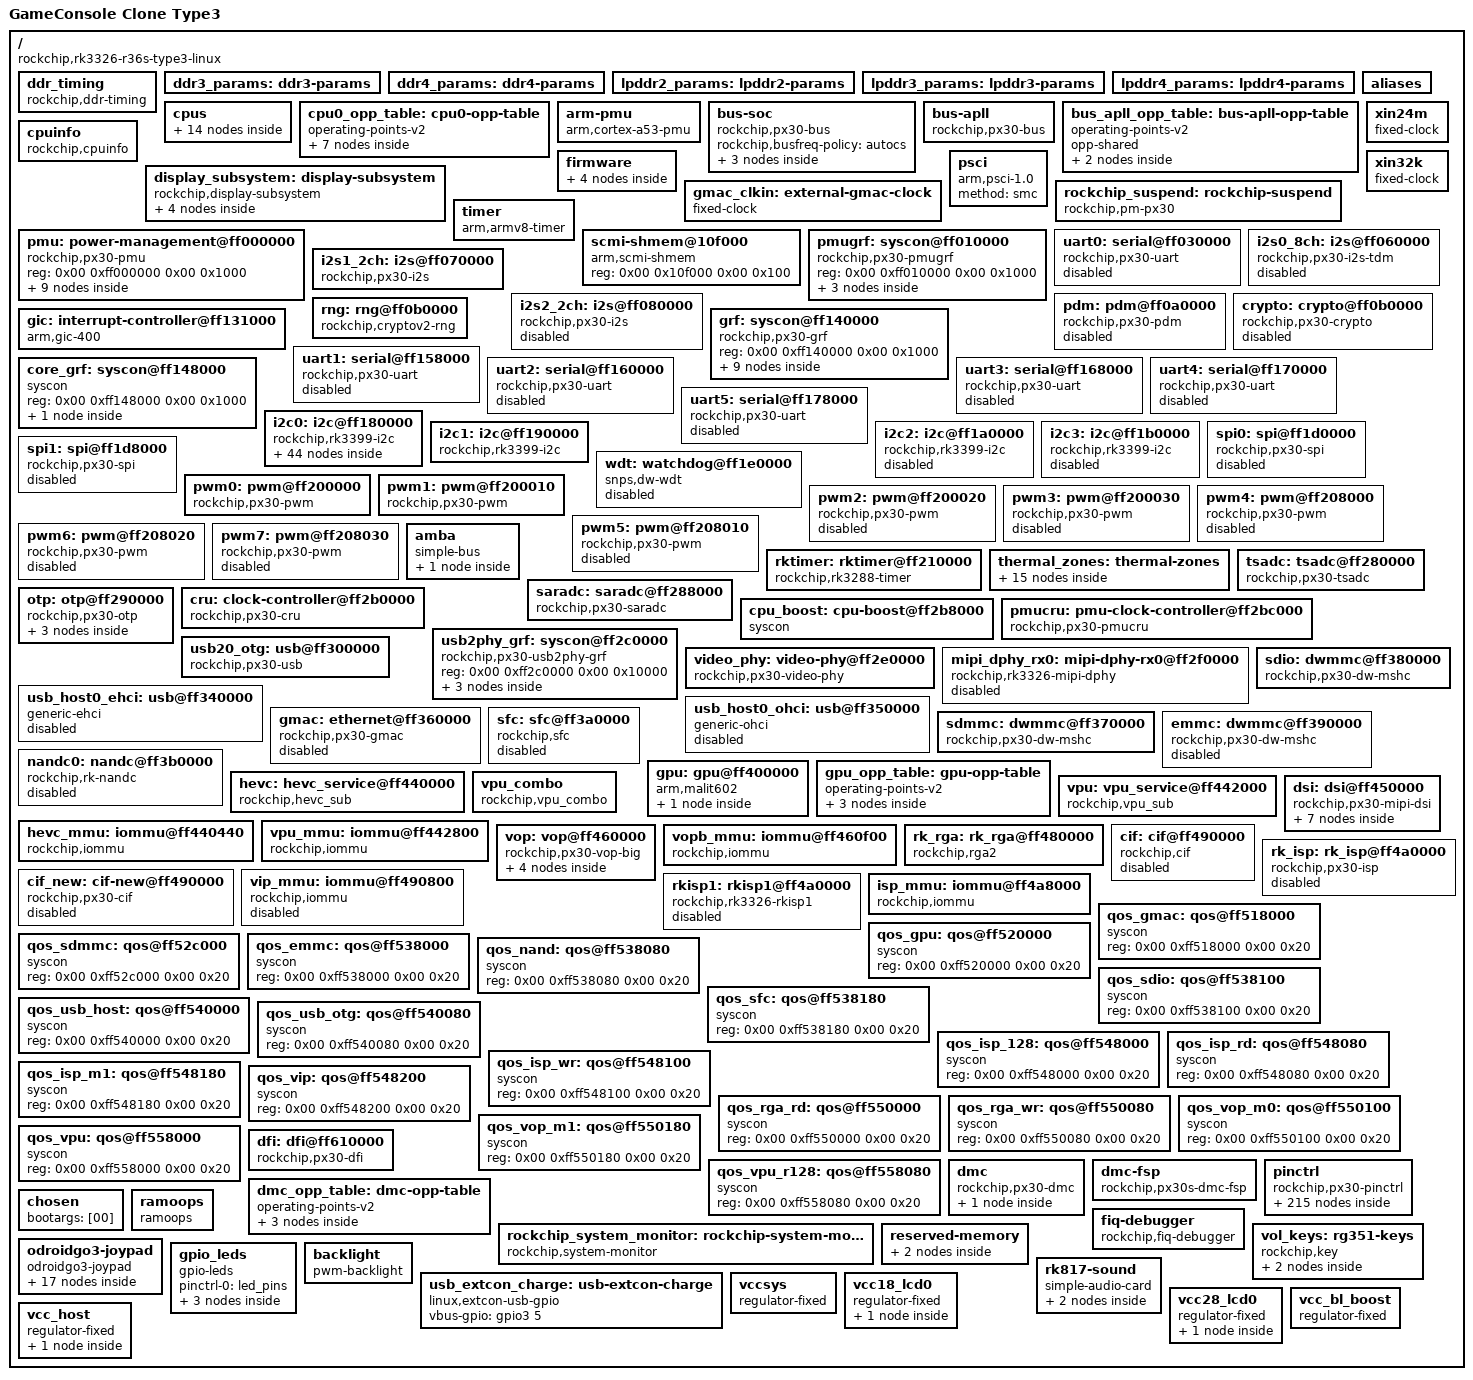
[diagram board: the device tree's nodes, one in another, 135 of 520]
/dts-v1/;

/ {
	compatible = "rockchip,rk3326-r36s-type3-linux", "rockchip,rk3326";
	interrupt-parent = <&gic>;
	#address-cells = <2>;
	#size-cells = <2>;
	model = "GameConsole Clone Type3";
	
	/*chosen {
		stdout-path = "serial5:115200n8";
	};*/

	ddr_timing: ddr_timing {
	compatible = "rockchip,ddr-timing";
		ddr2_speed_bin = <0x00>;
		ddr3_speed_bin = <0x15>;
		ddr4_speed_bin = <0x0c>;
		pd_idle = <0x0d>;
		sr_idle = <0x5d>;
		sr_mc_gate_idle = <0x00>;
		srpd_lite_idle = <0x00>;
		standby_idle = <0x00>;
		auto_pd_dis_freq = <0x42a>;
		auto_sr_dis_freq = <0x320>;
		ddr2_dll_dis_freq = <0x12c>;
		ddr3_dll_dis_freq = <0x12c>;
		ddr4_dll_dis_freq = <0x271>;
		phy_dll_dis_freq = <0x190>;
		ddr2_odt_dis_freq = <0x64>;
		phy_ddr2_odt_dis_freq = <0x64>;
		ddr2_drv = <0x01>;
		ddr2_odt = <0x96>;
		phy_ddr2_ca_drv = <0x15>;
		phy_ddr2_ck_drv = <0x12>;
		phy_ddr2_dq_drv = <0x15>;
		phy_ddr2_odt = <0x02>;
		ddr3_odt_dis_freq = <0x190>;
		phy_ddr3_odt_dis_freq = <0x190>;
		ddr3_drv = <0x28>;
		ddr3_odt = <0x78>;
		phy_ddr3_ca_drv = <0x15>;
		phy_ddr3_ck_drv = <0x12>;
		phy_ddr3_dq_drv = <0x15>;
		phy_ddr3_odt = <0x02>;
		phy_lpddr2_odt_dis_freq = <0x29a>;
		lpddr2_drv = <0x28>;
		phy_lpddr2_ca_drv = <0x16>;
		phy_lpddr2_ck_drv = <0x13>;
		phy_lpddr2_dq_drv = <0x16>;
		phy_lpddr2_odt = <0x00>;
		lpddr3_odt_dis_freq = <0x190>;
		phy_lpddr3_odt_dis_freq = <0x190>;
		lpddr3_drv = <0x28>;
		lpddr3_odt = <0xf0>;
		phy_lpddr3_ca_drv = <0x16>;
		phy_lpddr3_ck_drv = <0x13>;
		phy_lpddr3_dq_drv = <0x16>;
		phy_lpddr3_odt = <0x02>;
		lpddr4_odt_dis_freq = <0x320>;
		phy_lpddr4_odt_dis_freq = <0x320>;
		lpddr4_drv = <0x3c>;
		lpddr4_dq_odt = <0x28>;
		lpddr4_ca_odt = <0x28>;
		phy_lpddr4_ca_drv = <0x14>;
		phy_lpddr4_ck_cs_drv = <0x06>;
		phy_lpddr4_dq_drv = <0x06>;
		phy_lpddr4_odt = <0x10>;
		ddr4_odt_dis_freq = <0x29a>;
		phy_ddr4_odt_dis_freq = <0x29a>;
		ddr4_drv = <0x22>;
		ddr4_odt = <0xf0>;
		phy_ddr4_ca_drv = <0x16>;
		phy_ddr4_ck_drv = <0x13>;
		phy_ddr4_dq_drv = <0x16>;
		phy_ddr4_odt = <0x02>;
		ddr3a1_ddr4a9_de-skew = <0x06>;
		ddr3a0_ddr4a10_de-skew = <0x07>;
		ddr3a3_ddr4a6_de-skew = <0x07>;
		ddr3a2_ddr4a4_de-skew = <0x07>;
		ddr3a5_ddr4a8_de-skew = <0x07>;
		ddr3a4_ddr4a5_de-skew = <0x07>;
		ddr3a7_ddr4a11_de-skew = <0x07>;
		ddr3a6_ddr4a7_de-skew = <0x06>;
		ddr3a9_ddr4a0_de-skew = <0x07>;
		ddr3a8_ddr4a13_de-skew = <0x07>;
		ddr3a11_ddr4a3_de-skew = <0x07>;
		ddr3a10_ddr4cs0_de-skew = <0x07>;
		ddr3a13_ddr4a2_de-skew = <0x07>;
		ddr3a12_ddr4ba1_de-skew = <0x07>;
		ddr3a15_ddr4odt0_de-skew = <0x07>;
		ddr3a14_ddr4a1_de-skew = <0x07>;
		ddr3ba1_ddr4a15_de-skew = <0x07>;
		ddr3ba0_ddr4bg0_de-skew = <0x07>;
		ddr3ras_ddr4cke_de-skew = <0x07>;
		ddr3ba2_ddr4ba0_de-skew = <0x07>;
		ddr3we_ddr4bg1_de-skew = <0x07>;
		ddr3cas_ddr4a12_de-skew = <0x07>;
		ddr3ckn_ddr4ckn_de-skew = <0x07>;
		ddr3ckp_ddr4ckp_de-skew = <0x07>;
		ddr3cke_ddr4a16_de-skew = <0x07>;
		ddr3odt0_ddr4a14_de-skew = <0x07>;
		ddr3cs0_ddr4act_de-skew = <0x06>;
		ddr3reset_ddr4reset_de-skew = <0x07>;
		ddr3cs1_ddr4cs1_de-skew = <0x06>;
		ddr3odt1_ddr4odt1_de-skew = <0x07>;
		cs0_dm0_rx_de-skew = <0x07>;
		cs0_dm0_tx_de-skew = <0x07>;
		cs0_dq0_rx_de-skew = <0x08>;
		cs0_dq0_tx_de-skew = <0x08>;
		cs0_dq1_rx_de-skew = <0x09>;
		cs0_dq1_tx_de-skew = <0x08>;
		cs0_dq2_rx_de-skew = <0x08>;
		cs0_dq2_tx_de-skew = <0x08>;
		cs0_dq3_rx_de-skew = <0x08>;
		cs0_dq3_tx_de-skew = <0x08>;
		cs0_dq4_rx_de-skew = <0x09>;
		cs0_dq4_tx_de-skew = <0x08>;
		cs0_dq5_rx_de-skew = <0x09>;
		cs0_dq5_tx_de-skew = <0x08>;
		cs0_dq6_rx_de-skew = <0x09>;
		cs0_dq6_tx_de-skew = <0x08>;
		cs0_dq7_rx_de-skew = <0x08>;
		cs0_dq7_tx_de-skew = <0x08>;
		cs0_dqs0_rx_de-skew = <0x06>;
		cs0_dqs0p_tx_de-skew = <0x09>;
		cs0_dqs0n_tx_de-skew = <0x09>;
		cs0_dm1_rx_de-skew = <0x07>;
		cs0_dm1_tx_de-skew = <0x06>;
		cs0_dq8_rx_de-skew = <0x08>;
		cs0_dq8_tx_de-skew = <0x07>;
		cs0_dq9_rx_de-skew = <0x09>;
		cs0_dq9_tx_de-skew = <0x07>;
		cs0_dq10_rx_de-skew = <0x08>;
		cs0_dq10_tx_de-skew = <0x08>;
		cs0_dq11_rx_de-skew = <0x08>;
		cs0_dq11_tx_de-skew = <0x07>;
		cs0_dq12_rx_de-skew = <0x08>;
		cs0_dq12_tx_de-skew = <0x08>;
		cs0_dq13_rx_de-skew = <0x09>;
		cs0_dq13_tx_de-skew = <0x07>;
		cs0_dq14_rx_de-skew = <0x09>;
		cs0_dq14_tx_de-skew = <0x08>;
		cs0_dq15_rx_de-skew = <0x09>;
		cs0_dq15_tx_de-skew = <0x07>;
		cs0_dqs1_rx_de-skew = <0x07>;
		cs0_dqs1p_tx_de-skew = <0x09>;
		cs0_dqs1n_tx_de-skew = <0x09>;
		cs0_dm2_rx_de-skew = <0x07>;
		cs0_dm2_tx_de-skew = <0x07>;
		cs0_dq16_rx_de-skew = <0x09>;
		cs0_dq16_tx_de-skew = <0x09>;
		cs0_dq17_rx_de-skew = <0x07>;
		cs0_dq17_tx_de-skew = <0x09>;
		cs0_dq18_rx_de-skew = <0x07>;
		cs0_dq18_tx_de-skew = <0x08>;
		cs0_dq19_rx_de-skew = <0x07>;
		cs0_dq19_tx_de-skew = <0x09>;
		cs0_dq20_rx_de-skew = <0x09>;
		cs0_dq20_tx_de-skew = <0x09>;
		cs0_dq21_rx_de-skew = <0x09>;
		cs0_dq21_tx_de-skew = <0x09>;
		cs0_dq22_rx_de-skew = <0x08>;
		cs0_dq22_tx_de-skew = <0x09>;
		cs0_dq23_rx_de-skew = <0x08>;
		cs0_dq23_tx_de-skew = <0x09>;
		cs0_dqs2_rx_de-skew = <0x06>;
		cs0_dqs2p_tx_de-skew = <0x09>;
		cs0_dqs2n_tx_de-skew = <0x09>;
		cs0_dm3_rx_de-skew = <0x07>;
		cs0_dm3_tx_de-skew = <0x07>;
		cs0_dq24_rx_de-skew = <0x08>;
		cs0_dq24_tx_de-skew = <0x08>;
		cs0_dq25_rx_de-skew = <0x09>;
		cs0_dq25_tx_de-skew = <0x09>;
		cs0_dq26_rx_de-skew = <0x09>;
		cs0_dq26_tx_de-skew = <0x08>;
		cs0_dq27_rx_de-skew = <0x09>;
		cs0_dq27_tx_de-skew = <0x08>;
		cs0_dq28_rx_de-skew = <0x09>;
		cs0_dq28_tx_de-skew = <0x09>;
		cs0_dq29_rx_de-skew = <0x09>;
		cs0_dq29_tx_de-skew = <0x09>;
		cs0_dq30_rx_de-skew = <0x08>;
		cs0_dq30_tx_de-skew = <0x08>;
		cs0_dq31_rx_de-skew = <0x08>;
		cs0_dq31_tx_de-skew = <0x08>;
		cs0_dqs3_rx_de-skew = <0x07>;
		cs0_dqs3p_tx_de-skew = <0x09>;
		cs0_dqs3n_tx_de-skew = <0x09>;
		cs1_dm0_rx_de-skew = <0x07>;
		cs1_dm0_tx_de-skew = <0x07>;
		cs1_dq0_rx_de-skew = <0x08>;
		cs1_dq0_tx_de-skew = <0x08>;
		cs1_dq1_rx_de-skew = <0x09>;
		cs1_dq1_tx_de-skew = <0x08>;
		cs1_dq2_rx_de-skew = <0x08>;
		cs1_dq2_tx_de-skew = <0x08>;
		cs1_dq3_rx_de-skew = <0x08>;
		cs1_dq3_tx_de-skew = <0x08>;
		cs1_dq4_rx_de-skew = <0x08>;
		cs1_dq4_tx_de-skew = <0x08>;
		cs1_dq5_rx_de-skew = <0x09>;
		cs1_dq5_tx_de-skew = <0x08>;
		cs1_dq6_rx_de-skew = <0x09>;
		cs1_dq6_tx_de-skew = <0x08>;
		cs1_dq7_rx_de-skew = <0x08>;
		cs1_dq7_tx_de-skew = <0x08>;
		cs1_dqs0_rx_de-skew = <0x06>;
		cs1_dqs0p_tx_de-skew = <0x09>;
		cs1_dqs0n_tx_de-skew = <0x09>;
		cs1_dm1_rx_de-skew = <0x07>;
		cs1_dm1_tx_de-skew = <0x07>;
		cs1_dq8_rx_de-skew = <0x08>;
		cs1_dq8_tx_de-skew = <0x08>;
		cs1_dq9_rx_de-skew = <0x08>;
		cs1_dq9_tx_de-skew = <0x07>;
		cs1_dq10_rx_de-skew = <0x07>;
		cs1_dq10_tx_de-skew = <0x08>;
		cs1_dq11_rx_de-skew = <0x08>;
		cs1_dq11_tx_de-skew = <0x08>;
		cs1_dq12_rx_de-skew = <0x08>;
		cs1_dq12_tx_de-skew = <0x07>;
		cs1_dq13_rx_de-skew = <0x08>;
		cs1_dq13_tx_de-skew = <0x08>;
		cs1_dq14_rx_de-skew = <0x08>;
		cs1_dq14_tx_de-skew = <0x08>;
		cs1_dq15_rx_de-skew = <0x08>;
		cs1_dq15_tx_de-skew = <0x07>;
		cs1_dqs1_rx_de-skew = <0x07>;
		cs1_dqs1p_tx_de-skew = <0x09>;
		cs1_dqs1n_tx_de-skew = <0x09>;
		cs1_dm2_rx_de-skew = <0x07>;
		cs1_dm2_tx_de-skew = <0x08>;
		cs1_dq16_rx_de-skew = <0x08>;
		cs1_dq16_tx_de-skew = <0x09>;
		cs1_dq17_rx_de-skew = <0x08>;
		cs1_dq17_tx_de-skew = <0x09>;
		cs1_dq18_rx_de-skew = <0x07>;
		cs1_dq18_tx_de-skew = <0x08>;
		cs1_dq19_rx_de-skew = <0x08>;
		cs1_dq19_tx_de-skew = <0x09>;
		cs1_dq20_rx_de-skew = <0x09>;
		cs1_dq20_tx_de-skew = <0x09>;
		cs1_dq21_rx_de-skew = <0x09>;
		cs1_dq21_tx_de-skew = <0x09>;
		cs1_dq22_rx_de-skew = <0x08>;
		cs1_dq22_tx_de-skew = <0x09>;
		cs1_dq23_rx_de-skew = <0x08>;
		cs1_dq23_tx_de-skew = <0x09>;
		cs1_dqs2_rx_de-skew = <0x06>;
		cs1_dqs2p_tx_de-skew = <0x09>;
		cs1_dqs2n_tx_de-skew = <0x09>;
		cs1_dm3_rx_de-skew = <0x07>;
		cs1_dm3_tx_de-skew = <0x07>;
		cs1_dq24_rx_de-skew = <0x08>;
		cs1_dq24_tx_de-skew = <0x09>;
		cs1_dq25_rx_de-skew = <0x09>;
		cs1_dq25_tx_de-skew = <0x09>;
		cs1_dq26_rx_de-skew = <0x09>;
		cs1_dq26_tx_de-skew = <0x08>;
		cs1_dq27_rx_de-skew = <0x08>;
		cs1_dq27_tx_de-skew = <0x08>;
		cs1_dq28_rx_de-skew = <0x09>;
		cs1_dq28_tx_de-skew = <0x09>;
		cs1_dq29_rx_de-skew = <0x09>;
		cs1_dq29_tx_de-skew = <0x09>;
		cs1_dq30_rx_de-skew = <0x09>;
		cs1_dq30_tx_de-skew = <0x08>;
		cs1_dq31_rx_de-skew = <0x08>;
		cs1_dq31_tx_de-skew = <0x08>;
		cs1_dqs3_rx_de-skew = <0x07>;
		cs1_dqs3p_tx_de-skew = <0x09>;
		cs1_dqs3n_tx_de-skew = <0x09>;
		//phandle = <0xb4>;
	};

	ddr3_params: ddr3-params {
		version = <0x101>;
		expanded_version = <0x00>;
		reserved = <0x00>;
		freq_0 = <0x210>;
		freq_1 = <0x148>;
		freq_2 = <0x210>;
		freq_3 = <0x210>;
		freq_4 = <0x00>;
		freq_5 = <0x00>;
		pd_idle = <0x0d>;
		sr_idle = <0x5d>;
		sr_mc_gate_idle = <0x00>;
		srpd_lite_idle = <0x00>;
		standby_idle = <0x00>;
		pd_dis_freq = <0x42a>;
		sr_dis_freq = <0x320>;
		dram_dll_dis_freq = <0x12c>;
		phy_dll_dis_freq = <0x00>;
		phy_dq_drv_odten = <0x21>;
		phy_ca_drv_odten = <0x21>;
		phy_clk_drv_odten = <0x21>;
		dram_dq_drv_odten = <0x22>;
		phy_dq_drv_odtoff = <0x21>;
		phy_ca_drv_odtoff = <0x21>;
		phy_clk_drv_odtoff = <0x21>;
		dram_dq_drv_odtoff = <0x22>;
		dram_odt = <0x78>;
		phy_odt = <0x85>;
		phy_odt_puup_en = <0x01>;
		phy_odt_pudn_en = <0x01>;
		dram_dq_odt_en_freq = <0x14d>;
		phy_odt_en_freq = <0x14d>;
		phy_dq_sr_odten = <0x0f>;
		phy_ca_sr_odten = <0x03>;
		phy_clk_sr_odten = <0x03>;
		phy_dq_sr_odtoff = <0x0f>;
		phy_ca_sr_odtoff = <0x03>;
		phy_clk_sr_odtoff = <0x03>;
		ssmod_downspread = <0x00>;
		ssmod_div = <0x00>;
		ssmod_spread = <0x00>;
		mode_2t = <0x00>;
		speed_bin = <0x15>;
		dram_ext_temp = <0x00>;
		byte_map = <0xb1>;
		dq_map_cs0_dq_l = <0x00>;
		dq_map_cs0_dq_h = <0x00>;
		dq_map_cs1_dq_l = <0x00>;
		dq_map_cs1_dq_h = <0x00>;
		//phandle = <0xb2>;
	};

	ddr4_params: ddr4-params {
		version = <0x101>;
		expanded_version = <0x00>;
		reserved = <0x00>;
		freq_0 = <0x312>;
		freq_1 = <0x148>;
		freq_2 = <0x29a>;
		freq_3 = <0x312>;
		freq_4 = <0x00>;
		freq_5 = <0x00>;
		pd_idle = <0x0d>;
		sr_idle = <0x5d>;
		sr_mc_gate_idle = <0x00>;
		srpd_lite_idle = <0x00>;
		standby_idle = <0x00>;
		pd_dis_freq = <0x42a>;
		sr_dis_freq = <0x320>;
		dram_dll_dis_freq = <0x1f4>;
		phy_dll_dis_freq = <0x00>;
		phy_dq_drv_odten = <0x21>;
		phy_ca_drv_odten = <0x21>;
		phy_clk_drv_odten = <0x21>;
		dram_dq_drv_odten = <0x22>;
		phy_dq_drv_odtoff = <0x21>;
		phy_ca_drv_odtoff = <0x21>;
		phy_clk_drv_odtoff = <0x21>;
		dram_dq_drv_odtoff = <0x22>;
		dram_odt = <0x78>;
		phy_odt = <0x79>;
		phy_odt_puup_en = <0x01>;
		phy_odt_pudn_en = <0x01>;
		dram_dq_odt_en_freq = <0x1f4>;
		phy_odt_en_freq = <0x1f4>;
		phy_dq_sr_odten = <0x0e>;
		phy_ca_sr_odten = <0x01>;
		phy_clk_sr_odten = <0x01>;
		phy_dq_sr_odtoff = <0x0e>;
		phy_ca_sr_odtoff = <0x01>;
		phy_clk_sr_odtoff = <0x01>;
		ssmod_downspread = <0x00>;
		ssmod_div = <0x00>;
		ssmod_spread = <0x00>;
		mode_2t = <0x00>;
		speed_bin = <0x0c>;
		dram_ext_temp = <0x00>;
		byte_map = <0xb1>;
		dq_map_cs0_dq_l = <0x139b6273>;
		dq_map_cs0_dq_h = <0x272d6f42>;
		dq_map_cs1_dq_l = <0x46ce3726>;
		dq_map_cs1_dq_h = <0x72783a17>;
		//phandle = <0xb3>;
	};

	lpddr2_params: lpddr2-params {
		version = <0x101>;
		expanded_version = <0x00>;
		reserved = <0x00>;
		freq_0 = <0x210>;
		freq_1 = <0x148>;
		freq_2 = <0x1c2>;
		freq_3 = <0x210>;
		freq_4 = <0x00>;
		freq_5 = <0x00>;
		pd_idle = <0x0d>;
		sr_idle = <0x5d>;
		sr_mc_gate_idle = <0x00>;
		srpd_lite_idle = <0x00>;
		standby_idle = <0x00>;
		pd_dis_freq = <0x42a>;
		sr_dis_freq = <0x320>;
		dram_dll_dis_freq = <0x00>;
		phy_dll_dis_freq = <0x00>;
		phy_dq_drv_odten = <0x21>;
		phy_ca_drv_odten = <0x21>;
		phy_clk_drv_odten = <0x21>;
		dram_dq_drv_odten = <0x22>;
		phy_dq_drv_odtoff = <0x21>;
		phy_ca_drv_odtoff = <0x21>;
		phy_clk_drv_odtoff = <0x21>;
		dram_dq_drv_odtoff = <0x22>;
		dram_odt = <0x00>;
		phy_odt = <0x00>;
		phy_odt_puup_en = <0x00>;
		phy_odt_pudn_en = <0x00>;
		dram_dq_odt_en_freq = <0x271>;
		phy_odt_en_freq = <0x271>;
		phy_dq_sr_odten = <0x0e>;
		phy_ca_sr_odten = <0x01>;
		phy_clk_sr_odten = <0x01>;
		phy_dq_sr_odtoff = <0x0e>;
		phy_ca_sr_odtoff = <0x01>;
		phy_clk_sr_odtoff = <0x01>;
		ssmod_downspread = <0x00>;
		ssmod_div = <0x00>;
		ssmod_spread = <0x00>;
		mode_2t = <0x00>;
		speed_bin = <0x00>;
		dram_ext_temp = <0x00>;
		byte_map = <0xe4>;
		dq_map_cs0_dq_l = <0x00>;
		dq_map_cs0_dq_h = <0x00>;
		dq_map_cs1_dq_l = <0x00>;
		dq_map_cs1_dq_h = <0x00>;
		//phandle = <0xb4>;
	};

	lpddr3_params: lpddr3-params {
		version = <0x101>;
		expanded_version = <0x00>;
		reserved = <0x00>;
		freq_0 = <0x210>;
		freq_1 = <0x148>;
		freq_2 = <0x210>;
		freq_3 = <0x210>;
		freq_4 = <0x00>;
		freq_5 = <0x00>;
		pd_idle = <0x0d>;
		sr_idle = <0x5d>;
		sr_mc_gate_idle = <0x00>;
		srpd_lite_idle = <0x00>;
		standby_idle = <0x00>;
		pd_dis_freq = <0x42a>;
		sr_dis_freq = <0x320>;
		dram_dll_dis_freq = <0x00>;
		phy_dll_dis_freq = <0x00>;
		phy_dq_drv_odten = <0x21>;
		phy_ca_drv_odten = <0x21>;
		phy_clk_drv_odten = <0x21>;
		dram_dq_drv_odten = <0x22>;
		phy_dq_drv_odtoff = <0x21>;
		phy_ca_drv_odtoff = <0x21>;
		phy_clk_drv_odtoff = <0x21>;
		dram_dq_drv_odtoff = <0x22>;
		dram_odt = <0xf0>;
		phy_odt = <0x79>;
		phy_odt_puup_en = <0x01>;
		phy_odt_pudn_en = <0x01>;
		dram_dq_odt_en_freq = <0x14d>;
		phy_odt_en_freq = <0x14d>;
		phy_dq_sr_odten = <0x00>;
		phy_ca_sr_odten = <0x00>;
		phy_clk_sr_odten = <0x00>;
		phy_dq_sr_odtoff = <0x00>;
		phy_ca_sr_odtoff = <0x00>;
		phy_clk_sr_odtoff = <0x00>;
		ssmod_downspread = <0x00>;
		ssmod_div = <0x00>;
		ssmod_spread = <0x00>;
		mode_2t = <0x00>;
		speed_bin = <0x00>;
		dram_ext_temp = <0x00>;
		byte_map = <0xe4>;
		dq_map_cs0_dq_l = <0x00>;
		dq_map_cs0_dq_h = <0x00>;
		dq_map_cs1_dq_l = <0x00>;
		dq_map_cs1_dq_h = <0x00>;
		//phandle = <0xb5>;
	};

	lpddr4_params: lpddr4-params {
		version = <0x101>;
		expanded_version = <0x00>;
		reserved = <0x00>;
		freq_0 = <0x312>;
		freq_1 = <0x148>;
		freq_2 = <0x29a>;
		freq_3 = <0x312>;
		freq_4 = <0x00>;
		freq_5 = <0x00>;
		pd_idle = <0x0d>;
		sr_idle = <0x5d>;
		sr_mc_gate_idle = <0x00>;
		srpd_lite_idle = <0x00>;
		standby_idle = <0x00>;
		pd_dis_freq = <0x42a>;
		sr_dis_freq = <0x320>;
		dram_dll_dis_freq = <0x00>;
		phy_dll_dis_freq = <0x00>;
		phy_dq_drv_odten = <0x23>;
		phy_ca_drv_odten = <0x26>;
		phy_clk_drv_odten = <0x2f>;
		dram_dq_drv_odten = <0x28>;
		phy_dq_drv_odtoff = <0x23>;
		phy_ca_drv_odtoff = <0x26>;
		phy_clk_drv_odtoff = <0x2f>;
		dram_dq_drv_odtoff = <0x28>;
		dram_odt = <0x3c>;
		phy_odt = <0x50>;
		phy_odt_puup_en = <0x00>;
		phy_odt_pudn_en = <0x00>;
		dram_dq_odt_en_freq = <0x320>;
		phy_odt_en_freq = <0x320>;
		phy_dq_sr_odten = <0x0f>;
		phy_ca_sr_odten = <0x01>;
		phy_clk_sr_odten = <0x01>;
		phy_dq_sr_odtoff = <0x0f>;
		phy_ca_sr_odtoff = <0x01>;
		phy_clk_sr_odtoff = <0x01>;
		ssmod_downspread = <0x00>;
		ssmod_div = <0x00>;
		ssmod_spread = <0x00>;
		mode_2t = <0x00>;
		speed_bin = <0x00>;
		dram_ext_temp = <0x00>;
		byte_map = <0xe4>;
		dq_map_cs0_dq_l = <0x00>;
		dq_map_cs0_dq_h = <0x00>;
		dq_map_cs1_dq_l = <0x00>;
		dq_map_cs1_dq_h = <0x00>;
		lp4_ca_odt = <0x78>;
		lp4_drv_pu_cal_odten = <0x00>;
		lp4_drv_pu_cal_odtoff = <0x00>;
		phy_lp4_drv_pulldown_en_odten = <0x00>;
		phy_lp4_drv_pulldown_en_odtoff = <0x00>;
		lp4_ca_odt_en_freq = <0x320>;
		phy_lp4_cs_drv_odten = <0x00>;
		phy_lp4_cs_drv_odtoff = <0x00>;
		lp4_odte_ck_en = <0x01>;
		lp4_odte_cs_en = <0x01>;
		lp4_odtd_ca_en = <0x00>;
		phy_lp4_dq_vref_odten = <0xc8>;
		lp4_dq_vref_odten = <0x13c>;
		lp4_ca_vref_odten = <0x17c>;
		phy_lp4_dq_vref_odtoff = <0x12c>;
		lp4_dq_vref_odtoff = <0x1a4>;
		lp4_ca_vref_odtoff = <0x1a4>;
		//phandle = <0xb6>;
	};

	aliases {
		ethernet0 = "/ethernet@ff360000";
		i2c0 = "/i2c@ff180000";
		i2c1 = "/i2c@ff190000";
		i2c2 = "/i2c@ff1a0000";
		i2c3 = "/i2c@ff1b0000";
		serial0 = "/serial@ff030000";
		serial1 = "/serial@ff158000";
		serial2 = "/serial@ff160000";
		//serial3 = "/serial@ff168000";
		//serial4 = "/serial@ff170000";
		serial5 = "/serial@ff178000";
		spi0 = "/spi@ff1d0000";
		spi1 = "/spi@ff1d8000";
		mmc0 = "/dwmmc@ff370000";
		mmc1 = "/dwmmc@ff380000";
	};

	cpus {
		#address-cells = <2>;
		#size-cells = <0>;
		cpu-map {
			cluster0 {	/* Cortex-A35 */
					core0 {
						cpu = <&cpu0>;
					};
					core1 {
						cpu = <&cpu1>;
					};
					core2 {
						cpu = <&cpu2>;
					};
					core3 {
						cpu = <&cpu3>;
					};
			};
		};
		
		cpu0: cpu@0 {//256KB unified system L2 cache, Integrated 32KB L1 instruction cache, 32KB L1 data cache with 4-way set associative
			device_type = "cpu";
			compatible = "arm,cortex-a35", "arm,armv8";
			reg = <0x00 0x00>;
			enable-method = "psci";
			i-cache-size = <0x8000>;
			i-cache-line-size = <64>;
			i-cache-sets = <256>;
			d-cache-size = <0x8000>;
			d-cache-line-size = <64>;
			d-cache-sets = <128>;
			next-level-cache = <&l2_0>;
			clocks = <&cru 0x07>;
			#cooling-cells = <2>;
			dynamic-power-coefficient = <90>;
			operating-points-v2 = <&cpu0_opp_table>;
			cpu-idle-states = <&CPU_SLEEP &CLUSTER_SLEEP>;
			cpu-supply = <&vdd_arm>;
			//phandle = <0x09>;
		};

		cpu1: cpu@1 {
			device_type = "cpu";
			compatible = "arm,cortex-a35", "arm,armv8";
			reg = <0x00 0x01>;
			enable-method = "psci";
			i-cache-size = <0x8000>;
			i-cache-line-size = <64>;
			i-cache-sets = <256>;
			d-cache-size = <0x8000>;
			d-cache-line-size = <64>;
			d-cache-sets = <128>;
			next-level-cache = <&l2_0>;
			//clocks = <&cru 0x07>;
			//#cooling-cells = <2>;
			//dynamic-power-coefficient = <90>;
			operating-points-v2 = <&cpu0_opp_table>;
			cpu-idle-states = <&CPU_SLEEP &CLUSTER_SLEEP>;
			cpu-supply = <&vdd_arm>;
			//phandle = <0x0a>;
		};

		cpu2: cpu@2 {
			device_type = "cpu";
			compatible = "arm,cortex-a35", "arm,armv8";
			reg = <0x00 0x02>;
			enable-method = "psci";
			i-cache-size = <0x8000>;
			i-cache-line-size = <64>;
			i-cache-sets = <256>;
			d-cache-size = <0x8000>;
			d-cache-line-size = <64>;
			d-cache-sets = <128>;
			next-level-cache = <&l2_0>;
			//clocks = <&cru 0x07>;
			//#cooling-cells = <2>;
			//dynamic-power-coefficient = <90>;
			operating-points-v2 = <&cpu0_opp_table>;
			cpu-idle-states = <&CPU_SLEEP &CLUSTER_SLEEP>;
			cpu-supply = <&vdd_arm>;
			//phandle = <0x0b>;
		};

		cpu3: cpu@3 {
			device_type = "cpu";
			compatible = "arm,cortex-a35", "arm,armv8";
			reg = <0x00 0x03>;
			enable-method = "psci";
			i-cache-size = <0x8000>;
			i-cache-line-size = <64>;
			i-cache-sets = <256>;
			d-cache-size = <0x8000>;
			d-cache-line-size = <64>;
			d-cache-sets = <128>;
			next-level-cache = <&l2_0>;
			//clocks = <&cru 0x07>;
			//#cooling-cells = <2>;
			//dynamic-power-coefficient = <90>;
			operating-points-v2 = <&cpu0_opp_table>;
			cpu-idle-states = <&CPU_SLEEP &CLUSTER_SLEEP>;
			cpu-supply = <&vdd_arm>;
			//phandle = <0x0c>;
		};

		l2_0: l2-cache {
			compatible = "cache,arm,arch-cache";
			cache-level = <2>;
			cache-unified;
			cache-size = <0x40000>;
			cache-line-size = <64>;
			cache-sets = <256>;
		};

		idle-states {
			entry-method = "psci";

			CPU_SLEEP: cpu-sleep {
				compatible = "arm,idle-state";
				local-timer-stop;
				arm,psci-suspend-param = <0x10000>;
				entry-latency-us = <0x78>;
				exit-latency-us = <0xfa>;
				min-residency-us = <0x384>;
				//phandle = <0x04>;
			};

			CLUSTER_SLEEP: cluster-sleep {
				compatible = "arm,idle-state";
				local-timer-stop;
				arm,psci-suspend-param = <0x1010000>;
				entry-latency-us = <0x190>;
				exit-latency-us = <0x1f4>;
				min-residency-us = <0x7d0>;
				//phandle = <0x05>;
			};
		};
	};

	cpu0_opp_table: cpu0-opp-table {
		compatible = "operating-points-v2";
		opp-shared;
		rockchip,temp-hysteresis = <0x1388>;
		rockchip,low-temp = <0x00>;
		rockchip,low-temp-min-volt = <1000000>;
		rockchip,low-temp-adjust-volt = <0x00 0x5e8 0xc350>;
		clocks = <&cru 0x01>;
		rockchip,avs-scale = <0x04>;
		rockchip,max-volt = <1350000>;
		rockchip,evb-irdrop = <25000>;
		nvmem-cells = <&cpu_leakage &performance>;
		nvmem-cell-names = "cpu_leakage", "performance";
		/* bin scaling clock 1.296MHz */
		rockchip,bin-scaling-sel = <0 13 1 13>;// 0x02 0x12>;
		rockchip,pvtm-voltage-sel = <0x00 0xc350 0x00 0xc351 0xd2f0 0x01 0xd2f1 0xea60 0x02 0xea61 0x1869f 0x03>;
		rockchip,pvtm-freq = <0x639c0>;
		rockchip,pvtm-volt = <1000000>;
		rockchip,pvtm-ch = <0x00 0x00>;
		rockchip,pvtm-sample-time = <0x3e8>;
		rockchip,pvtm-number = <0x0a>;
		rockchip,pvtm-error = <0x3e8>;
		rockchip,pvtm-ref-temp = <0x28>;
		rockchip,pvtm-temp-prop = <0xffffffc8 0xffffffc8>;
		rockchip,thermal-zone = "soc-thermal";
		rockchip,avs = <1>;
		//phandle = <0x03>;

		opp-408000000 {
			opp-hz = <0x00 0x18519600>;
			opp-microvolt = <950000 950000 1350000>;
			opp-microvolt-L0 = <950000 950000 1350000>;
			opp-microvolt-L1 = <950000 950000 1350000>;
			opp-microvolt-L2 = <950000 950000 1350000>;
			opp-microvolt-L3 = <950000 950000 1350000>;
			clock-latency-ns = <40000>;
			//opp-suspend;
		};

		opp-600000000 {
			opp-hz = <0x00 0x23c34600>;
			opp-microvolt = <950000 950000 1350000>;
			opp-microvolt-L0 = <950000 950000 1350000>;
			opp-microvolt-L1 = <950000 950000 1350000>;
			opp-microvolt-L2 = <950000 950000 1350000>;
			opp-microvolt-L3 = <950000 950000 1350000>;
			clock-latency-ns = <40000>;
		};

		/*opp-816000000 { //disabled for many boards
			opp-hz = <0x00 0x30a32c00>;
			opp-microvolt = <1050000 1050000 1350000>;
			opp-microvolt-L0 = <1050000 1050000 1350000>;
			opp-microvolt-L1 = <1000000 1000000 1350000>;
			opp-microvolt-L2 = <1000000 1000000 1350000>;
			opp-microvolt-L3 = <950000 950000 1350000>;
			clock-latency-ns = <40000>;
		};*/

		opp-1008000000 {
			opp-hz = <0x00 0x3c14dc00>;
			opp-microvolt = <0x11edd8 0x11edd8 1350000>;
			opp-microvolt-L0 = <0x11edd8 0x11edd8 1350000>;
			opp-microvolt-L1 = <1125000 1125000 1350000>;
			opp-microvolt-L2 = <1125000 1125000 1350000>;
			opp-microvolt-L3 = <1050000 1050000 1350000>;
			clock-latency-ns = <40000>;
		};

		opp-1200000000 {
			opp-hz = <0x00 0x47868c00>;
			opp-microvolt = <1300000 1300000 1350000>;
			opp-microvolt-L0 = <1300000 1300000 1350000>;
			opp-microvolt-L1 = <1275000 1275000 1350000>;
			opp-microvolt-L2 = <1250000 1250000 1350000>;
			opp-microvolt-L3 = <1200000 1200000 1350000>;
			clock-latency-ns = <40000>;
		};

		/*opp-1248000000 { //disabled? unstable?
			opp-hz = <0x00 0x4a62f800>;
			opp-microvolt = <1350000 1350000 1350000>;
			opp-microvolt-L0 = <1350000 1350000 1350000>;
			opp-microvolt-L1 = <1300000 1300000 1350000>;
			opp-microvolt-L2 = <1275000 1275000 1350000>;
			opp-microvolt-L3 = <1225000 1225000 1350000>;
			clock-latency-ns = <40000>;
		};*/

		opp-1296000000 {
			opp-hz = <0x00 0x4d3f6400>;
			opp-microvolt = <1350000 1350000 1350000>;
			opp-microvolt-L0 = <1350000 1350000 1350000>;
			opp-microvolt-L1 = <1350000 1350000 1350000>;
			opp-microvolt-L2 = <1300000 1300000 1350000>;
			opp-microvolt-L3 = <1250000 1250000 1350000>;
			clock-latency-ns = <40000>;
		};

		opp-1416000000 {
			opp-hz = <0x00 0x54667200>;
			opp-microvolt = <1350000 1350000 1350000>;
			opp-microvolt-L0 = <1350000 1350000 1350000>;
			opp-microvolt-L1 = <1350000 1350000 1350000>;
			opp-microvolt-L2 = <1300000 1300000 1350000>;
			opp-microvolt-L3 = <1250000 1250000 1350000>;
			clock-latency-ns = <40000>;
		};

		opp-1512000000 {
			opp-hz = <0x00 0x5a1f4a00>;
			opp-microvolt = <1350000 1350000 1350000>;
			opp-microvolt-L0 = <1350000 1350000 1350000>;
			opp-microvolt-L1 = <1350000 1350000 1350000>;
			opp-microvolt-L2 = <1300000 1300000 1350000>;
			opp-microvolt-L3 = <1250000 1250000 1350000>;
			clock-latency-ns = <40000>;
		};
	};

	arm-pmu {
		compatible = "arm,cortex-a53-pmu";
		interrupts = <0x00 0x64 0x04 0x00 0x65 0x04 0x00 0x66 0x04 0x00 0x67 0x04>;
		interrupt-affinity = <&cpu0 &cpu1 &cpu2 &cpu3>;
	};

	bus-soc {
		compatible = "rockchip,px30-bus";
		rockchip,busfreq-policy = "autocs";
		//phandle = <0xca>;

		soc-bus0 {
			bus-id = <0x00>;
			timer-us = <0x14>;
			enable-msk = <0x40f7>;
			status = "disabled";
		};

		soc-bus1 {
			bus-id = <0x01>;
			timer-us = <0xc8>;
			enable-msk = <0x40bf>;
			status = "disabled";
		};

		soc-bus2 {
			bus-id = <0x02>;
			timer-us = <0xc8>;
			enable-msk = <0x4007>;
			status = "disabled";
		};
	};

	bus-apll {
		compatible = "rockchip,px30-bus";
		rockchip,busfreq-policy = "clkfreq";
		clocks = <&cru 0x01>;
		clock-names = "bus";
		operating-points-v2 = <&bus_apll_opp_table>;
		status = "okay";
		bus-supply = <&vdd_logic>;
		//phandle = <0xcb>;
	};

	bus_apll_opp_table: bus-apll-opp-table {
		compatible = "operating-points-v2";
		opp-shared;
		//phandle = <0x0d>;

		opp-1512000000 {
			opp-hz = <0x00 0x5a1f4a00>;
			opp-microvolt = <1000000>;
		};

		opp-1008000000 {
			opp-hz = <0x00 0x3c14dc00>;
			opp-microvolt = <950000>;
		};
	};

	cpuinfo {
		compatible = "rockchip,cpuinfo";
		nvmem-cells = <&otp_id>;
		nvmem-cell-names = "id";
	};

	display_subsystem: display-subsystem {
		compatible = "rockchip,display-subsystem";
		ports = <&vopb_out>;
		status = "okay";
		logo-memory-region = <&drm_logo>;
		//phandle = <0xcc>;

		route {

			route_lvds: route-lvds {
				status = "disabled";
				logo,uboot = "logo.bmp";
				logo,kernel = "logo_kernel.bmp";
				logo,mode = "center";
				charge_logo,mode = "center";
				connect = <&vopb_out_lvds>;
				//phandle = <0xcd>;
			};

			route_dsi: route-dsi {
				status = "okay";
				logo,uboot = "logo.bmp";
				logo,kernel = "logo_kernel.bmp";
				logo,mode = "center";
				charge_logo,mode = "center";
				connect = <&vopb_out_dsi>;
				//phandle = <0xce>;
			};

			route_rgb: route-rgb {
				status = "disabled";
				logo,uboot = "logo.bmp";
				logo,kernel = "logo_kernel.bmp";
				logo,mode = "center";
				charge_logo,mode = "center";
				connect = <&vopb_out_rgb>;
				//phandle = <0xcf>;
			};
		};
	};

	firmware {

		optee {
			compatible = "linaro,optee-tz";
			method = "smc";
		};
		scmi {
			compatible = "arm,scmi-smc";
			shmem = <0x15>;
			arm,smc-id = <0x82000010>;
			#address-cells = <1>;
			#size-cells = <0>;

			protocol@14 {
				reg = <0x14>;
				#clock-cells = <1>;
			};
		};

		sdei {
			compatible = "arm,sdei-1.0";
			method = "smc";
		};
	};

	gmac_clkin: external-gmac-clock {
		compatible = "fixed-clock";
		clock-frequency = <0x2faf080>;
		clock-output-names = "gmac_clkin";
		#clock-cells = <0>;
	//	phandle = <0xd0>;
	};

	psci {
		compatible = "arm,psci-1.0";
		method = "smc";
	};

	rockchip_suspend: rockchip-suspend {
		compatible = "rockchip,pm-px30";
		status = "okay";
		rockchip,sleep-debug-en = <1>;
		rockchip,sleep-mode-config = <0x20702>;
		rockchip,wakeup-config = <0x85>;
		//phandle = <0xd1>;
	};

	timer {
		compatible = "arm,armv8-timer";
		interrupts = <0x01 0x0d 0xf04 0x01 0x0e 0xf04 0x01 0x0b 0xf04 0x01 0x0a 0xf04>;
	};

	xin24m: xin24m {
		compatible = "fixed-clock";
		#clock-cells = <0>;
		clock-frequency = <24000000>;
		clock-output-names = "xin24m";
		//phandle = <0xd2>;
	};

	xin32k: xin32k {
		compatible = "fixed-clock";
		#clock-cells = <0>;
		clock-frequency = <32768>;
		clock-output-names = "xin32k";
		//phandle = <0xd3>;
	};

	pmu: power-management@ff000000 {
		compatible = "rockchip,px30-pmu", "syscon", "simple-mfd";
		reg = <0x00 0xff000000 0x00 0x1000>;
		//phandle = <0xd4>;

		power: power-controller {
			compatible = "rockchip,px30-power-controller";
			#power-domain-cells = <1>;
			#address-cells = <1>;
			#size-cells = <0>;
			//phandle = <0x8b>;
			pd_vi-supply = <&vdd_logic>;
			pd_vpu-supply = <&vdd_logic>;
			pd_gpu-supply = <&vdd_logic>;
			pd_usb-supply = <&vdd_logic>;
			pd_mmc_nand-supply = <&vdd_logic>;
			pd_sdcard-supply = <&vdd_logic>;
			pd_vo-supply = <&vdd_logic>;
			pd_gmac-supply = <&vdd_logic>;

			pd_usb@5 {
				reg = <0x05>;
				clocks = <&cru 0x103>, <&cru 0x102>, <&cru 0x3c>;
				pm_qos = <&qos_usb_host &qos_usb_otg>;
			};

			pd_sdcard@7 {
				reg = <0x07>;
				clocks = <&cru 0xf7>, <&cru 0x3b>;
				pm_qos = <&qos_sdmmc>;
			};

			pd_gmac@9 {
				reg = <0x09>;
				clocks = <&cru 0xb2>, <&cru 0x143>, <&cru 0x40>, <&cru 0x3f>;
				pm_qos = <&qos_gmac>;
			};

			pd_mmc_nand@10 {
				reg = <0x0a>;
				clocks = <&cru 0xfe>, <&cru 0x100>, <&cru 0xff>, <&cru 0x101>, <&cru 0x39>, <&cru 0x37>, <&cru 0x38>, <&cru 0x3a>;
				pm_qos = <&qos_emmc &qos_nand &qos_sdio &qos_sfc>;
			};

			pd_vpu@11 {
				reg = <0x0b>;
				clocks = <&cru 0xaf>, <&cru 0xf4>, <&cru 0x4b>;
				pm_qos = <&qos_vpu &qos_vpu_r128>;
			};

			pd_vo@12 {
				reg = <0x0c>;
				clocks = <&cru 0xb7>, <&cru 0xb5>, <&cru 0xb6>, <&cru 0x96>, <&cru 0x97>, <&cru 0xfd>, <&cru 0xfb>, <&cru 0xfc>, <&cru 0x144>, <&cru 0x35>, <&cru 0x36>;
				pm_qos = <&qos_rga_rd &qos_rga_wr &qos_vop_m0 &qos_vop_m1>;
			};

			pd_vi@13 {
				reg = <0x0d>;
				clocks = <&cru 0xb3>, <&cru 0xb4>, <&cru 0xf9>, <&cru 0xfa>, <&cru 0x33>;
				pm_qos = <&qos_isp_128 &qos_isp_rd &qos_isp_wr &qos_isp_m1 &qos_vip>;
			};

			pd_gpu@14 {
				reg = <0x0e>;
				clocks = <&cru 0x49>;
				pm_qos = <&qos_gpu>;
			};
		};
	};

	scmi-shmem@10f000 {
		compatible = "arm,scmi-shmem";
		reg = <0x00 0x10f000 0x00 0x100>;
		//phandle = <0x15>;
	};

	pmugrf: syscon@ff010000 {
		compatible = "rockchip,px30-pmugrf", "syscon", "simple-mfd";
		reg = <0x00 0xff010000 0x00 0x1000>;
		#address-cells = <1>;
		#size-cells = <1>;
		//phandle = <0xb1>;

		pmu_io_domains: io-domains {
			compatible = "rockchip,px30-pmu-io-voltage-domain";
			status = "okay";
			pmuio1-supply = <&vcc3v0_pmu>; //
			pmuio2-supply = <&vcc3v0_pmu>; //i2c0 i2c1 pwm uart0
			//phandle = <0xd5>;
		};

		reboot-mode {
			compatible = "syscon-reboot-mode";
			offset = <0x200>;
			mode-bootloader = <0x5242c301>;
			mode-charge = <0x5242c30b>;
			mode-fastboot = <0x5242c309>;
			mode-loader = <0x5242c301>;
			mode-normal = <0x5242c300>;
			mode-recovery = <0x5242c303>;
			mode-ums = <0x5242c30c>;
		};

		pmu_pvtm: pmu-pvtm {
			compatible = "rockchip,px30-pmu-pvtm";
			clocks = <&pmucru 0x07>;
			clock-names = "pmu";
			status = "okay";
			//phandle = <0xd6>;
		};
	};

	uart0: serial@ff030000 {
		compatible = "rockchip,px30-uart", "snps,dw-apb-uart";
		reg = <0x00 0xff030000 0x00 0x100>;
		interrupts = <0x00 0x0f 0x04>;
		clocks = <&pmucru 0x06>, <&pmucru 0x15>;
		clock-names = "baudclk", "apb_pclk";
		reg-shift = <0x02>;
		reg-io-width = <0x04>;
		dmas = <&dmac 0x00>, <&dmac 0x01>;
		pinctrl-names = "default";
		pinctrl-0 = <&uart0_xfer>; //&uart0_cts &uart0_rts
		status = "disabled";
		phandle = <0xd7>;
	};

	i2s0_8ch: i2s@ff060000 {
		compatible = "rockchip,px30-i2s-tdm";
		reg = <0x00 0xff060000 0x00 0x1000>;
		interrupts = <0x00 0x0c 0x04>;
		clocks = <&cru 0x10>, <&cru 0x12>, <&cru 0x106>;
		clock-names = "mclk_tx", "mclk_rx", "hclk";
		dmas = <&dmac 0x10>, <&dmac 0x11>;
		dma-names = "tx", "rx";
		resets = <&cru 0x84>, <&cru 0xbf>;
		reset-names = "tx-m", "rx-m";
		rockchip,cru = <&cru>;
		rockchip,grf = <&grf>;
		pinctrl-names = "default";
		pinctrl-0 = <0x30 0x31 0x32 0x33 0x34 0x35 0x36 0x37 0x38 0x39 0x3a 0x3b>;
		status = "disabled";
		phandle = <0xd8>;
	};

	i2s1_2ch: i2s@ff070000 {
		compatible = "rockchip,px30-i2s", "rockchip,rk3066-i2s";
		reg = <0x00 0xff070000 0x00 0x1000>;
		interrupts = <0x00 0x0d 0x04>;
		clocks = <&cru 0x14>, <&cru 0x107>;
		clock-names = "i2s_clk", "i2s_hclk";
		dmas = <&dmac 0x12>, <&dmac 0x13>;
		dma-names = "tx", "rx";
		resets = <&cru 0x86>, <&cru 0x85>;
		reset-names = "reset-m", "reset-h";
		pinctrl-names = "default";
		pinctrl-0 = <&i2s1_2ch_sclk &i2s1_2ch_lrck &i2s1_2ch_sdi &i2s1_2ch_sdo>;
		status = "okay";
		#sound-dai-cells = <0>;
		phandle = <0xc6>;
	};

	i2s2_2ch: i2s@ff080000 {
		compatible = "rockchip,px30-i2s", "rockchip,rk3066-i2s";
		reg = <0x00 0xff080000 0x00 0x1000>;
		interrupts = <0x00 0x0e 0x04>;
		clocks = <&cru 0x16>, <&cru 0x108>;
		clock-names = "i2s_clk", "i2s_hclk";
		dmas = <&dmac 0x14>, <&dmac 0x15>;
		dma-names = "tx", "rx";
		resets = <&cru 0x88>, <&cru 0x87>;
		reset-names = "reset-m", "reset-h";
		pinctrl-names = "default";
		pinctrl-0 = <&i2s2_2ch_sclk &i2s2_2ch_sclk &i2s2_2ch_sdi &i2s2_2ch_sdo>;
		status = "disabled";
		phandle = <0xd9>;
	};	

	pdm: pdm@ff0a0000 {
		compatible = "rockchip,px30-pdm", "rockchip,pdm";
		reg = <0x00 0xff0a0000 0x00 0x1000>;
		clocks = <&cru 0x0f>, <&cru 0x105>;
		clock-names = "pdm_clk", "pdm_hclk";
		dmas = <&dmac 0x18>;
		dma-names = "rx";
		resets = <&cru 0x82>;
		reset-names = "pdm-m";
		pinctrl-names = "default";
		pinctrl-0 = <&pdm_clk0m0 &pdm_clk1 &pdm_sdi0m0 &pdm_sdi1 &pdm_sdi2 &pdm_sdi3>;
		status = "disabled";
		phandle = <0xda>;
	};

	crypto: crypto@ff0b0000 {
		compatible = "rockchip,px30-crypto";
		reg = <0x00 0xff0b0000 0x00 0x4000>;
		interrupts = <0x00 0x52 0x04>;
		clocks = <&cru 0xac>, <&cru 0xf1>, <&cru 0x30>, <&cru 0x31>;
		clock-names = "aclk", "hclk", "sclk", "apb_pclk";
		resets = <&cru 0x74>;
		reset-names = "crypto-rst";
		status = "disabled";
		phandle = <0xdb>;
	};

	rng: rng@ff0b0000 {
		compatible = "rockchip,cryptov2-rng";
		reg = <0x00 0xff0b0000 0x00 0x4000>;
		clocks = <&cru 0x30>, <&cru 0x31>, <&cru 0xac>, <&cru 0xf1>;
		clock-names = "clk_crypto", "clk_crypto_apk", "aclk_crypto", "hclk_crypto";
		assigned-clocks = <&cru 0x30>, <&cru 0x31>, <&cru 0xac>, <&cru 0xf1>;
		assigned-clock-rates = <0x8f0d180 0x8f0d180 0xbebc200 0x5f5e100>;
		resets = <&cru 0x74>;
		reset-names = "reset";
		status = "okay";
		phandle = <0xdc>;
	};

	gic: interrupt-controller@ff131000 {
		compatible = "arm,gic-400";
		#interrupt-cells = <3>;
		#address-cells = <0>;
		interrupt-controller;
		reg = <0x00 0xff131000 0x00 0x1000 0x00 0xff132000 0x00 0x2000 0x00 0xff134000 0x00 0x2000 0x00 0xff136000 0x00 0x2000>;
		interrupts = <0x01 0x09 0xf04>;
		phandle = <0x01>;
	};

	grf: syscon@ff140000 {
		compatible = "rockchip,px30-grf", "syscon", "simple-mfd";
		reg = <0x00 0xff140000 0x00 0x1000>;
		#address-cells = <1>;
		#size-cells = <1>;
		phandle = <0x2f>;

		io_domains: io-domains {
			compatible = "rockchip,px30-io-voltage-domain";
			status = "okay";
			vccio1-supply = <&vccio_mmc>; //SDIO, uart1 I/O
			vccio2-supply = <&vccio_sd>;	  //SDMMC I/O
			vccio3-supply = <&vcc1v8_soc>;	  //CAM uart2m1 i2c2 I/O
			vccio4-supply = <&vcc_3v0>;       //LVCS/LCDC uart5 I/O
			vccio5-supply = <&vcc_3v0>;		  //I2S1 I/O
			vccio6-supply = <&vcc1v8_soc>;	  //eMMC I/O
			vccio-oscgpi-supply = <&vcc1v8_soc>; //Clock generator
			phandle = <0xdd>;
		};

		lvds: lvds {
			compatible = "rockchip,px30-lvds";
			phys = <&video_phy>;
			phy-names = "phy";
			status = "disabled";
			phandle = <0xde>;

			ports {
				#address-cells = <1>;
				#size-cells = <0>;

				port@0 {
					reg = <0x00>;
					#address-cells = <1>;
					#size-cells = <0>;

					lvds_in_vopb: endpoint@0 {
						reg = <0x00>;
						remote-endpoint = <&vopb_out_lvds>;
						phandle = <0xa7>;
					};
				};
			};
		};

		rgb: rgb {
			compatible = "rockchip,px30-rgb";
			pinctrl-names = "default", "sleep";
			pinctrl-0 = <&lcdc_m1_rgb_pins>;
			pinctrl-1 = <&lcdc_m1_sleep_pins>;
			status = "disabled";
			phys = <&video_phy>;
			phy-names = "phy";
			phandle = <0xdf>;

			ports {
				#address-cells = <1>;
				#size-cells = <0>;

				port@0 {
					reg = <0x00>;
					#address-cells = <1>;
					#size-cells = <0>;

					rgb_in_vopb: endpoint@0 {
						reg = <0x00>;
						remote-endpoint = <&vopb_out_rgb>;
					    phandle = <0xa9>;
					};
				};
			};
		};
	};

	core_grf: syscon@ff148000 {
		compatible = "syscon", "simple-mfd";
		reg = <0x00 0xff148000 0x00 0x1000>;
		#address-cells = <1>;
		#size-cells = <1>;
		phandle = <0xe0>;

		pvtm: pvtm {
			compatible = "rockchip,px30-pvtm";
			clocks = <&cru 0x4a>;
			clock-names = "core";
			status = "okay";
			phandle = <0xe1>;
		};
	};

	uart1: serial@ff158000 { //okay to enable, but not wired to any pads
		compatible = "rockchip,px30-uart", "snps,dw-apb-uart";
		reg = <0x00 0xff158000 0x00 0x100>;
		interrupts = <0x00 0x10 0x04>;
		clocks = <&cru 0x18>, <&cru 0x149>;
		clock-names = "baudclk", "apb_pclk";
		reg-shift = <0x02>;
		reg-io-width = <0x04>;
		dmas = <&dmac 0x02>, <&dmac 0x03>;
		pinctrl-names = "default";
		pinctrl-0 = <&uart1_xfer>;
		status = "disabled";
		phandle = <0xe2>;
	};

	uart2: serial@ff160000 {
		compatible = "rockchip,px30-uart", "snps,dw-apb-uart";
		reg = <0x00 0xff160000 0x00 0x100>;
		interrupts = <0x00 0x11 0x04>;
		clocks = <&cru 0x19>, <&cru 0x14a>;
		clock-names = "baudclk", "apb_pclk";
		reg-shift = <0x02>;
		reg-io-width = <0x04>;
		dmas = <&dmac 0x04>, <&dmac 0x05>;
		pinctrl-names = "default";
		pinctrl-0 = <&uart2m0_xfer>; //uart2m0_xfer clashesh with SDMMC0_D0 and SDMMC0_D1
		status = "disabled"; //keep disabled!
		phandle = <0xe3>;
	};

	//UART3 and UART4 not used in RK3326
	uart3: serial@ff168000 {
		compatible = "rockchip,px30-uart", "snps,dw-apb-uart";
		reg = <0x00 0xff168000 0x00 0x100>;
		interrupts = <0x00 0x12 0x04>;
		clocks = <&cru 0x1a>, <&cru 0x14b>;
		clock-names = "baudclk", "apb_pclk";
		reg-shift = <0x02>;
		reg-io-width = <0x04>;
		dmas = <&dmac 0x06>, <&dmac 0x07>;
		pinctrl-names = "default";
		pinctrl-0 = <0x54 0x55 0x56>;
		status = "disabled";
		phandle = <0xe4>;
	};

	uart4: serial@ff170000 {
		compatible = "rockchip,px30-uart", "snps,dw-apb-uart";
		reg = <0x00 0xff170000 0x00 0x100>;
		interrupts = <0x00 0x13 0x04>;
		clocks = <&cru 0x1b>, <&cru 0x14c>;
		clock-names = "baudclk", "apb_pclk";
		reg-shift = <0x02>;
		reg-io-width = <0x04>;
		dmas = <&dmac 0x08>, <&dmac 0x09>;
		pinctrl-names = "default";
		pinctrl-0 = <&uart4_xfer>;
		status = "disabled";
		phandle = <0xe5>;
	};

	uart5: serial@ff178000 { //Through hole pads. Do not enable if FIQ debugger not disabled/irq mode
		compatible = "rockchip,px30-uart", "snps,dw-apb-uart";
		reg = <0x00 0xff178000 0x00 0x100>;
		interrupts = <0x00 20 0x04>;
		clock-frequency = <24000000>;
		clocks = <&cru 28>, <&cru 333>; //<&cru SCLK_UART5>, <&cru PCLK_UART5>;
		clock-names = "baudclk", "apb_pclk";
		assigned-clocks = <&cru 28>;//SCLK_UART5
		assigned-clock-parents = <&cru 1>;//PLL_GPLL,XIN24M
		assigned-clock-rates = <24000000>;
		reg-shift = <2>;
		reg-io-width = <4>;
		dmas = <&dmac 10>, <&dmac 11>;
		dma-names = "tx", "rx";
		pinctrl-names = "default";
		pinctrl-0 = <&uart5_xfer>;//<0x5a 0x5b 0x5c>;
		status = "disabled"; //clashes with fiq debugger!
		//clock-frequency = <115200>;
	};

	i2c0: i2c@ff180000 {
		compatible = "rockchip,rk3399-i2c";
		reg = <0x00 0xff180000 0x00 0x1000>;
		clocks = <&cru 0x1d>, <&cru 0x14e>;
		clock-names = "i2c", "pclk";
		interrupts = <0x00 0x07 0x04>;
		pinctrl-names = "default";
		pinctrl-0 = <&i2c0_xfer>;
		#address-cells = <1>;
		#size-cells = <0>;
		status = "okay";
		clock-frequency = <400000>;
		i2c-scl-rising-time-ns = <0x118>;
		i2c-scl-falling-time-ns = <0x10>;

		rk817: pmic@20 {
			compatible = "rockchip,rk817";
			reg = <0x20>;
			interrupt-parent = <&gpio0>;
			interrupts = <0x0a 0x08>;
			pinctrl-names = "default", "pmic-sleep", "pmic-power-off", "pmic-reset";
			pinctrl-0 = <&pmic_int>;
			pinctrl-1 = <&soc_slppin_slp>, <&rk817_slppin_slp>;
			pinctrl-2 = <&soc_slppin_gpio>, <&rk817_slppin_pwrdn>;
			pinctrl-3 = <&soc_slppin_rst>, <&rk817_slppin_rst>;
			rockchip,system-power-controller;
			wakeup-source;
			#clock-cells = <1>;
			clock-output-names = "rk808-clkout1", "rk808-clkout2";
			pmic-reset-func = <1>;
			vcc1-supply = <&vccsys>;  //DCDC_REG1
			vcc2-supply = <&vccsys>;  //DCDC_REG2
			vcc3-supply = <&vccsys>;  //DCDC_REG3
			vcc4-supply = <&vccsys>;  //DCDC_REG4
			vcc5-supply = <&vccsys>;  //LDO_REG1, LDO_REG2, LDO_REG3
			vcc6-supply = <&vccsys>;  //LDO_REG4, LDO_REG5, LDO_REG6
			vcc7-supply = <&vccsys>; //LDO_REG7, LDO_REG8, LDO_REG9
			vcc8-supply = <&vccsys>; //input supply for BOOST
			vcc9-supply = <&dcdc_boost>; //input supply for OTG_SWITCH
	
			pwrkey {
				status = "okay";
			};

			pinctrl_rk8xx: pinctrl_rk8xx {
				gpio-controller;
				#gpio-cells = <2>;

				rk817_ts_gpio1: rk817_ts_gpio1 {
					pins = "gpio_ts";
					function = "pin_fun1";
				};

				rk817_gt_gpio2: rk817_gt_gpio2 {
					pins = "gpio_gt";
					function = "pin_fun1";
				};

				rk817_pin_ts: rk817_pin_ts {
					pins = "gpio_ts";
					function = "pin_fun0";
				};

				rk817_pin_gt: rk817_pin_gt {
					pins = "gpio_gt";
					function = "pin_fun0";
				};

				rk817_slppin_null: rk817_slppin_null {
					pins = "gpio_slp";
					function = "pin_fun0";
				};

				rk817_slppin_slp: rk817_slppin_slp {
					pins = "gpio_slp";
					function = "pin_fun1";
				};

				rk817_slppin_pwrdn: rk817_slppin_pwrdn {
					pins = "gpio_slp";
					function = "pin_fun2";

				};

				rk817_slppin_rst: rk817_slppin_rst {
					pins = "gpio_slp";
					function = "pin_fun3";
				};
			};

			regulators {

				vdd_logic: DCDC_REG1 {
					regulator-always-on;
					regulator-boot-on;
					system-critical-regulator;
					regulator-min-microvolt = <950000>; 
					regulator-max-microvolt = <1150000>; //1.15V Abs max
					regulator-ramp-delay = <0x1771>;
					regulator-initial-mode = <0x02>;
					regulator-name = "vdd_logic";//GPU and core logic 0.9-1.10

					regulator-state-mem {
						regulator-on-in-suspend;//on-in-suspend
						regulator-suspend-microvolt = <950000>;
					};
				};

				vdd_arm: DCDC_REG2 {
					regulator-always-on;
					regulator-boot-on;
					system-critical-regulator;
					regulator-min-microvolt = <950000>;
					regulator-max-microvolt = <1350000>; //1.40V Abs max
					regulator-ramp-delay = <0x1771>;
					regulator-initial-mode = <0x02>;
					regulator-name = "vdd_arm";//CPU 0.95-1.35

					regulator-state-mem {
						regulator-off-in-suspend;//off-in-suspend
						regulator-suspend-microvolt = <950000>;
					};
				};

				vcc_ddr: DCDC_REG3 {
					regulator-always-on;
					regulator-boot-on;
					system-critical-regulator;
					regulator-initial-mode = <0x02>;
					regulator-name = "vcc_ddr"; //1.65V Abs max

					regulator-state-mem {
						regulator-on-in-suspend;//on-in-suspend
					};
				};

				vcc_3v0: DCDC_REG4 {//IO4, IO5, LDO7-9, LCD1.8v, LCD2.8v, Rumble motor
					regulator-always-on;
					regulator-boot-on;
					regulator-min-microvolt = <3000000>;
					regulator-max-microvolt = <3000000>;
					regulator-initial-mode = <0x02>;
					regulator-name = "vcc_3v0";

					regulator-state-mem {
						regulator-off-in-suspend;//off-in-suspend
						regulator-suspend-microvolt = <3000000>;
					};
				};

				vcc_1v0: LDO_REG1 {
					regulator-always-on;
					regulator-boot-on;
					regulator-min-microvolt = <1000000>;
					regulator-max-microvolt = <1000000>;
					regulator-name = "vcc_1v0";

					regulator-state-mem {
						regulator-on-in-suspend;//on-in-suspend
						regulator-suspend-microvolt = <1000000>;
					};
				};

				vcc1v8_soc: LDO_REG2 {//IO3, IO6
					regulator-always-on;
					regulator-boot-on;
					system-critical-regulator;
					regulator-min-microvolt = <1800000>;
					regulator-max-microvolt = <1800000>;
					regulator-name = "vcc1v8_soc";

					regulator-state-mem {
						regulator-on-in-suspend;//on-in-suspend
						regulator-suspend-microvolt = <1800000>;
					};
				};

				vcc1v0_soc: LDO_REG3 {
					regulator-always-on;
					regulator-boot-on;
					system-critical-regulator;
					regulator-min-microvolt = <1000000>;
					regulator-max-microvolt = <1000000>;
					regulator-name = "vcc1v0_soc";

					regulator-state-mem {
						regulator-on-in-suspend;//on-in-suspend
						regulator-suspend-microvolt = <1000000>;
					};
				};

				vcc3v0_pmu: LDO_REG4 {//PMUIO1,PMUIO2
					regulator-always-on;
					regulator-boot-on;
					regulator-min-microvolt = <3000000>;
					regulator-max-microvolt = <3000000>;
					regulator-name = "vcc3v0_pmu";

					regulator-state-mem {
						regulator-on-in-suspend;//on-in-suspend
						regulator-suspend-microvolt = <3000000>;
					};
				};

				vccio_sd: LDO_REG5 {//IO for TF1, 1.8/3.3V. Important for uhs operation!
					regulator-always-on;
					regulator-boot-on;
					regulator-min-microvolt = <1800000>;
					regulator-max-microvolt = <3300000>;//3300000
					regulator-ramp-delay = <0x1771>;
					regulator-name = "vccio_sd";

					regulator-state-mem {
						regulator-on-in-suspend;//on-in-suspend
						regulator-suspend-microvolt = <3300000>;//3300000
					};
				};

				vcc_sd: LDO_REG6 { //Power for TF1, 3.3V
					regulator-min-microvolt = <3300000>;//3300000
					regulator-max-microvolt = <3300000>;//3300000
					regulator-ramp-delay = <0x1771>;
					regulator-always-on;
					regulator-boot-on;
					regulator-name = "vcc_sd";

					regulator-state-mem {
						regulator-on-in-suspend;//on-in-suspend
						regulator-suspend-microvolt = <3300000>;//3300000
					};
				};

				vccio_mmc: LDO_REG7 {//IO for TF2, 1.8/3.3V. Important for uhs operation!
					regulator-always-on;
					regulator-boot-on;
					regulator-min-microvolt = <1800000>;
					regulator-max-microvolt = <3300000>;
					regulator-ramp-delay = <0x1771>;
					//regulator-init-microvolt = <3000000>;
					regulator-name = "vccio_mmc";

					regulator-state-mem {
						regulator-off-in-suspend;//on-in-suspend
						regulator-suspend-microvolt = <3300000>;
					};
				};

				vcc_mmc: LDO_REG8 { //Power for TF2, 3.3V
					regulator-always-on;
					regulator-boot-on;
					regulator-min-microvolt = <3300000>;
					regulator-max-microvolt = <3300000>;
					regulator-name = "vcc_mmc"; 

					regulator-state-mem {
						regulator-off-in-suspend;//on-in-suspend
						regulator-suspend-microvolt = <3300000>;
					};
				};

				vdd1v5_dvp: LDO_REG9 {
					regulator-always-on;
					regulator-boot-on;
					regulator-min-microvolt = <1500000>;
					regulator-max-microvolt = <1500000>;
					regulator-name = "vdd1v5_dvp";

					regulator-state-mem {
						regulator-off-in-suspend;
						regulator-suspend-microvolt = <1500000>;
					};
				};

				dcdc_boost: BOOST {
					regulator-always-on;
					regulator-boot-on;
					regulator-min-microvolt = <5000000>;
					regulator-max-microvolt = <5400000>;
					regulator-ramp-delay = <0x1771>;
					regulator-name = "boost";

					regulator-state-mem {
						regulator-off-in-suspend;
					};
				};

				otg_switch: OTG_SWITCH { /*NEVER EVER ENABLE, is connected to charger and charge port*/
					regulator-name = "otg_switch";
					//status = "disabled";
					
					/*regulator-state-mem {
						regulator-off-in-suspend;
					};*/
				};
			};

			battery {
				compatible = "rk817,battery";
				//ocv_table = <3300 3340 3380 3420 3460 3500 3540 3570 3610 3650 3690 3720 3750 3790 3830 3870 3910 3940 3967 4001 4046>;
				ocv_table = <3300 3342 3384 3426 3468 3511 3554
							3597 3640 3683 3726 3769 3812 3855
							3898 3941 3984 4027 4070 4113 4158>;
				design_capacity = <1800>;//3500 //Clones have very crapy batteries!
				design_qmax = <2000>;//3700 
				bat_res = <150>; //Measured with B6neo, 148-152mOhm
				sleep_enter_current = <300>;
				sleep_exit_current = <300>;
				sleep_filter_current = <100>;
				power_off_thresd = <3000>;//3500, try to run battery little bit longer
				zero_algorithm_vol = <3850>;
				max_soc_offset = <60>;
				monitor_sec = <5>;
				sample_res = <10>;
				virtual_power = <0x00>;
				bat-low-threshold = <30>;
				bat-low-gpio = <&gpio0 17 0x00>;
				//chg-ok-gpio = <&gpio0 0 0x00>;
				//led-gpio = <&gpio0 0 0x00>;

				//fb_temperature = <TEMP_115C>;
				//energy_mode = <0>;
				//zero_reserve_dsoc = <10>; 
			};

			charger {/*Charging is also handled by 4056 dedicated charger connected parallel to RK817*/
				compatible = "rk817,charger";
				min_input_voltage = <4500>;
				max_input_current = <1500>;//800 for usb3, 1500 for charge only port
				max_chrg_current = <800>;//800 should take 4056 into account
				max_chrg_voltage = <4200>;
				chrg_term_mode = <0>; //0 Analog 1 Digital
				chrg_finish_cur = <300>;
				virtual_power = <0>;
				sample_res = <10>;
				dc_det_gpio = <&gpio3 5 0x00>;
				//chg_led_gpio = <&gpio0 1 0x00>; //Board has missing resistor that connects to the charge led of the 4056
				
				//extcon = <&usb_extcon_charge>; 
				extcon = <&u2phy>; //usb2 phy is not a charging port, otg only. Disable the extcon!
				//extcon = <>;     //rk817_charge_dc_det_worker likes to switch boost off and glitch usb
				power_dc2otg = <1>; //DC is connected to OTG/USBIN of RK817, so keep the OTG_SWITCH OFF!
				otg5v_suspend_enable = <0>;
			};

			rk817_codec: codec {
				#sound-dai-cells = <0>;
				compatible = "rockchip,rk817-codec";
				clocks = <&cru 0x15>;
				clock-names = "mclk";
				pinctrl-names = "default";
				pinctrl-0 = <&i2s1_2ch_mclk>;
				spk-ctl-gpios = <&gpio3 7 0x00>;
				spk-mute-delay-ms = <0x32>;
				hp-volume = <0x14>;
				spk-volume = <0x03>;
				status = "okay";
			};
		};
	};

	i2c1: i2c@ff190000 {
		compatible = "rockchip,rk3399-i2c";
		reg = <0x00 0xff190000 0x00 0x1000>;
		clocks = <&cru 0x1e>, <&cru 0x14f>;
		clock-names = "i2c", "pclk";
		interrupts = <0x00 0x08 0x04>;
		pinctrl-names = "default";
		pinctrl-0 = <&i2c1_xfer>;
		#address-cells = <1>;
		#size-cells = <0>;
		status = "okay";
		clock-frequency = <400000>;
		phandle = <0xf4>;
	};

	i2c2: i2c@ff1a0000 {
		compatible = "rockchip,rk3399-i2c";
		reg = <0x00 0xff1a0000 0x00 0x1000>;
		clocks = <&cru 0x1f>, <&cru 0x150>;
		clock-names = "i2c", "pclk";
		interrupts = <0x00 0x09 0x04>;
		pinctrl-names = "default";
		pinctrl-0 = <&i2c2_xfer>;
		#address-cells = <1>;
		#size-cells = <0>;
		status = "disabled";
		phandle = <0xf5>;
	};

	i2c3: i2c@ff1b0000 {
		compatible = "rockchip,rk3399-i2c";
		reg = <0x00 0xff1b0000 0x00 0x1000>;
		clocks = <&cru 0x20>, <&cru 0x151>;
		clock-names = "i2c", "pclk";
		interrupts = <0x00 0x0a 0x04>;
		pinctrl-names = "default";
		pinctrl-0 = <&i2c3_xfer>;
		#address-cells = <1>;
		#size-cells = <0>;
		status = "disabled";
		phandle = <0xf6>;
	};

	spi0: spi@ff1d0000 {
		compatible = "rockchip,px30-spi", "rockchip,rk3066-spi";
		reg = <0x00 0xff1d0000 0x00 0x1000>;
		interrupts = <0x00 0x1a 0x04>;
		#address-cells = <1>;
		#size-cells = <0>;
		clocks = <&cru 0x24>, <&cru 0x155>;
		clock-names = "spiclk", "apb_pclk";
		dmas = <&dmac 0x0c>, <&dmac 0x0d>;
		dma-names = "tx", "rx";
		pinctrl-names = "default", "high_speed";
		pinctrl-0 = <0x6e 0x6f 0x70 0x71>;
		pinctrl-1 = <0x72 0x6f 0x73 0x74>;
		status = "disabled";
		phandle = <0xf7>;
	};

	spi1: spi@ff1d8000 {
		compatible = "rockchip,px30-spi", "rockchip,rk3066-spi";
		reg = <0x00 0xff1d8000 0x00 0x1000>;
		interrupts = <0x00 0x1b 0x04>;
		#address-cells = <1>;
		#size-cells = <0>;
		clocks = <&cru 0x25>, <&cru 0x156>;
		clock-names = "spiclk", "apb_pclk";
		dmas = <&dmac 0x0e>, <&dmac 0x0f>;
		dma-names = "tx", "rx";
		pinctrl-names = "default", "high_speed";
		pinctrl-0 = <0x75 0x76 0x77 0x78 0x79>;
		pinctrl-1 = <0x7a 0x76 0x77 0x7b 0x7c>;
		status = "disabled";
		phandle = <0xf8>;
	};

	wdt: watchdog@ff1e0000 {
		compatible = "snps,dw-wdt";
		reg = <0x00 0xff1e0000 0x00 0x100>;
		clocks = <&cru 0x15b>;
		interrupts = <0x00 0x25 0x04>;
		resets = <&cru 0xb5>;
		reset-names = "reset";
		status = "disabled";
		phandle = <0xf9>;
	};

	pwm0: pwm@ff200000 { //pwm0
		compatible = "rockchip,px30-pwm", "rockchip,rk3328-pwm";
		reg = <0x00 0xff200000 0x00 0x10>;
		#pwm-cells = <3>;
		pinctrl-names = "active";
		pinctrl-0 = <&pwm0_pin>;
		clocks = <&cru 0x22>, <&cru 0x153>;
		clock-names = "pwm", "pclk";
		status = "okay";
		phandle = <0xc1>;
	};

	pwm1: pwm@ff200010 { //pwm1
		compatible = "rockchip,px30-pwm", "rockchip,rk3328-pwm";
		reg = <0x00 0xff200010 0x00 0x10>;
		#pwm-cells = <3>;
		pinctrl-names = "active";
		pinctrl-0 = <&pwm1_pin>;
		clocks = <&cru 0x22>, <&cru 0x153>;
		clock-names = "pwm", "pclk";
		status = "okay";
		phandle = <0xc4>;
	};

	//Only 2 PWM in RK3326
	pwm2: pwm@ff200020 { //pwm2
		compatible = "rockchip,px30-pwm", "rockchip,rk3328-pwm";
		reg = <0x00 0xff200020 0x00 0x10>;
		#pwm-cells = <3>;
		pinctrl-names = "active";
		pinctrl-0 = <0x7f>;
		clocks = <&cru 0x22>, <&cru 0x153>;
		clock-names = "pwm", "pclk";
		status = "disabled";
		phandle = <0xfa>;
	};

	pwm3: pwm@ff200030 { //pwm3
		compatible = "rockchip,px30-pwm", "rockchip,rk3328-pwm";
		reg = <0x00 0xff200030 0x00 0x10>;
		#pwm-cells = <3>;
		pinctrl-names = "active";
		pinctrl-0 = <0x80>;
		clocks = <&cru 0x22>, <&cru 0x153>;
		clock-names = "pwm", "pclk";
		status = "disabled";
		phandle = <0xfb>;
	};

	pwm4: pwm@ff208000 { //pwm4
		compatible = "rockchip,px30-pwm", "rockchip,rk3328-pwm";
		reg = <0x00 0xff208000 0x00 0x10>;
		#pwm-cells = <3>;
		pinctrl-names = "active";
		pinctrl-0 = <0x81>;
		clocks = <&cru 0x23>, <&cru 0x154>;
		clock-names = "pwm", "pclk";
		status = "disabled";
		phandle = <0xfc>;
	};

	pwm5: pwm@ff208010 { //pwm5
		compatible = "rockchip,px30-pwm", "rockchip,rk3328-pwm";
		reg = <0x00 0xff208010 0x00 0x10>;
		#pwm-cells = <3>;
		pinctrl-names = "active";
		pinctrl-0 = <0x82>;
		clocks = <&cru 0x23>, <&cru 0x154>;
		clock-names = "pwm", "pclk";
		status = "disabled";
		phandle = <0xfd>;
	};

	pwm6: pwm@ff208020 { //pwm6
		compatible = "rockchip,px30-pwm", "rockchip,rk3328-pwm";
		reg = <0x00 0xff208020 0x00 0x10>;
		#pwm-cells = <3>;
		pinctrl-names = "active";
		pinctrl-0 = <0x83>;
		clocks = <&cru 0x23>, <&cru 0x154>;
		clock-names = "pwm", "pclk";
		status = "disabled";
		phandle = <0xfe>;
	};

	pwm7: pwm@ff208030 { //pwm7
		compatible = "rockchip,px30-pwm", "rockchip,rk3328-pwm";
		reg = <0x00 0xff208030 0x00 0x10>;
		#pwm-cells = <3>;
		pinctrl-names = "active";
		pinctrl-0 = <0x84>;
		clocks = <&cru 0x23>, <&cru 0x154>;
		clock-names = "pwm", "pclk";
		status = "disabled";
		phandle = <0xff>;
	};

	rktimer: rktimer@ff210000 {
		compatible = "rockchip,rk3288-timer";
		reg = <0x00 0xff210000 0x00 0x1000>;
		interrupts = <0x00 0x1e 0x04>;
		clocks = <&cru 0x159>, <&cru 0x26>;
		clock-names = "pclk", "timer";
		//phandle = <0x100>;
	};

	amba {
		compatible = "simple-bus";
		#address-cells = <2>;
		#size-cells = <2>;
		ranges;

		dmac: dmac@ff240000 {
			compatible = "arm,pl330", "arm,primecell";
			reg = <0x00 0xff240000 0x00 0x4000>;
			interrupts = <0x00 0x01 0x04 0x00 0x02 0x04>;
			clocks = <&cru 0xbb>;
			clock-names = "apb_pclk";
			#dma-cells = <1>;
			peripherals-req-type-burst;
		};
	};

	thermal_zones: thermal-zones {
		phandle = <0x101>;

		soc_thermal: soc-thermal {
			polling-delay-passive = <20>;
			polling-delay = <1000>;
			sustainable-power = <750>;
			thermal-sensors = <&tsadc 0>;
			//phandle = <0x102>;

			trips {

				threshold: trip-point-0 {
					temperature = <70000>;
					hysteresis = <2000>;
					type = "passive";
					//phandle = <0x103>;
				};

				target: trip-point-1 {
					temperature = <85000>;
					hysteresis = <2000>;
					type = "passive";
					//phandle = <0x86>;
				};

				soc_crit: soc-crit {
					temperature = <115000>;
					hysteresis = <2000>;
					type = "critical";
					//phandle = <0x104>;
				};
			};

			cooling-maps {

				map0 {
					trip = <&target>;
					cooling-device = <&cpu0 0xffffffff 0xffffffff>;
					contribution = <0x1000>;
				};

				map1 {
					trip = <&target>;
					cooling-device = <&gpu 0xffffffff 0xffffffff>;
					contribution = <0x1000>;
				};
			};
		};

		gpu_thermal: gpu-thermal {
			polling-delay-passive = <100>;
			polling-delay = <1000>;
			thermal-sensors = <&tsadc 1>;
			
			
			trips {
				gpu_threshold: gpu-threshold {
					temperature = <70000>;
					hysteresis = <2000>;
					type = "passive";
				};

				gpu_target: gpu-target {
					temperature = <85000>;
					hysteresis = <2000>;
					type = "passive";
				};

				gpu_crit: gpu-crit {
					temperature = <115000>;
					hysteresis = <2000>;
					type = "critical";
				};
			};

			cooling-maps {
				map0 {
					trip = <&gpu_target>;
					cooling-device = <&gpu 0xffffffff 0xffffffff>;
				};
			};
		};
	};

	tsadc: tsadc@ff280000 {
		compatible = "rockchip,px30-tsadc";
		reg = <0x00 0xff280000 0x00 0x100>;
		interrupts = <0x00 0x24 0x04>;
		rockchip,grf = <&grf>;
		clocks = <&cru 0x2c>, <&cru 0x158>;
		clock-names = "tsadc", "apb_pclk";
		assigned-clocks = <&cru 0x2c>;
		assigned-clock-rates = <50000>;
		resets = <&cru 0xa8>;
		reset-names = "tsadc-apb";
		#thermal-sensor-cells = <1>;
		rockchip,hw-tshut-temp = <120000>;
		rockchip,hw-tshut-mode = <1>;
		rockchip,hw-tshut-polarity = <0>;
		status = "okay";
		pinctrl-names = "gpio", "otpout";//init, default, sleep
		pinctrl-0 = <&tsadc_otp_gpio>;
		pinctrl-1 = <&tsadc_otp_out>;
		pinctrl-2 = <&tsadc_otp_gpio>;
	};

	saradc: saradc@ff288000 {
		compatible = "rockchip,px30-saradc", "rockchip,rk3399-saradc";
		reg = <0x00 0xff288000 0x00 0x100>;
		interrupts = <0x00 0x54 0x04>;
		#io-channel-cells = <1>;
		clocks = <&cru 0x2d>, <&cru 0x157>;
		clock-names = "saradc", "apb_pclk";
		resets = <&cru 0xa5>;
		reset-names = "saradc-apb";
		status = "okay";
		vref-supply = <&vcc1v8_soc>;
	};

	otp: otp@ff290000 {
		compatible = "rockchip,px30-otp";
		reg = <0x00 0xff290000 0x00 0x4000>;
		#address-cells = <1>;
		#size-cells = <1>;
		clocks = <&cru 0x2f>, <&cru 0x15a>, <&cru 0x161>;
		clock-names = "clk_otp", "pclk_otp", "pclk_otp_phy";
		resets = <&cru 0xb4>;
		reset-names = "otp_phy";

		otp_id: id@7 {
			reg = <0x07 0x10>;
			//phandle = <0x0f>;
		};

		cpu_leakage: cpu-leakage@17 {
			reg = <0x17 0x01>;
			//phandle = <0x07>;
		};

		performance: performance@1e {
			reg = <0x1e 0x01>;
			bits = <0x04 0x03>;
			//phandle = <0x08>;
		};
	};

	cru: clock-controller@ff2b0000 {
		compatible = "rockchip,px30-cru";
		reg = <0x00 0xff2b0000 0x00 0x1000>;
		rockchip,grf = <&grf>;
		rockchip,boost = <&cpu_boost>;
		#clock-cells = <1>;
		#reset-cells = <1>;
		//assigned-clocks = <&cru 0x04>; //PLL_NPLL
		//assigned-clock-rates = <1040000000>;
		//assigned-clocks = <&cru 4>;

		//assigned-clock-rates = <1188000000>; //also patched off in aosp kernel? Uboot sets this?
		//phandle = <0x02>;
	};

	cpu_boost: cpu-boost@ff2b8000 {
		compatible = "syscon";
		reg = <0x00 0xff2b8000 0x00 0x1000>;
		rockchip,boost-low-con0 = <4146>;
		rockchip,boost-low-con1 = <5185>;
		rockchip,boost-high-con0 = <4150>;
		rockchip,boost-high-con1 = <5185>;
		rockchip,boost-backup-pll = <0x01>;
		rockchip,boost-backup-pll-usage = <0x00>;
		rockchip,boost-switch-threshold = <2400000>;
		rockchip,boost-statis-threshold = <0x100>;
		rockchip,boost-statis-enable = <0x00>;
		rockchip,boost-enable = <0x00>;
	};

	pmucru: pmu-clock-controller@ff2bc000 {
		compatible = "rockchip,px30-pmucru";
		reg = <0x00 0xff2bc000 0x00 0x1000>;
		clocks = <&xin24m>;
		clock-names = "xin24m";
		rockchip,grf = <&grf>;
		#clock-cells = <1>;
		#reset-cells = <1>;
		//assigned-clocks = <&pmucru PLL_GPLL>, <&pmucru PCLK_PMU_PRE>, <&pmucru SCLK_WIFI_PMU>, <&cru ARMCLK>, <&cru ACLK_BUS_PRE>, <&cru ACLK_PERI_PRE>, <&cru HCLK_BUS_PRE>, <&cru HCLK_PERI_PRE>, <&cru PCLK_BUS_PRE>, <&cru SCLK_GPU>;
		
		assigned-clocks = <&pmucru 0x01>, <&pmucru 0x08>, <&pmucru 0x05>, <&cru 0x07>, <&cru 0xab>, <&cru 0xb0>, <&cru 0xf0>, <&cru 0xf5>, <&cru 0x140>, <&cru 0x49>, <&cru 28>;
		assigned-clock-rates = <1200000000>, <100000000>, 
							   <26000000>, <600000000>,
							   <200000000>, <200000000>,
							   <150000000>, <150000000>, 
							   <100000000>, <200000000>,
							   <24000000>;
	};

	usb2phy_grf: syscon@ff2c0000 {
		compatible = "rockchip,px30-usb2phy-grf", "syscon", "simple-mfd";
		reg = <0x00 0xff2c0000 0x00 0x10000>;
		#address-cells = <1>;
		#size-cells = <1>;

		u2phy: usb2-phy@100 {
			compatible = "rockchip,px30-usb2phy", "rockchip,rk3328-usb2phy";
			reg = <0x100 0x10>;
			clocks = <&pmucru 0x0a>;
			clock-names = "phyclk";
			#clock-cells = <0>;
			assigned-clocks = <&cru 0x0e>, <&cru 0x55>;
			assigned-clock-parents = <&u2phy>, <&cru 0x0e>;
			clock-output-names = "usb480m_phy";
			status = "okay";
			rockchip,disable-charger-detect; //not working, phy driver does not have way off disabling detection?

			u2phy_host: host-port {
				#phy-cells = <0>;
				interrupts = <0x00 0x44 0x04>;
				interrupt-names = "linestate";
				status = "okay";
				phy-supply = <&vcc_host>;
	            vbus-supply = <&vcc_host>;
				pinctrl-0 = <&u2phy_host_pin>;
			};

			u2phy_otg: otg-port {
				#phy-cells = <0>;
				interrupts = <0x00 0x42 0x04 0x00 0x41 0x04 0x00 0x40 0x04>;
				interrupt-names = "otg-bvalid", "otg-id", "linestate";
				status = "disabled";
				vbus-supply = <&vcc_host>;
				//rockchip,typec-vbus-det;
				phy-supply = <&vcc_host>;
				pinctrl-0 = <&u2phy_otg_pin>;
			};
		};
	};

	video_phy: video-phy@ff2e0000 {
		compatible = "rockchip,px30-video-phy";
		reg = <0x00 0xff2e0000 0x00 0x10000 0x00 0xff450000 0x00 0x10000>;
		clocks = <&pmucru 0x0b>, <&cru 0x145>, <&cru 0x144>;
		clock-names = "ref", "pclk_phy", "pclk_host";
		#clock-cells = <0>;
		resets = <&cru 0x3e>;
		reset-names = "rst";
		power-domains = <&power 0x0c>;
		//phy-supply = <&vcc_lcd>;
		#phy-cells = <0>;
		status = "okay";
	};

	mipi_dphy_rx0: mipi-dphy-rx0@ff2f0000 {
		compatible = "rockchip,rk3326-mipi-dphy";
		reg = <0x00 0xff2f0000 0x00 0x4000>;
		clocks = <&cru 0x146>;
		clock-names = "dphy-ref";
		power-domains = <&power 0x0d>;
		rockchip,grf = <&grf>;
		status = "disabled";
	};

	usb20_otg: usb@ff300000 {
		compatible = "rockchip,px30-usb", "rockchip,rk3066-usb", "snps,dwc2";
		reg = <0x00 0xff300000 0x00 0x40000>;
		interrupts = <0x00 0x3e 0x04>;
		clocks = <&cru 0x102>;
		clock-names = "otg";
		power-domains = <&power 0x05>;
		dr_mode = "otg";
		//usb-role-switch;
		//role-switch-default-mode = "host";
		g-np-tx-fifo-size = <0x10>;
		g-rx-fifo-size = <0x118>;
		g-tx-fifo-size = <0x100 0x80 0x80 0x40 0x20 0x10>;
		g-use-dma;
		phys = <&u2phy_otg>;
		phy-names = "usb2-phy";
		vusb_d-supply = <&vcc1v0_soc>;
		vusb_a-supply = <&vcc1v8_soc>;
		status = "okay";
	};

	usb_host0_ehci: usb@ff340000 {
		compatible = "generic-ehci";
		reg = <0x00 0xff340000 0x00 0x10000>;
		interrupts = <0x00 0x3c 0x04>;
		clocks = <&cru 0x103>, <&u2phy>;
		clock-names = "usbhost", "utmi";
		power-domains = <&power 0x05>;
		phys = <&u2phy_host>;
		phy-names = "usb";
		status = "disabled";
	};

	usb_host0_ohci: usb@ff350000 {
		compatible = "generic-ohci";
		reg = <0x00 0xff350000 0x00 0x10000>;
		interrupts = <0x00 0x3d 0x04>;
		clocks = <&cru 0x103>, <&u2phy>;
		clock-names = "usbhost", "utmi";
		power-domains = <&power 0x05>;
		phys = <&u2phy_host>;
		phy-names = "usb";
		status = "disabled";
	};

	gmac: ethernet@ff360000 {
		compatible = "rockchip,px30-gmac";
		reg = <0x00 0xff360000 0x00 0x10000>;
		rockchip,grf = <&grf>;
		interrupts = <0x00 0x2b 0x04>;
		interrupt-names = "macirq";
		clocks = <&cru 0x3e &cru 0x3f &cru 0x3f &cru 0x40 &cru 0x41 &cru 0xb2 &cru 0x143 &cru 0x4c>;
		clock-names = "stmmaceth", "mac_clk_rx", "mac_clk_tx", "clk_mac_ref", "clk_mac_refout", "aclk_mac", "pclk_mac", "clk_mac_speed";
		phy-mode = "rmii";
		pinctrl-names = "default";
		pinctrl-0 = <0x8e 0x8f>;
		resets = <&cru 0x5e>;
		reset-names = "stmmaceth";
		power-domains = <&power 0x09>;
		status = "disabled";
	};

	sdmmc: dwmmc@ff370000 { /*TF1 - OS*/
		compatible = "rockchip,px30-dw-mshc", "rockchip,rk3288-dw-mshc";
		reg = <0x00 0xff370000 0x00 0x4000>;
		max-frequency = <150000000>;//100000000
		clocks = <&cru 0xf7>, <&cru 0x3b>, <&cru 0x43>, <&cru 0x44>;
		clock-names = "biu", "ciu", "ciu-drv", "ciu-sample";
		assigned-clocks = <&cru 0x3b>;
		assigned-clock-parents = <&cru 0x57>;
		rockchip,default-sample-phase = <203>;
		power-domains = <&power 0x07>;
		fifo-depth = <0x100>;
		interrupts = <0x00 0x36 0x04>;
		pinctrl-names = "default";
		pinctrl-0 = <&sdmmc_clk &sdmmc_cmd &sdmmc_det &sdmmc_bus4>;
		status = "okay";
		bus-width = <0x04>;
		cap-mmc-highspeed;
		cap-sd-highspeed;
		supports-sd;
		card-detect-delay = <0x320>;
		//ignore-pm-notify;
		cd-gpios = <&gpio0 3 0x01>;
		disable-wp;
		sd-uhs-sdr12;
		sd-uhs-sdr25;
		sd-uhs-sdr50;
		sd-uhs-sdr104;
		vqmmc-supply = <&vccio_sd>;//LDO_REG5 1.8-3.3V
		vmmc-supply = <&vcc_sd>;//LDO_REG6 3.3V
	};

	sdio: dwmmc@ff380000 {/*TF2 - GAMES*/
		compatible = "rockchip,px30-dw-mshc", "rockchip,rk3288-dw-mshc";
		reg = <0x00 0xff380000 0x00 0x4000>;
		max-frequency = <150000000>;//100000000
		clocks = <&cru 0xff>, <&cru 0x38>, <&cru 0x45>, <&cru 0x46>;
		clock-names = "biu", "ciu", "ciu-drv", "ciu-sample";
		assigned-clocks = <&cru 0x38>;
		assigned-clock-parents = <&cru 0x51>;
		rockchip,default-sample-phase = <190>;
		power-domains = <&power 0x0a>;
		fifo-depth = <0x100>;
		interrupts = <0x00 0x37 0x04>;
		pinctrl-names = "default";
		pinctrl-0 = <&sdio_bus4 &sdio_cmd &sdio_clk &sdio_det>;
		status = "okay";
		bus-width = <0x04>;
		cap-mmc-highspeed;
		cap-sd-highspeed;
		supports-sd;
		card-detect-delay = <0x320>;
		//ignore-pm-notify;
		cd-gpios = <&gpio0 2 0x01>;
		disable-wp;
		sd-uhs-sdr12;
		sd-uhs-sdr25;
		sd-uhs-sdr50;
		sd-uhs-sdr104;
		vqmmc-supply = <&vccio_mmc>;//LDO_REG7 1.8-3.3V
		vmmc-supply = <&vcc_mmc>;//LDO_REG8 3.3V
	};

	emmc: dwmmc@ff390000 {/*emmc not populated*/
		compatible = "rockchip,px30-dw-mshc", "rockchip,rk3288-dw-mshc";
		reg = <0x00 0xff390000 0x00 0x4000>;
		max-frequency = <150000000>;
		clocks = <&cru 0x100>, <&cru 0x39>;
		clock-names = "biu", "ciu";
		assigned-clocks = <&cru 0x39>;
		assigned-clock-parents = <&cru 0x53>;
		power-domains = <&power 0x0a>;
		fifo-depth = <0x100>;
		interrupts = <0x00 0x35 0x04>;
		status = "disabled";
		bus-width = <0x08>;
		non-removable;
		disable-wp;
		no-sd;
		no-sdio;
		supports-emmc;
		cap-mmc-highspeed;
		vmmc-supply = <&vcc_3v0>;
		vqmmc-supply = <&vcc1v8_soc>;
		pinctrl-names = "default";
		pinctrl-0 = <&emmc_clk &emmc_cmd &emmc_bus8 &emmc_pwren &emmc_rstnout>;
		num-slots = <0x01>;
	};

	nandc0: nandc@ff3b0000 {/*Nand flash, not present*/
		compatible = "rockchip,rk-nandc";
		reg = <0x00 0xff3b0000 0x00 0x4000>;
		interrupts = <0x00 0x39 0x04>;
		nandc_id = <0x00>;
		clocks = <&cru 0x37>, <&cru 0xfe>;
		clock-names = "clk_nandc", "hclk_nandc";
		assigned-clocks = <&cru 0x37>;
		assigned-clock-parents = <&cru 0x4f>;
		power-domains = <&power 0x0a>;
		status = "disabled";
	};

	sfc: sfc@ff3a0000 {/*Serial flash, not present*/
		compatible = "rockchip,sfc";
		reg = <0x00 0xff3a0000 0x00 0x4000>;
		interrupts = <0x00 0x38 0x04>;
		clocks = <&cru 0x3a>, <&cru 0x101>;
		clock-names = "clk_sfc", "hclk_sfc";
		assigned-clocks = <&cru 0x3a>;
		assigned-clock-rates = <0x989680>;
		status = "disabled";
	};

	gpu: gpu@ff400000 {
		compatible = "arm,malit602", "arm,malit60x", "arm,malit6xx", "arm,mali-midgard";
		reg = <0x00 0xff400000 0x00 0x4000>;
		interrupts = <0x00 0x2d 0x04 0x00 0x2e 0x04 0x00 0x2f 0x04>;
		interrupt-names = "GPU", "MMU", "JOB";
		clocks = <&cru 0x49>;
		clock-names = "clk_mali";
		power-domains = <&power 0x0e>;
		#cooling-cells = <2>;
		operating-points-v2 = <&gpu_opp_table>;
		status = "okay";
		mali-supply = <&vdd_logic>;

		power_model {
			compatible = "arm,mali-simple-power-model";
			static-coefficient = <0x64578>;
			dynamic-coefficient = <0x2dd>;
			ts = <0x7d00 0x125c 0xffffffb0 0x02>;
			thermal-zone = "gpu-thermal";
		};
	};

	gpu_opp_table: gpu-opp-table {
		compatible = "operating-points-v2";
		rockchip,thermal-zone = "soc-thermal";
		rockchip,temp-hysteresis = <5000>;
		rockchip,low-temp = <0x00>;
		rockchip,low-temp-min-volt = <1000000>;
		rockchip,low-temp-adjust-volt = <0x00 0x1e0 0xc350>;
		rockchip,max-volt = <1175000>;
		rockchip,evb-irdrop = <25000>;
		rockchip,pvtm-voltage-sel = <0x00 0xc350 0x00 0xc351 0xd2f0 0x01 0xd2f1 0xea60 0x02 0xea61 0x1869f 0x03>;
		rockchip,pvtm-ch = <0x00 0x00>;
		
		/*opp-200000000 {//disabled?
			opp-hz = <0x00 0xbebc200>;
			opp-microvolt = <950000>;
			opp-microvolt-L0 = <950000>;
			opp-microvolt-L1 = <950000>;
			opp-microvolt-L2 = <950000>;
			opp-microvolt-L3 = <950000>;
		};

		opp-300000000 {//disabled?
			opp-hz = <0x00 0x11e1a300>;
			opp-microvolt = <975000>;
			opp-microvolt-L0 = <975000>;
			opp-microvolt-L1 = <950000>;
			opp-microvolt-L2 = <950000>;
			opp-microvolt-L3 = <950000>;
		};*/

		opp-400000000 {
			opp-hz = <0x00 400000000>;
			opp-microvolt = <1050000>;
			opp-microvolt-L0 = <1050000>;
			opp-microvolt-L1 = <1025000>;
			opp-microvolt-L2 = <975000>;
			opp-microvolt-L3 = <950000>;
		};

		opp-480000000 {
			opp-hz = <0x00 480000000>;
			opp-microvolt = <1125000>;
			opp-microvolt-L0 = <1125000>;
			opp-microvolt-L1 = <1100000>;
			opp-microvolt-L2 = <1050000>;
			opp-microvolt-L3 = <1000000>;
		};

		opp-520000000 {
			opp-hz = <0x00 	520000000>;
			opp-microvolt = <1150000>;//1175000
			opp-microvolt-L0 = <1150000>;//1175000
			opp-microvolt-L1 = <1150000>;
			opp-microvolt-L2 = <1100000>;
			opp-microvolt-L3 = <1050000>;
		};
	};

	hevc: hevc_service@ff440000 {
		compatible = "rockchip,hevc_sub";
		iommu_enabled = <0x01>;
		reg = <0x00 0xff440000 0x00 0x400>;
		interrupts = <0x00 0x31 0x04>;
		interrupt-names = "irq_dec";
		dev_mode = <0x01>;
		iommus = <&hevc_mmu>;
		allocator = <0x01>;
	};

	vpu: vpu_service@ff442000 {
		compatible = "rockchip,vpu_sub";
		iommu_enabled = <0x01>;
		reg = <0x00 0xff442000 0x00 0x800>;
		interrupts = <0x00 0x50 0x04 0x00 0x4f 0x04>;
		interrupt-names = "irq_enc", "irq_dec";
		dev_mode = <0x00>;
		iommus = <&vpu_mmu>;
		allocator = <0x01>;
	};

	vpu_combo: vpu_combo {
		compatible = "rockchip,vpu_combo";
		subcnt = <0x02>;
		rockchip,grf = <&grf>;
		rockchip,sub = <&vpu &hevc>;
		clocks = <&cru 0xaf>, <&cru 0xf4>, <&cru 0x4b>;
		clock-names = "aclk_vcodec", "hclk_vcodec", "clk_core";
		resets = <&cru 0x24>, <&cru 0x26>, <&cru 0x25>, <&cru 0x27>, <&cru 0x3f>;
		reset-names = "video_a", "video_h", "niu_a", "niu_h", "video_core";
		power-domains = <&power 0x0b>;
		//vcodec-supply = <&vdd_logic>;
		mode_bit = <0x0f>;
		mode_ctrl = <0x410>;
		status = "okay";
	};

	hevc_mmu: iommu@ff440440 {
		compatible = "rockchip,iommu";
		reg = <0x00 0xff440440 0x00 0x40 0x00 0xff440480 0x00 0x40>;
		interrupts = <0x00 0x32 0x04>;
		interrupt-names = "hevc_mmu";
		clocks = <&cru 0xaf>, <&cru 0xf4>;
		clock-names = "aclk", "hclk";
		power-domains = <&power 0x0b>;
		#iommu-cells = <0>;
	};

	vpu_mmu: iommu@ff442800 {
		compatible = "rockchip,iommu";
		reg = <0x00 0xff442800 0x00 0x100>;
		interrupts = <0x00 0x51 0x04>;
		interrupt-names = "vpu_mmu";
		clocks = <&cru 0xaf>, <&cru 0xf4>;
		clock-names = "aclk", "hclk";
		power-domains = <&power 0x0b>;
		#iommu-cells = <0>;
	};

	dsi: dsi@ff450000 {
		compatible = "rockchip,px30-mipi-dsi";
		reg = <0x00 0xff450000 0x00 0x10000>;
		interrupts = <0x00 0x4b 0x04>;
		clocks = <&cru 0x144>, <&video_phy>;
		clock-names = "pclk", "hs_clk";
		resets = <&cru 0x3d>;
		reset-names = "apb";
		phys = <&video_phy>;
		phy-names = "mipi_dphy";
		power-domains = <&power 0x0c>;
		rockchip,grf = <&grf>;
		#address-cells = <1>;
		#size-cells = <0>;
		status = "okay";
		phandle = <0x113>;

		ports {
			#address-cells = <1>;
			#size-cells = <0>;

			port@0 {
				reg = <0x00>;
				#address-cells = <1>;
				#size-cells = <0>;

				dsi_in_vopb: endpoint@0 {
					reg = <0x00>;
					remote-endpoint = <&vopb_out_dsi>;
					status = "okay";
					phandle = <0xa8>;
				};
			};
		};

		panel@0 {
			compatible = "simple-panel-dsi";
			reg = <0>;
			backlight = <&backlight>;
			backlight-supply = <&vcc_bl_boost>;
			power-supply = <&vcc28_lcd0>;
			iovcc-supply = <&vcc18_lcd0>;
			//vcc-supply = <&vcc28_lcd0>;
			reset-gpios = <&gpio3 15 0x01>;
			//enable-gpios = <&gpio0 13 0x00>; //handled by vcc18-lcd regulator
			prepare-delay-ms = <20>;
			reset-delay-ms = <20>;
			init-delay-ms = <20>;
			enable-delay-ms = <120>;
			disable-delay-ms = <20>;
			unprepare-delay-ms = <20>;
			width-mm = <153>;
			height-mm = <85>;
			dsi,flags = <0xa03>;
			dsi,format = <0>;
			dsi,lanes = <4>;
			panel-init-sequence = [15 00 02 ff 30 15 00 02 ff 52 15 00 02 ff 01 15 00 02 e3 00 15 00 02 25 10 15 00 02 28 6f 15 00 02 29 01 15 00 02 2a df 15 00 02 2c 22 15 00 02 c3 0f 15 00 02 37 9c 15 00 02 38 a7 15 00 02 39 41 15 00 02 80 20 15 00 02 91 67 15 00 02 92 67 15 00 02 a0 55 15 00 02 a1 50 15 00 02 a3 58 15 00 02 a4 9c 15 00 02 a7 02 15 00 02 a8 01 15 00 02 a9 21 15 00 02 aa fc 15 00 02 ab 28 15 00 02 ac 06 15 00 02 ad 06 15 00 02 ae 06 15 00 02 af 03 15 00 02 b0 08 15 00 02 b1 26 15 00 02 b2 28 15 00 02 b3 28 15 00 02 b4 03 15 00 02 b5 08 15 00 02 b6 26 15 00 02 b7 08 15 00 02 b8 26 15 00 02 c0 00 15 00 02 c1 00 15 00 02 c2 00 15 00 02 ff 30 15 00 02 ff 52 15 00 02 ff 02 15 00 02 b0 02 15 00 02 d0 02 15 00 02 b1 0f 15 00 02 d1 10 15 00 02 b2 11 15 00 02 d2 12 15 00 02 b3 32 15 00 02 d3 33 15 00 02 b4 36 15 00 02 d4 36 15 00 02 b5 3c 15 00 02 d5 3c 15 00 02 b6 20 15 00 02 d6 20 15 00 02 b7 3e 15 00 02 d7 3e 15 00 02 b8 0e 15 00 02 d8 0d 15 00 02 b9 05 15 00 02 d9 05 15 00 02 ba 11 15 00 02 da 12 15 00 02 bb 11 15 00 02 db 11 15 00 02 bc 13 15 00 02 dc 14 15 00 02 bd 14 15 00 02 dd 14 15 00 02 be 16 15 00 02 de 18 15 00 02 bf 0e 15 00 02 df 0f 15 00 02 c0 17 15 00 02 e0 17 15 00 02 c1 07 15 00 02 e1 08 15 00 02 ff 30 15 00 02 ff 52 15 00 02 ff 03 15 00 02 08 8a 15 00 02 09 8b 15 00 02 30 00 15 00 02 31 00 15 00 02 32 00 15 00 02 33 00 15 00 02 34 61 15 00 02 35 d4 15 00 02 36 24 15 00 02 37 03 15 00 02 40 86 15 00 02 41 87 15 00 02 42 84 15 00 02 43 85 15 00 02 44 11 15 00 02 45 de 15 00 02 46 dd 15 00 02 47 11 15 00 02 48 e0 15 00 02 49 df 15 00 02 50 82 15 00 02 51 83 15 00 02 52 80 15 00 02 53 81 15 00 02 54 11 15 00 02 55 e2 15 00 02 56 e1 15 00 02 57 11 15 00 02 58 e4 15 00 02 59 e3 15 00 02 82 0f 15 00 02 83 0f 15 00 02 84 00 15 00 02 85 0f 15 00 02 86 0f 15 00 02 87 0e 15 00 02 88 0e 15 00 02 89 06 15 00 02 8a 06 15 00 02 8b 07 15 00 02 8c 07 15 00 02 8d 04 15 00 02 8e 04 15 00 02 8f 05 15 00 02 90 05 15 00 02 98 0f 15 00 02 99 0f 15 00 02 9a 00 15 00 02 9b 0f 15 00 02 9c 0f 15 00 02 9d 0e 15 00 02 9e 0e 15 00 02 9f 06 15 00 02 a0 06 15 00 02 a1 07 15 00 02 a2 07 15 00 02 a3 04 15 00 02 a4 04 15 00 02 a5 05 15 00 02 a6 05 15 00 02 e0 02 15 00 02 e1 52 15 00 02 ff 30 15 00 02 ff 52 15 00 02 ff 00 15 00 02 36 02 05 c8 01 11 05 64 01 29];
			panel-exit-sequence = <0x5000128 0x5000110>;

			display-timings {
				native-mode = <&timing0>;

				timing0: adjust {
					clock-frequency = <30000000>;
					hactive = <640>;
					vactive = <480>;
					hfront-porch = <168>;
					hsync-len = <8>;
					hback-porch = <161>;
					vfront-porch = <16>;
					vsync-len = <2>;
					vback-porch = <14>;
					hsync-active = <0>;
					vsync-active = <0>;
					de-active = <0>;
					pixelclk-active = <0>;
				};

				timing1: origin {
					clock-frequency = <30000000>;
					hactive = <640>;
					vactive = <480>;
					hfront-porch = <46>;
					hsync-len = <2>;
					hback-porch = <44>;
					vfront-porch = <16>;
					vsync-len = <2>;
					vback-porch = <14>;
					hsync-active = <0>;
					vsync-active = <0>;
					de-active = <0>;
					pixelclk-active = <0>;
				};
			};
		};
	};

	vop: vop@ff460000 {
		compatible = "rockchip,px30-vop-big";
		reg = <0x00 0xff460000 0x00 0x1fc 0x00 0xff460a00 0x00 0x400>;
		rockchip,grf = <&grf>;
		reg-names = "regs", "gamma_lut";
		interrupts = <0x00 0x4d 0x04>;
		clocks = <&cru 0xb5>, <&cru 0x96>, <&cru 0xfb>;
		clock-names = "aclk_vop", "dclk_vop", "hclk_vop";
		power-domains = <&power 0x0c>;
		iommus = <&vopb_mmu>;
		status = "okay";
		phandle = <0x115>;

		vopb_out: port {
			#address-cells = <1>;
			#size-cells = <0>;
			phandle = <0x10>;

			vopb_out_lvds: endpoint@0 {
				reg = <0x00>;
				remote-endpoint = <&lvds_in_vopb>;
				phandle = <0x12>;
			};

			 vopb_out_dsi: endpoint@1 {
				reg = <0x01>;
				remote-endpoint = <&dsi_in_vopb>;
				phandle = <0x13>;
			};

			vopb_out_rgb: endpoint@2 {
				reg = <0x02>;
				remote-endpoint = <&rgb_in_vopb>;
				phandle = <0x14>;
			};
		};
	};

	vopb_mmu: iommu@ff460f00 {
		compatible = "rockchip,iommu";
		reg = <0x00 0xff460f00 0x00 0x100>;
		interrupts = <0x00 0x4d 0x04>;
		interrupt-names = "vopb_mmu";
		clocks = <&cru 0xb5>, <&cru 0xfb>;
		clock-names = "aclk", "hclk";
		power-domains = <&power 0x0c>;
		#iommu-cells = <0>;
		//rockchip,disable-device-link-resume;
		status = "okay";
	};

	rk_rga: rk_rga@ff480000 {
		compatible = "rockchip,rga2";
		reg = <0x00 0xff480000 0x00 0x1000>;
		interrupts = <0x00 0x4c 0x04>;
		clocks = <&cru 0xb7>, <&cru 0xfd>, <&cru 0x35>;
		clock-names = "aclk_rga", "hclk_rga", "clk_rga";
		power-domains = <&power 0x0c>;
		dma-coherent;
		status = "okay";
	};

	cif: cif@ff490000 {
		compatible = "rockchip,cif";
		reg = <0x00 0xff490000 0x00 0x200>;
		interrupts = <0x00 0x45 0x04>;
		clocks = <&cru 0xb3>, <&cru 0xf9>, <&cru 0x160>, <&cru 0x34>;
		clock-names = "aclk_cif0", "hclk_cif0", "pclk_cif", "cif0_out";
		resets = <&cru 0x2c>, <&cru 0x2d>, <&cru 0x2e>;
		reset-names = "rst_cif_a", "rst_cif_h", "rst_cif_pclkin";
		power-domains = <&power 0x0d>;
		pinctrl-names = "cif_pin_all";
		pinctrl-0 = <&dvp_d2d9_m0>;
		iommus = <&vip_mmu>;
		status = "disabled";
	};

	cif_new: cif-new@ff490000 {
		compatible = "rockchip,px30-cif";
		reg = <0x00 0xff490000 0x00 0x200>;
		interrupts = <0x00 0x45 0x04>;
		clocks = <&cru 0xb3>, <&cru 0xf9>, <&cru 0x160>, <&cru 0x34>;
		clock-names = "aclk_cif", "hclk_cif", "pclk_cif", "cif_out";
		resets = <&cru 0x2c>, <&cru 0x2d>, <&cru 0x2e>;
		reset-names = "rst_cif_a", "rst_cif_h", "rst_cif_pclkin";
		power-domains = <&power 0x0d>;
		iommus = <&vip_mmu>;
		status = "disabled";
	};

	vip_mmu: iommu@ff490800 {
		compatible = "rockchip,iommu";
		reg = <0x00 0xff490800 0x00 0x100>;
		interrupts = <0x00 0x45 0x04>;
		interrupt-names = "vip_mmu";
		clocks = <&cru 0xb3>, <&cru 0xf9>;
		clock-names = "aclk", "hclk";
		power-domains = <&power 0x0d>;
		rk_iommu,disable_reset_quirk;
		#iommu-cells = <0>;
		status = "disabled";
	};

	rk_isp: rk_isp@ff4a0000 {
		compatible = "rockchip,px30-isp", "rockchip,isp";
		reg = <0x00 0xff4a0000 0x00 0x8000>;
		interrupts = <0x00 0x46 0x04>;
		clocks = <&cru 0xb4>, <&cru 0xfa>, <&cru 0x33>, <&cru 0x33>, <&cru 0x15f>, <&cru 0x34>, <&cru 0x34>, <&cru 0x146>;
		clock-names = "aclk_isp", "hclk_isp", "clk_isp", "clk_isp_jpe", "pclkin_isp", "clk_cif_pll", "clk_cif_out", "pclk_dphyrx";
		resets = <&cru 0x2b>, <&cru 0x2f>;
		reset-names = "rst_isp", "rst_mipicsiphy";
		power-domains = <&power 0x0d>;
		pinctrl-names = "default", "isp_dvp8bit2", "isp_dvp10bit", "isp_dvp12bit";
		pinctrl-0 = <&cif_clkout_m0>;
		pinctrl-1 = <&dvp_d2d9_m0>;
		pinctrl-2 = <&dvp_d2d9_m0 &dvp_d10d11_m0>;
		pinctrl-3 = <&dvp_d0d1_m0 &dvp_d2d9_m0 &dvp_d10d11_m0>;
		rockchip,isp,mipiphy = <0x01>;
		rockchip,isp,csiphy,reg = <0xff2f0000 0x4000>;
		rockchip,grf = <&grf>;
		rockchip,cru = <&cru>;
		rockchip,isp,iommu-enable = <0x01>;
		iommus = <&isp_mmu>;
		status = "disabled";
	};

	rkisp1: rkisp1@ff4a0000 {
		compatible = "rockchip,rk3326-rkisp1";
		reg = <0x00 0xff4a0000 0x00 0x8000>;
		interrupts = <0x00 0x46 0x04 0x00 0x49 0x04 0x00 0x4a 0x04>;
		interrupt-names = "isp_irq", "mi_irq", "mipi_irq";
		clocks = <&cru 0xb4>, <&cru 0xfa>, <&cru 0x33>, <&cru 0x15f>;
		clock-names = "aclk_isp", "hclk_isp", "clk_isp", "pclk_isp";
		devfreq = <&dmc>;
		power-domains = <&power 0x0d>;
		iommus = <&isp_mmu>;
		rockchip,grf = <&grf>;
		status = "disabled";
	};

	isp_mmu: iommu@ff4a8000 {
		compatible = "rockchip,iommu";
		reg = <0x00 0xff4a8000 0x00 0x100>;
		interrupts = <0x00 0x46 0x04>;
		interrupt-names = "isp_mmu";
		clocks = <&cru 0xb4>, <&cru 0xfa>;
		clock-names = "aclk", "hclk";
		power-domains = <&power 0x0d>;
		rk_iommu,disable_reset_quirk;
		#iommu-cells = <0>;
		status = "okay";
	};

	qos_gmac: qos@ff518000 {
		compatible = "syscon";
		reg = <0x00 0xff518000 0x00 0x20>;
	};

	qos_gpu: qos@ff520000 {
		compatible = "syscon";
		reg = <0x00 0xff520000 0x00 0x20>;
	};

	qos_sdmmc: qos@ff52c000 {
		compatible = "syscon";
		reg = <0x00 0xff52c000 0x00 0x20>;
	};

	qos_emmc: qos@ff538000 {
		compatible = "syscon";
		reg = <0x00 0xff538000 0x00 0x20>;
	};

	qos_nand: qos@ff538080 {
		compatible = "syscon";
		reg = <0x00 0xff538080 0x00 0x20>;
	};

	qos_sdio: qos@ff538100 {
		compatible = "syscon";
		reg = <0x00 0xff538100 0x00 0x20>;
	};

	qos_sfc: qos@ff538180 {
		compatible = "syscon";
		reg = <0x00 0xff538180 0x00 0x20>;
	};

	qos_usb_host: qos@ff540000 {
		compatible = "syscon";
		reg = <0x00 0xff540000 0x00 0x20>;
	};

	qos_usb_otg: qos@ff540080 {
		compatible = "syscon";
		reg = <0x00 0xff540080 0x00 0x20>;
	};

	qos_isp_128: qos@ff548000 {
		compatible = "syscon";
		reg = <0x00 0xff548000 0x00 0x20>;
	};

	qos_isp_rd: qos@ff548080 {
		compatible = "syscon";
		reg = <0x00 0xff548080 0x00 0x20>;
	};

	qos_isp_wr: qos@ff548100 {
		compatible = "syscon";
		reg = <0x00 0xff548100 0x00 0x20>;
	};

	qos_isp_m1: qos@ff548180 {
		compatible = "syscon";
		reg = <0x00 0xff548180 0x00 0x20>;
	};

	qos_vip: qos@ff548200 {
		compatible = "syscon";
		reg = <0x00 0xff548200 0x00 0x20>;
	};

	qos_rga_rd: qos@ff550000 {
		compatible = "syscon";
		reg = <0x00 0xff550000 0x00 0x20>;
	};

	qos_rga_wr: qos@ff550080 {
		compatible = "syscon";
		reg = <0x00 0xff550080 0x00 0x20>;
	};

	qos_vop_m0: qos@ff550100 {
		compatible = "syscon";
		reg = <0x00 0xff550100 0x00 0x20>;
	};

	qos_vop_m1: qos@ff550180 {
		compatible = "syscon";
		reg = <0x00 0xff550180 0x00 0x20>;
	};

	qos_vpu: qos@ff558000 {
		compatible = "syscon";
		reg = <0x00 0xff558000 0x00 0x20>;
	};

	qos_vpu_r128: qos@ff558080 {
		compatible = "syscon";
		reg = <0x00 0xff558080 0x00 0x20>;
	};

	dfi: dfi@ff610000 {
		reg = <0x00 0xff610000 0x00 0x400>;
		compatible = "rockchip,px30-dfi";
		rockchip,pmugrf = <&pmugrf>;
		status = "okay";
	};

	dmc: dmc {
		compatible = "rockchip,px30-dmc";
		interrupts = <0x00 0x69 0x04>;
		interrupt-names = "complete_irq";
		devfreq-events = <&dfi>;
		clocks = <&cru 0x54>;
		clock-names = "dmc_clk";
		operating-points-v2 = <&dmc_opp_table>;
		ddr_timing = <&ddr_timing>;
		upthreshold = <0x28>;
		downdifferential = <0x14>;
		system-status-freq = <0x01 0x80e80 0x08 0x6ddd0 0x02 0x2f5d0 0x20 0x6ddd0 0x1000 0x80e80 0x4000 0xa2990 0x2000 0xa2990>;
		auto-min-freq = <0x50140>;
		auto-freq-en = <0x01>;
		#cooling-cells = <2>;
		status = "okay";
		center-supply = <&vdd_logic>;

		ddr_power_model: ddr_power_model {
			compatible = "ddr_power_model";
			dynamic-power-coefficient = <0x78>;
			static-power-coefficient = <0xc8>;
			ts = <0x7d00 0x125c 0xffffffb0 0x02>;
			thermal-zone = "soc-thermal";
		};
	};

	dmc-fsp {
		compatible = "rockchip,px30s-dmc-fsp";
		debug_print_level = <0x00>;
		phy_de_skew_en = <0x01>;
		ddr3_params = <&ddr3_params>;
		ddr4_params = <&ddr4_params>;
		lpddr2_params = <&lpddr2_params>;
		lpddr3_params = <&lpddr3_params>;
		lpddr4_params = <&lpddr4_params>;
		ddr_timing = <&ddr_timing>;
		status = "okay";
	};

	dmc_opp_table: dmc-opp-table {
		compatible = "operating-points-v2";
		rockchip,max-volt = <1150000>;
		rockchip,evb-irdrop = <25000>;
		rockchip,pvtm-voltage-sel = <0x00 0xc350 0x00 0xc351 0xd2f0 0x01 0xd2f1 0xea60 0x02 0xea61 0x1869f 0x03>;
		rockchip,pvtm-ch = <0x00 0x00>;


		opp-528000000 {
			opp-hz = <0x00 0x1f78a400>;
			opp-microvolt = <975000>;
			opp-microvolt-L0 = <975000>;
			opp-microvolt-L1 = <975000>;
			opp-microvolt-L2 = <950000>;
			opp-microvolt-L3 = <950000>;
		};

		opp-666000000 {
			opp-hz = <0x00 0x27b25a80>;
			opp-microvolt = <1050000>;
			opp-microvolt-L0 = <1050000>;
			opp-microvolt-L1 = <1000000>;
			opp-microvolt-L2 = <975000>;
			opp-microvolt-L3 = <950000>;
		};

		opp-786000000 {
			opp-hz = <0x00 0x2ed96880>;
			opp-microvolt = <1100000>;
			opp-microvolt-L0 = <1100000>;
			opp-microvolt-L1 = <1050000>;
			opp-microvolt-L2 = <1025000>;
			opp-microvolt-L3 = <1000000>;
			status = "disabled"; //maybe okay? needs testing?
		};
	};

	rockchip_system_monitor: rockchip-system-monitor {
		compatible = "rockchip,system-monitor";
		rockchip,thermal-zone = "soc-thermal";
		rockchip,polling-delay = <0xc8>;
	};

	pinctrl: pinctrl {
		compatible = "rockchip,px30-pinctrl";
		rockchip,grf = <&grf>;
		rockchip,pmu = <&pmugrf>;
		#address-cells = <2>;
		#size-cells = <2>;
		ranges;

		gpio0: gpio0@ff040000 {
			compatible = "rockchip,gpio-bank";
			reg = <0x00 0xff040000 0x00 0x100>;
			interrupts = <0x00 0x03 0x04>;
			clocks = <&pmucru 0x14>;
			gpio-controller;
			#gpio-cells = <2>;
			interrupt-controller;
			#interrupt-cells = <2>;
			phandle = <0x5e>;
		};

		gpio1: gpio1@ff250000 {
			compatible = "rockchip,gpio-bank";
			reg = <0x00 0xff250000 0x00 0x100>;
			interrupts = <0x00 0x04 0x04>;
			clocks = <&cru 0x15c>;
			gpio-controller;
			#gpio-cells = <2>;
			interrupt-controller;
			#interrupt-cells = <2>;
			phandle = <0x11e>;
		};

		gpio2: gpio2@ff260000 {
			compatible = "rockchip,gpio-bank";
			reg = <0x00 0xff260000 0x00 0x100>;
			interrupts = <0x00 0x05 0x04>;
			clocks = <&cru 0x15d>;
			gpio-controller;
			#gpio-cells = <2>;
			interrupt-controller;
			#interrupt-cells = <2>;
			phandle = <0xc3>;
		};

		gpio3: gpio3@ff270000 {
			compatible = "rockchip,gpio-bank";
			reg = <0x00 0xff270000 0x00 0x100>;
			interrupts = <0x00 0x06 0x04>;
			clocks = <&cru 0x15e>;
			gpio-controller;
			#gpio-cells = <2>;
			interrupt-controller;
			#interrupt-cells = <2>;
			phandle = <0x68>;
			//rumble_hold_low {
			//	gpio-hog;
			//	gpios = <0x06 0x00>; //0x06
			//	output-high;
			//	line-name = "rumble_en_hold_low";
			//};
		};

		pcfg_pull_up: pcfg-pull-up {
			bias-pull-up;
			phandle = <0xb7>;
		};

		pcfg_pull_down: pcfg-pull-down {
			bias-pull-down;
			phandle = <0x11f>;
		};

		pcfg_pull_none: pcfg-pull-none {
			bias-disable;
			phandle = <0xb6>;
		};

		pcfg_pull_none_2ma: pcfg-pull-none-2ma {
			bias-disable;
			drive-strength = <0x02>;
			phandle = <0x120>;
		};

		pcfg_pull_up_2ma: pcfg-pull-up-2ma {
			bias-pull-up;
			drive-strength = <0x02>;
			phandle = <0x121>;
		};

		pcfg_pull_up_4ma: pcfg-pull-up-4ma {
			bias-pull-up;
			drive-strength = <0x04>;
			phandle = <0xb8>;
		};

		pcfg_pull_none_4ma: pcfg-pull-none-4ma {
			bias-disable;
			drive-strength = <0x04>;
			phandle = <0x122>;
		};

		pcfg_pull_down_4ma: pcfg-pull-down-4ma {
			bias-pull-down;
			drive-strength = <0x04>;
			phandle = <0x123>;
		};

		pcfg_pull_none_8ma: pcfg-pull-none-8ma {
			bias-disable;
			drive-strength = <0x08>;
			phandle = <0xbb>;
		};

		pcfg_pull_up_8ma: pcfg-pull-up-8ma {
			bias-pull-up;
			drive-strength = <0x08>;
			phandle = <0xb9>;
		};

		pcfg_pull_none_12ma: pcfg-pull-none-12ma {
			bias-disable;
			drive-strength = <0x0c>;
			phandle = <0xbd>;
		};

		pcfg_pull_up_12ma: pcfg-pull-up-12ma {
			bias-pull-up;
			drive-strength = <0x0c>;
			phandle = <0xbc>;
		};

		pcfg_pull_none_smt: pcfg-pull-none-smt {
			bias-disable;
			input-schmitt-enable;
			phandle = <0xb5>;
		};

		pcfg_output_high: pcfg-output-high {
			output-high;
			phandle = <0x124>;
		};

		pcfg_output_low: pcfg-output-low {
			output-low;
			phandle = <0xbe>;
		};

		pcfg_input_high: pcfg-input-high {
			bias-pull-up;
			input-enable;
			phandle = <0xba>;
		};

		pcfg_input: pcfg-input {
			input-enable;
			phandle = <0x125>;
		};

		i2c0 {

			i2c0_xfer: i2c0-xfer {
				rockchip,pins = <0x00 0x08 0x01 &pcfg_pull_none_smt>, 
								<0x00 0x09 0x01 &pcfg_pull_none_smt>;
				phandle = <0x5d>;
			};
		};

		i2c1 {

			i2c1_xfer: i2c1-xfer {
				rockchip,pins = <0x00 0x12 0x01 &pcfg_pull_none_smt>, 
								<0x00 0x13 0x01 &pcfg_pull_none_smt>;
				phandle = <0x6b>;
			};
		};

		i2c2 {

			i2c2_xfer: i2c2-xfer {
				rockchip,pins = <0x02 0x0f 0x02 &pcfg_pull_none_smt>, 
								<0x02 0x10 0x02 &pcfg_pull_none_smt>;
				phandle = <0x6c>;
			};
		};

		i2c3 {

			i2c3_xfer: i2c3-xfer {
				rockchip,pins = <0x01 0x0c 0x04 &pcfg_pull_none_smt>, 
								<0x01 0x0d 0x04 &pcfg_pull_none_smt>;
				phandle = <0x6d>;
			};
		};

		tsadc {

			tsadc_otp_gpio: tsadc-otp-gpio {
				rockchip,pins = <0x00 0x06 0x00 &pcfg_pull_none>;
				phandle = <0x88>;
			};

			tsadc_otp_out: tsadc-otp-out {
				rockchip,pins = <0x00 0x06 0x01 &pcfg_pull_none>;
				phandle = <0x89>;
			};
		};

		uart0 {

			uart0_xfer: uart0-xfer {
				rockchip,pins = <0x00 0x0a 0x01 &pcfg_pull_up>, 
								<0x00 0x0b 0x01 &pcfg_pull_up>;
				phandle = <0x2c>;
			};

			uart0_cts: uart0-cts {
				rockchip,pins = <0x00 0x0c 0x01 &pcfg_pull_none>;
				phandle = <0x2d>;
			};

			uart0_rts: uart0-rts {
				rockchip,pins = <0x00 0x0d 0x01 &pcfg_pull_none>;
				phandle = <0x2e>;
			};

			uart0_rts_gpio: uart0-rts-gpio {
				rockchip,pins = <0x00 0x0d 0x00 &pcfg_pull_none>;
				phandle = <0x126>;
			};
		};

		uart1 {

			uart1_xfer: uart1-xfer {
				rockchip,pins = <0x01 0x11 0x01 &pcfg_pull_up>, 
								<0x01 0x10 0x01 &pcfg_pull_up>;
				phandle = <0x51>;
			};

			uart1_cts: uart1-cts {
				rockchip,pins = <0x01 0x12 0x01 &pcfg_pull_none>;
				phandle = <0x52>;
			};

			uart1_rts: uart1-rts {
				rockchip,pins = <0x01 0x13 0x01 &pcfg_pull_none>;
				phandle = <0x127>;
			};

			uart1_rts_gpio: uart1-rts-gpio {
				rockchip,pins = <0x01 0x13 0x00 &pcfg_pull_none>;
				phandle = <0x128>;
			};
		};

		uart2-m0 {

			uart2m0_xfer: uart2m0-xfer {
				rockchip,pins = <0x01 0x1a 0x02 &pcfg_pull_up>, 
								<0x01 0x1b 0x02 &pcfg_pull_up>;
				phandle = <0x53>;
			};
		};

		uart2-m1 {

			uart2m1_xfer: uart2m1-xfer {
				rockchip,pins = <0x02 0x0c 0x02 &pcfg_pull_up>, 
								<0x02 0x0e 0x02 &pcfg_pull_up>;
				phandle = <0x129>;
			};
		};

		uart3-m0 {

			uart3m0-xfer {
				rockchip,pins = <0x00 0x10 0x02 &pcfg_pull_up>, 
								<0x00 0x11 0x02 &pcfg_pull_up>;
				phandle = <0x12a>;
			};

			uart3m0-cts {
				rockchip,pins = <0x00 0x12 0x02 &pcfg_pull_none>;
				phandle = <0x12b>;
			};

			uart3m0-rts {
				rockchip,pins = <0x00 0x13 0x02 &pcfg_pull_none>;
				phandle = <0x12c>;
			};

			uart3m0-rts-gpio {
				rockchip,pins = <0x00 0x13 0x00 &pcfg_pull_none>;
				phandle = <0x12d>;
			};
		};

		uart3-m1 {

			uart3m1_xfer: uart3m1-xfer {
				rockchip,pins = <0x01 0x0e 0x02 &pcfg_pull_up>, 
								<0x01 0x0f 0x02 &pcfg_pull_up>;
				phandle = <0x54>;
			};

			uart3m1-cts {
				rockchip,pins = <0x01 0x0c 0x02 &pcfg_pull_none>;
				phandle = <0x55>;
			};

			uart3m1-rts {
				rockchip,pins = <0x01 0x0d 0x02 &pcfg_pull_none>;
				phandle = <0x56>;
			};

			uart3m1-rts-gpio {
				rockchip,pins = <0x01 0x0d 0x00 &pcfg_pull_none>;
				phandle = <0x12e>;
			};
		};

		uart4 {
			/omit-if-no-ref/
			uart4_xfer: uart4-xfer {
				rockchip,pins = <0x01 0x1c 0x02 &pcfg_pull_up>, 
								<0x01 0x1d 0x02 &pcfg_pull_up>;
				phandle = <0x57>;
			};
			/omit-if-no-ref/
			uart4-cts {
				rockchip,pins = <0x01 0x1e 0x02 &pcfg_pull_none>;
				phandle = <0x58>;
			};
			/omit-if-no-ref/
			uart4-rts {
				rockchip,pins = <0x01 0x1f 0x02 &pcfg_pull_none>;
				phandle = <0x59>;
			};
		};

		uart5 {

			uart5_xfer: uart5-xfer {
				rockchip,pins = <0x03 0x02 0x04 &pcfg_pull_up>, 
								<0x03 0x01 0x04 &pcfg_pull_up>;
				phandle = <0x5a>;
			};

			uart5_cts: uart5-cts {
				rockchip,pins = <0x03 0x03 0x04 &pcfg_pull_none>;
				phandle = <0x5b>;
			};

			uart5_rts: uart5-rts {
				rockchip,pins = <0x03 0x05 0x04 &pcfg_pull_none>;
				phandle = <0x5c>;
			};
		};

		spi0 {

			spi0-clk {
				rockchip,pins = <0x01 0x0f 0x03 &pcfg_pull_up_4ma>;
				phandle = <0x6e>;
			};

			spi0-csn {
				rockchip,pins = <0x01 0x0e 0x03 &pcfg_pull_up_4ma>;
				phandle = <0x6f>;
			};

			spi0-miso {
				rockchip,pins = <0x01 0x0d 0x03 &pcfg_pull_up_4ma>;
				phandle = <0x70>;
			};

			spi0-mosi {
				rockchip,pins = <0x01 0x0c 0x03 &pcfg_pull_up_4ma>;
				phandle = <0x71>;
			};

			spi0-clk-hs {
				rockchip,pins = <0x01 0x0f 0x03 &pcfg_pull_up_8ma>;
				phandle = <0x72>;
			};

			spi0-miso-hs {
				rockchip,pins = <0x01 0x0d 0x03 &pcfg_pull_up_8ma>;
				phandle = <0x73>;
			};

			spi0-mosi-hs {
				rockchip,pins = <0x01 0x0c 0x03 &pcfg_pull_up_8ma>;
				phandle = <0x74>;
			};
		};

		spi1 {

			spi1-clk {
				rockchip,pins = <0x03 0x0f 0x04 &pcfg_pull_up_4ma>;
				phandle = <0x75>;
			};

			spi1-csn0 {
				rockchip,pins = <0x03 0x09 0x04 &pcfg_pull_up_4ma>;
				phandle = <0x76>;
			};

			spi1-csn1 {
				rockchip,pins = <0x03 0x0a 0x02 &pcfg_pull_up_4ma>;
				phandle = <0x77>;
			};

			spi1-miso {
				rockchip,pins = <0x03 0x0e 0x04 &pcfg_pull_up_4ma>;
				phandle = <0x78>;
			};

			spi1-mosi {
				rockchip,pins = <0x03 0x0c 0x04 &pcfg_pull_up_4ma>;
				phandle = <0x79>;
			};

			spi1-clk-hs {
				rockchip,pins = <0x03 0x0f 0x04 &pcfg_pull_up_8ma>;
				phandle = <0x7a>;
			};

			spi1-miso-hs {
				rockchip,pins = <0x03 0x0e 0x04 &pcfg_pull_up_8ma>;
				phandle = <0x7b>;
			};

			spi1-mosi-hs {
				rockchip,pins = <0x03 0x0c 0x04 &pcfg_pull_up_8ma>;
				phandle = <0x7c>;
			};
		};

		pdm {

			pdm_clk0m0: pdm-clk0m0 {
				rockchip,pins = <0x03 0x16 0x02 &pcfg_pull_none>;
				phandle = <0x44>;
			};

			pdm-clk0m1 {
				rockchip,pins = <0x02 0x16 0x01 &pcfg_pull_none>;
				phandle = <0x12f>;
			};

			pdm_clk1: pdm-clk1 {
				rockchip,pins = <0x03 0x17 0x02 &pcfg_pull_none>;
				phandle = <0x45>;
			};

			pdm_sdi0m0: pdm-sdi0m0 {
				rockchip,pins = <0x03 0x1b 0x02 &pcfg_pull_none>;
				phandle = <0x46>;
			};

			pdm-sdi0m1 {
				rockchip,pins = <0x02 0x15 0x02 &pcfg_pull_none>;
				phandle = <0x130>;
			};

			pdm_sdi1: pdm-sdi1 {
				rockchip,pins = <0x03 0x18 0x02 &pcfg_pull_none>;
				phandle = <0x47>;
			};

			pdm_sdi2: pdm-sdi2 {
				rockchip,pins = <0x03 0x19 0x02 &pcfg_pull_none>;
				phandle = <0x48>;
			};

			pdm_sdi3: pdm-sdi3 {
				rockchip,pins = <0x03 0x1a 0x02 &pcfg_pull_none>;
				phandle = <0x49>;
			};

			pdm-clk0m0-sleep {
				rockchip,pins = <0x03 0x16 0x00 &pcfg_input_high>;
				phandle = <0x131>;
			};

			pdm-clk0m1-sleep {
				rockchip,pins = <0x02 0x16 0x00 &pcfg_input_high>;
				phandle = <0x132>;
			};

			pdm-clk1-sleep {
				rockchip,pins = <0x03 0x17 0x00 &pcfg_input_high>;
				phandle = <0x133>;
			};

			pdm-sdi0m0-sleep {
				rockchip,pins = <0x03 0x1b 0x00 &pcfg_input_high>;
				phandle = <0x134>;
			};

			pdm-sdi0m1-sleep {
				rockchip,pins = <0x02 0x15 0x00 &pcfg_input_high>;
				phandle = <0x135>;
			};

			pdm-sdi1-sleep {
				rockchip,pins = <0x03 0x18 0x00 &pcfg_input_high>;
				phandle = <0x136>;
			};

			pdm-sdi2-sleep {
				rockchip,pins = <0x03 0x19 0x00 &pcfg_input_high>;
				phandle = <0x137>;
			};

			pdm-sdi3-sleep {
				rockchip,pins = <0x03 0x1a 0x00 &pcfg_input_high>;
				phandle = <0x138>;
			};
		};

		i2s0 {
			/omit-if-no-ref/
			i2s0-8ch-mclk {
				rockchip,pins = <0x03 0x11 0x02 &pcfg_pull_none>;
				phandle = <0x139>;
			};
			/omit-if-no-ref/
			i2s0-8ch-sclktx {
				rockchip,pins = <0x03 0x13 0x02 &pcfg_pull_none>;
				phandle = <0x30>;
			};
			/omit-if-no-ref/
			i2s0-8ch-sclkrx {
				rockchip,pins = <0x03 0x0c 0x02 &pcfg_pull_none>;
				phandle = <0x31>;
			};
			/omit-if-no-ref/
			i2s0-8ch-lrcktx {
				rockchip,pins = <0x03 0x12 0x02 &pcfg_pull_none>;
				phandle = <0x32>;
			};
			/omit-if-no-ref/
			i2s0-8ch-lrckrx {
				rockchip,pins = <0x03 0x0d 0x02 &pcfg_pull_none>;
				phandle = <0x33>;
			};
			/omit-if-no-ref/
			i2s0-8ch-sdo0 {
				rockchip,pins = <0x03 0x14 0x02 &pcfg_pull_none>;
				phandle = <0x38>;
			};
			/omit-if-no-ref/
			i2s0-8ch-sdo1 {
				rockchip,pins = <0x03 0x10 0x02 &pcfg_pull_none>;
				phandle = <0x39>;
			};
			/omit-if-no-ref/
			i2s0-8ch-sdo2 {
				rockchip,pins = <0x03 0x0f 0x02 &pcfg_pull_none>;
				phandle = <0x3a>;
			};
			/omit-if-no-ref/
			i2s0-8ch-sdo3 {
				rockchip,pins = <0x03 0x0e 0x02 &pcfg_pull_none>;
				phandle = <0x3b>;
			};
			/omit-if-no-ref/
			i2s0-8ch-sdi0 {
				rockchip,pins = <0x03 0x15 0x02 &pcfg_pull_none>;
				phandle = <0x34>;
			};
			/omit-if-no-ref/
			i2s0-8ch-sdi1 {
				rockchip,pins = <0x03 0x0b 0x02 &pcfg_pull_none>;
				phandle = <0x35>;
			};
			/omit-if-no-ref/
			i2s0-8ch-sdi2 {
				rockchip,pins = <0x03 0x09 0x02 &pcfg_pull_none>;
				phandle = <0x36>;
			};
			/omit-if-no-ref/
			i2s0-8ch-sdi3 {
				rockchip,pins = <0x03 0x08 0x02 &pcfg_pull_none>;
				phandle = <0x37>;
			};
		};

		i2s1 {
			/omit-if-no-ref/
			i2s1_2ch_mclk: i2s1-2ch-mclk {
				rockchip,pins = <0x02 0x13 0x01 &pcfg_pull_none>;
				phandle = <0x6a>;
			};
			/omit-if-no-ref/
			i2s1_2ch_sclk: i2s1-2ch-sclk {
				rockchip,pins = <0x02 0x12 0x01 &pcfg_pull_none>;
				phandle = <0x3c>;
			};
			/omit-if-no-ref/
			i2s1_2ch_lrck: i2s1-2ch-lrck {
				rockchip,pins = <0x02 0x11 0x01 &pcfg_pull_none>;
				phandle = <0x3d>;
			};
			/omit-if-no-ref/
			i2s1_2ch_sdi: i2s1-2ch-sdi {
				rockchip,pins = <0x02 0x15 0x01 &pcfg_pull_none>;
				phandle = <0x3e>;
			};
			/omit-if-no-ref/
			i2s1_2ch_sdo: i2s1-2ch-sdo {
				rockchip,pins = <0x02 0x14 0x01 &pcfg_pull_none>;
				phandle = <0x3f>;
			};
		};

		i2s2 {
			/omit-if-no-ref/
			i2s2_2ch_mclk: i2s2-2ch-mclk {
				rockchip,pins = <0x03 0x01 0x02 &pcfg_pull_none>;
				phandle = <0x13a>;
			};
			/omit-if-no-ref/
			i2s2_2ch_sclk: i2s2-2ch-sclk {
				rockchip,pins = <0x03 0x02 0x02 &pcfg_pull_none>;
				phandle = <0x40>;
			};
			/omit-if-no-ref/
			i2s2_2ch_lrck: i2s2-2ch-lrck {
				rockchip,pins = <0x03 0x03 0x02 &pcfg_pull_none>;
				phandle = <0x41>;
			};
			/omit-if-no-ref/
			i2s2_2ch_sdi: i2s2-2ch-sdi {
				rockchip,pins = <0x03 0x05 0x02 &pcfg_pull_none>;
				phandle = <0x42>;
			};
			/omit-if-no-ref/
			i2s2_2ch_sdo: i2s2-2ch-sdo {
				rockchip,pins = <0x03 0x07 0x02 &pcfg_pull_none>;
				phandle = <0x43>;
			};
		};

		sdmmc {

			sdmmc_clk: sdmmc-clk {
				rockchip,pins = <0x01 0x1e 0x01 &pcfg_pull_none_8ma>;
				phandle = <0x90>;
			};

			sdmmc_cmd: sdmmc-cmd {
				rockchip,pins = <0x01 0x1f 0x01 &pcfg_pull_up_8ma>;
				phandle = <0x91>;
			};

			sdmmc_det: sdmmc-det {
				rockchip,pins = <0x00 0x03 0x01 &pcfg_pull_up_8ma>;
				phandle = <0x92>;
			};

			sdmmc_bus1: sdmmc-bus1 {
				rockchip,pins = <0x01 0x1a 0x01 &pcfg_pull_up_8ma>;
				phandle = <0x13b>;
			};

			sdmmc_bus4: sdmmc-bus4 {
				rockchip,pins = <0x01 0x1a 0x01 &pcfg_pull_up_8ma>, 
								<0x01 0x1b 0x01 &pcfg_pull_up_8ma>, 
								<0x01 0x1c 0x01 &pcfg_pull_up_8ma>, 
								<0x01 0x1d 0x01 &pcfg_pull_up_8ma>;
				phandle = <0x93>;
			};

			sdmmc_gpio: sdmmc-gpio {
				rockchip,pins = <0x01 0x1a 0x00 &pcfg_pull_up_4ma>, 
								<0x01 0x1b 0x00 &pcfg_pull_up_4ma>, 
								<0x01 0x1c 0x00 &pcfg_pull_up_4ma>, 
								<0x01 0x1d 0x00 &pcfg_pull_up_4ma>, 
								<0x01 0x1e 0x00 &pcfg_pull_up_4ma>, 
								<0x01 0x1f 0x00 &pcfg_pull_up_4ma>;
				phandle = <0x13c>;
			};
		};

		sdio {

			sdio_clk: sdio-clk {
				rockchip,pins = <0x01 0x15 0x01 &pcfg_pull_none>;
				phandle = <0x97>;
			};

			sdio_cmd: sdio-cmd {
				rockchip,pins = <0x01 0x14 0x01 &pcfg_pull_up>;
				phandle = <0x96>;
			};

			sdio_det: sdio-det {
				rockchip,pins = <0x00 0x02 0x00 &pcfg_pull_up_8ma>;
			};

			sdio_bus4: sdio-bus4 {
				rockchip,pins = <0x01 0x16 0x01 &pcfg_pull_up>, 
								<0x01 0x17 0x01 &pcfg_pull_up>, 
								<0x01 0x18 0x01 &pcfg_pull_up>, 
								<0x01 0x19 0x01 &pcfg_pull_up>;
				phandle = <0x95>;
			};

			sdio_gpio: sdio-gpio {
				rockchip,pins = <0x01 0x16 0x00 &pcfg_pull_up>, 
								<0x01 0x17 0x00 &pcfg_pull_up>, 
								<0x01 0x18 0x00 &pcfg_pull_up>, 
								<0x01 0x19 0x00 &pcfg_pull_up>, 
								<0x01 0x14 0x00 &pcfg_pull_up>, 
								<0x01 0x15 0x00 &pcfg_pull_up>;
				phandle = <0x13d>;
			};
		};

		emmc {
			/omit-if-no-ref/
			emmc_clk: emmc-clk {
				rockchip,pins = <0x01 0x09 0x02 &pcfg_pull_none_8ma>;
				phandle = <0x99>;
			};
			/omit-if-no-ref/
			emmc_cmd: emmc-cmd {
				rockchip,pins = <0x01 0x0a 0x02 &pcfg_pull_up_8ma>;
				phandle = <0x9a>;
			};
			/omit-if-no-ref/
			emmc_pwren: emmc-pwren {
				rockchip,pins = <0x01 0x08 0x02 &pcfg_pull_none>;
				phandle = <0x9c>;
			};
			/omit-if-no-ref/
			emmc_rstnout: emmc-rstnout {
				rockchip,pins = <0x01 0x0b 0x02 &pcfg_pull_none>;
				phandle = <0x9d>;
			};
			/omit-if-no-ref/
			emmc_bus1: emmc-bus1 {
				rockchip,pins = <0x01 0x00 0x02 &pcfg_pull_up_8ma>;
				phandle = <0x13e>;
			};
			/omit-if-no-ref/
			emmc_bus4: emmc-bus4 {
				rockchip,pins = <0x01 0x00 0x02 &pcfg_pull_up_8ma>, 
								<0x01 0x01 0x02 &pcfg_pull_up_8ma>, 
								<0x01 0x02 0x02 &pcfg_pull_up_8ma>, 
								<0x01 0x03 0x02 &pcfg_pull_up_8ma>;
				phandle = <0x13f>;
			};
			/omit-if-no-ref/
			emmc_bus8: emmc-bus8 {
				rockchip,pins = <0x01 0x00 0x02 &pcfg_pull_up_8ma>, 
								<0x01 0x01 0x02 &pcfg_pull_up_8ma>, 
								<0x01 0x02 0x02 &pcfg_pull_up_8ma>, 
								<0x01 0x03 0x02 &pcfg_pull_up_8ma>, 
								<0x01 0x04 0x02 &pcfg_pull_up_8ma>, 
								<0x01 0x05 0x02 &pcfg_pull_up_8ma>, 
								<0x01 0x06 0x02 &pcfg_pull_up_8ma>, 
								<0x01 0x07 0x02 &pcfg_pull_up_8ma>;
				phandle = <0x9b>;
			};
		};

		flash {
			/omit-if-no-ref/
			flash-cs0 {
				rockchip,pins = <0x01 0x08 0x01 &pcfg_pull_none>;
				phandle = <0x140>;
			};
			/omit-if-no-ref/
			flash-rdy {
				rockchip,pins = <0x01 0x09 0x01 &pcfg_pull_none>;
				phandle = <0x141>;
			};
			/omit-if-no-ref/
			flash-dqs {
				rockchip,pins = <0x01 0x0a 0x01 &pcfg_pull_none>;
				phandle = <0x142>;
			};
			/omit-if-no-ref/
			flash-ale {
				rockchip,pins = <0x01 0x0b 0x01 &pcfg_pull_none>;
				phandle = <0x143>;
			};
			/omit-if-no-ref/
			flash-cle {
				rockchip,pins = <0x01 0x0c 0x01 &pcfg_pull_none>;
				phandle = <0x144>;
			};
			/omit-if-no-ref/
			flash-wrn {
				rockchip,pins = <0x01 0x0d 0x01 &pcfg_pull_none>;
				phandle = <0x145>;
			};
			/omit-if-no-ref/
			flash-csl {
				rockchip,pins = <0x01 0x0e 0x01 &pcfg_pull_none>;
				phandle = <0x146>;
			};
			/omit-if-no-ref/
			flash-rdn {
				rockchip,pins = <0x01 0x0f 0x01 &pcfg_pull_none>;
				phandle = <0x147>;
			};
			/omit-if-no-ref/
			flash-bus8 {
				rockchip,pins = <0x01 0x00 0x01 &pcfg_pull_up_12ma>, 
								<0x01 0x01 0x01 &pcfg_pull_up_12ma>, 
								<0x01 0x02 0x01 &pcfg_pull_up_12ma>, 
								<0x01 0x03 0x01 &pcfg_pull_up_12ma>, 
								<0x01 0x04 0x01 &pcfg_pull_up_12ma>, 
								<0x01 0x05 0x01 &pcfg_pull_up_12ma>, 
								<0x01 0x06 0x01 &pcfg_pull_up_12ma>, 
								<0x01 0x07 0x01 &pcfg_pull_up_12ma>;
				phandle = <0x148>;
			};
		};

		lcdc {
			/omit-if-no-ref/
			lcdc_m0_rgb_pins: lcdc-m0-rgb-pins {
				rockchip,pins = <0x03 0x00 0x01 &pcfg_pull_none_8ma>, 
								<0x03 0x01 0x01 &pcfg_pull_none_8ma>, 
								<0x03 0x02 0x01 &pcfg_pull_none_8ma>, 
								<0x03 0x03 0x01 &pcfg_pull_none_8ma>, 
								<0x03 0x04 0x01 &pcfg_pull_none_8ma>, 
								<0x03 0x05 0x01 &pcfg_pull_none_8ma>, 
								<0x03 0x06 0x01 &pcfg_pull_none_8ma>, 
								<0x03 0x07 0x01 &pcfg_pull_none_8ma>, 
								<0x03 0x08 0x01 &pcfg_pull_none_8ma>, 
								<0x03 0x09 0x01 &pcfg_pull_none_8ma>, 
								<0x03 0x0a 0x01 &pcfg_pull_none_8ma>, 
								<0x03 0x0b 0x01 &pcfg_pull_none_8ma>, 
								<0x03 0x0c 0x01 &pcfg_pull_none_8ma>, 
								<0x03 0x0d 0x01 &pcfg_pull_none_8ma>, 
								<0x03 0x0e 0x01 &pcfg_pull_none_8ma>, 
								<0x03 0x0f 0x01 &pcfg_pull_none_8ma>, 
								<0x03 0x10 0x01 &pcfg_pull_none_8ma>, 
								<0x03 0x11 0x01 &pcfg_pull_none_8ma>, 
								<0x03 0x12 0x01 &pcfg_pull_none_8ma>, 
								<0x03 0x13 0x01 &pcfg_pull_none_8ma>, 
								<0x03 0x14 0x01 &pcfg_pull_none_8ma>, 
								<0x03 0x15 0x01 &pcfg_pull_none_8ma>, 
								<0x03 0x16 0x01 &pcfg_pull_none_8ma>, 
								<0x03 0x17 0x01 &pcfg_pull_none_8ma>, 
								<0x03 0x18 0x01 &pcfg_pull_none_8ma>, 
								<0x03 0x19 0x01 &pcfg_pull_none_8ma>, 
								<0x03 0x1a 0x01 &pcfg_pull_none_8ma>, 
								<0x03 0x1b 0x01 &pcfg_pull_none_8ma>;
				phandle = <0x149>;
			};
			/omit-if-no-ref/
			lcdc_m0_sleep_pins: lcdc-m0-sleep-pins {
				rockchip,pins = <0x03 0x00 0x00 &pcfg_pull_none>, 
								<0x03 0x01 0x00 &pcfg_pull_none>, 
								<0x03 0x02 0x00 &pcfg_pull_none>, 
								<0x03 0x03 0x00 &pcfg_pull_none>, 
								<0x03 0x04 0x00 &pcfg_pull_none>, 
								<0x03 0x05 0x00 &pcfg_pull_none>, 
								<0x03 0x06 0x00 &pcfg_pull_none>, 
								<0x03 0x07 0x00 &pcfg_pull_none>, 
								<0x03 0x08 0x00 &pcfg_pull_none>, 
								<0x03 0x09 0x00 &pcfg_pull_none>, 
								<0x03 0x0a 0x00 &pcfg_pull_none>, 
								<0x03 0x0b 0x00 &pcfg_pull_none>, 
								<0x03 0x0c 0x00 &pcfg_pull_none>, 
								<0x03 0x0d 0x00 &pcfg_pull_none>, 
								<0x03 0x0e 0x00 &pcfg_pull_none>, 
								<0x03 0x0f 0x00 &pcfg_pull_none>, 
								<0x03 0x10 0x00 &pcfg_pull_none>, 
								<0x03 0x11 0x00 &pcfg_pull_none>, 
								<0x03 0x12 0x00 &pcfg_pull_none>, 
								<0x03 0x13 0x00 &pcfg_pull_none>, 
								<0x03 0x14 0x00 &pcfg_pull_none>, 
								<0x03 0x15 0x00 &pcfg_pull_none>, 
								<0x03 0x16 0x00 &pcfg_pull_none>, 
								<0x03 0x17 0x00 &pcfg_pull_none>, 
								<0x03 0x18 0x00 &pcfg_pull_none>, 
								<0x03 0x19 0x00 &pcfg_pull_none>, 
								<0x03 0x1a 0x00 &pcfg_pull_none>, 
								<0x03 0x1b 0x00 &pcfg_pull_none>;
				phandle = <0x14a>;
			};
			/omit-if-no-ref/
			lcdc_m1_rgb_pins: lcdc-m1-rgb-pins {
				rockchip,pins = <0x03 0x00 0x01 &pcfg_pull_none_8ma>, 
								<0x03 0x04 0x01 &pcfg_pull_none_8ma>, 
								<0x03 0x06 0x01 &pcfg_pull_none_8ma>, 
								<0x03 0x0a 0x01 &pcfg_pull_none_8ma>, 
								<0x03 0x0b 0x01 &pcfg_pull_none_8ma>, 
								<0x03 0x0d 0x01 &pcfg_pull_none_8ma>, 
								<0x03 0x10 0x01 &pcfg_pull_none_8ma>, 
								<0x03 0x11 0x01 &pcfg_pull_none_8ma>, 
								<0x03 0x12 0x01 &pcfg_pull_none_8ma>, 
								<0x03 0x13 0x01 &pcfg_pull_none_8ma>, 
								<0x03 0x14 0x01 &pcfg_pull_none_8ma>, 
								<0x03 0x15 0x01 &pcfg_pull_none_8ma>, 
								<0x03 0x16 0x01 &pcfg_pull_none_8ma>, 
								<0x03 0x17 0x01 &pcfg_pull_none_8ma>, 
								<0x03 0x18 0x01 &pcfg_pull_none_8ma>, 
								<0x03 0x19 0x01 &pcfg_pull_none_8ma>, 
								<0x03 0x1a 0x01 &pcfg_pull_none_8ma>, 
								<0x03 0x1b 0x01 &pcfg_pull_none_8ma>;
				phandle = <0x4f>;
			};
			/omit-if-no-ref/
			lcdc_m1_sleep_pins: lcdc-m1-sleep-pins {
				rockchip,pins = <0x03 0x00 0x00 &pcfg_pull_none>, 
								<0x03 0x04 0x00 &pcfg_pull_none>, 
								<0x03 0x06 0x00 &pcfg_pull_none>, 
								<0x03 0x0a 0x00 &pcfg_pull_none>, 
								<0x03 0x0b 0x00 &pcfg_pull_none>, 
								<0x03 0x0d 0x00 &pcfg_pull_none>, 
								<0x03 0x10 0x00 &pcfg_pull_none>, 
								<0x03 0x11 0x00 &pcfg_pull_none>, 
								<0x03 0x12 0x00 &pcfg_pull_none>, 
								<0x03 0x13 0x00 &pcfg_pull_none>, 
								<0x03 0x14 0x00 &pcfg_pull_none>, 
								<0x03 0x15 0x00 &pcfg_pull_none>, 
								<0x03 0x16 0x00 &pcfg_pull_none>, 
								<0x03 0x17 0x00 &pcfg_pull_none>, 
								<0x03 0x18 0x00 &pcfg_pull_none>, 
								<0x03 0x19 0x00 &pcfg_pull_none>, 
								<0x03 0x1a 0x00 &pcfg_pull_none>, 
								<0x03 0x1b 0x00 &pcfg_pull_none>;
				phandle = <0x50>;
			};
		};

		pwm0 {

			pwm0_pin: pwm0-pin {
			    rockchip,pins = <0x00 0x0f 0x01 &pcfg_pull_none>; //GPIO0_B7/PWM0/OTG_DRV Func2 RK3326 0 15 1
				//0 RK_PB7 1 &pcfg_pull_none
				phandle = <0x7d>;
			};
		};

		pwm1 {

			pwm1_pin: pwm1-pin {
				rockchip,pins = <0x00 0x10 0x01 &pcfg_pull_none>; //GPIO0_C0/ PWM1 Func3 RK3326 Backlight 0 16 2
				//<0 RK_PC0 1 &pcfg_pull_none>;
				phandle = <0x7e>;
			};
		};

		pwm2 {
			/omit-if-no-ref/
			pwm2_pin: pwm2-pin {
				rockchip,pins = <0x02 0x0d 0x01 &pcfg_pull_none>; //2 RK_PB5 1 &pcfg_pull_none
				phandle = <0x7f>;
			};
		};

		pwm3 {
			/omit-if-no-ref/
			pwm3_pin: pwm3-pin {
				rockchip,pins = <0x00 0x11 0x01 &pcfg_pull_none>; //0 RK_PC1 1 &pcfg_pull_none
				phandle = <0x80>;
			};
		};

		pwm4 {
			/omit-if-no-ref/
			pwm4_pin: pwm4-pin { //GameForce Chi Rumble L
				rockchip,pins = <0x03 0x12 0x03 &pcfg_pull_none>; //3 RK_PC2 3 &pcfg_pull_none 
				phandle = <0x81>;
			};
		};

		pwm5 {
			/omit-if-no-ref/
			pwm5_pin: pwm5-pin { //GameForce Chi Rumble R
				rockchip,pins = <0x03 0x13 0x03 &pcfg_pull_none>; //3 RK_PC3 3 &pcfg_pull_none
				phandle = <0x82>;
			};
		};

		pwm6 {
			/omit-if-no-ref/
			pwm6_pin: pwm6-pin {
				rockchip,pins = <0x03 0x14 0x03 &pcfg_pull_none>; //3 RK_PC4 3 &pcfg_pull_none
				phandle = <0x83>;
			};
		};

		pwm7 {
			/omit-if-no-ref/
			pwm7_pin: pwm7-pin {
				rockchip,pins = <0x03 0x15 0x03 &pcfg_pull_none>; //3 RK_PC5 3 &pcfg_pull_none
				phandle = <0x84>;
			};
		};

		gmac {
			/omit-if-no-ref/
			rmii-pins {
				rockchip,pins = <0x02 0x00 0x02 &pcfg_pull_none_12ma>, 
								<0x02 0x01 0x02 &pcfg_pull_none_12ma>, 
								<0x02 0x02 0x02 &pcfg_pull_none_12ma>, 
								<0x02 0x03 0x02 &pcfg_pull_none>, 
								<0x02 0x04 0x02 &pcfg_pull_none>, 
								<0x02 0x05 0x02 &pcfg_pull_none>, 
								<0x02 0x06 0x02 &pcfg_pull_none>, 
								<0x02 0x07 0x02 &pcfg_pull_none>, 
								<0x02 0x09 0x02 &pcfg_pull_none>;
				phandle = <0x8e>;
			};	
			/omit-if-no-ref/
			mac-refclk-12ma {
				rockchip,pins = <0x02 0x0a 0x02 &pcfg_pull_none_12ma>;
				phandle = <0x8f>;
			};
			/omit-if-no-ref/
			mac-refclk {
				rockchip,pins = <0x02 0x0a 0x02 &pcfg_pull_none>;
				phandle = <0x14b>;
			};
		};

		cif-m0 {
			/omit-if-no-ref/
			cif_clkout_m0: cif-clkout-m0 {
				rockchip,pins = <0x02 0x0b 0x01 &pcfg_pull_none_12ma>;
				phandle = <0xac>;
			};
			/omit-if-no-ref/
			dvp_d2d9_m0: dvp-d2d9-m0 {
				rockchip,pins = <0x02 0x00 0x01 &pcfg_pull_none>, 
								<0x02 0x01 0x01 &pcfg_pull_none>, 
								<0x02 0x02 0x01 &pcfg_pull_none>, 
								<0x02 0x03 0x01 &pcfg_pull_none>, 
								<0x02 0x04 0x01 &pcfg_pull_none>, 
								<0x02 0x05 0x01 &pcfg_pull_none>, 
								<0x02 0x06 0x01 &pcfg_pull_none>, 
								<0x02 0x07 0x01 &pcfg_pull_none>, 
								<0x02 0x08 0x01 &pcfg_pull_none>, 
								<0x02 0x09 0x01 &pcfg_pull_none>, 
								<0x02 0x0a 0x01 &pcfg_pull_none>, 
								<0x02 0x0b 0x01 &pcfg_pull_none>;
				phandle = <0xaa>;
			};
			/omit-if-no-ref/
			dvp_d0d1_m0: dvp-d0d1-m0 {
				rockchip,pins = <0x02 0x0c 0x01 &pcfg_pull_none>, 
								<0x02 0x0e 0x01 &pcfg_pull_none>;
				phandle = <0xae>;
			};
			/omit-if-no-ref/
			dvp_d10d11_m0: d10-d11-m0 {
				rockchip,pins = <0x02 0x0f 0x01 &pcfg_pull_none>, 
								<0x02 0x10 0x01 &pcfg_pull_none>;
				phandle = <0xad>;
			};
		};

		cif-m1 {
			/omit-if-no-ref/
			cif-clkout-m1 {
				rockchip,pins = <0x03 0x18 0x03 &pcfg_pull_none>;
				phandle = <0x14c>;
			};
			/omit-if-no-ref/
			dvp-d2d9-m1 {
				rockchip,pins = <0x03 0x03 0x03 &pcfg_pull_none>, 
								<0x03 0x05 0x03 &pcfg_pull_none>, 
								<0x03 0x07 0x03 &pcfg_pull_none>, 
								<0x03 0x08 0x03 &pcfg_pull_none>, 
								<0x03 0x09 0x03 &pcfg_pull_none>, 
								<0x03 0x0c 0x03 &pcfg_pull_none>, 
								<0x03 0x0e 0x03 &pcfg_pull_none>, 
								<0x03 0x0f 0x03 &pcfg_pull_none>, 
								<0x03 0x19 0x03 &pcfg_pull_none>, 
								<0x03 0x1a 0x03 &pcfg_pull_none>, 
								<0x03 0x1b 0x03 &pcfg_pull_none>, 
								<0x03 0x18 0x03 &pcfg_pull_none>;
				phandle = <0x14d>;
			};
			/omit-if-no-ref/
			dvp-d0d1-m1 {
				rockchip,pins = <0x03 0x01 0x03 &pcfg_pull_none>, 
								<0x03 0x02 0x03 &pcfg_pull_none>;
				phandle = <0x14e>;
			};
			/omit-if-no-ref/
			d10-d11-m1 {
				rockchip,pins = <0x03 0x16 0x03 &pcfg_pull_none>, 
								<0x03 0x17 0x03 &pcfg_pull_none>;
				phandle = <0x14f>;
			};
		};

		isp {
			/omit-if-no-ref/
			isp_prelight: isp-prelight {
				rockchip,pins = <0x03 0x19 0x04 &pcfg_pull_none>;
				phandle = <0x150>;
			};
		};

		pmic {

			pmic_int: pmic_int {
				rockchip,pins = <0x00 0x0a 0x00 &pcfg_pull_up>;
				phandle = <0x5f>;
			};

			soc_slppin_gpio: soc_slppin_gpio {
				rockchip,pins = <0x00 0x04 0x00 &pcfg_output_low>;
				phandle = <0x62>;
			};

			soc_slppin_slp: soc_slppin_slp {
				rockchip,pins = <0x00 0x04 0x01 &pcfg_pull_none>;
				phandle = <0x60>;
			};

			soc_slppin_rst: soc_slppin_rst {
				rockchip,pins = <0x00 0x04 0x02 &pcfg_pull_none>;
				phandle = <0x64>;
			};
		};

		 vcc18-lcd {

			vcc18_lcd_n: vcc18-lcd-n {
				rockchip,pins = <0x00 0x0d 0x00 &pcfg_pull_none>;
				phandle = <0xc8>;
			};
		};

		vcc5-usb {

			vcc5_usb: vcc5-usb {
				rockchip,pins = <0x03 0x04 0x00 &pcfg_pull_none>;
				phandle = <0xc9>;
			};
		};

		u2phy {
			
			u2phy_host_pin: host-port {
				rockchip,pins = <0x03 0x04 0x00 &pcfg_pull_none>;
			};
			
			u2phy_otg_pin: host-otg {
				rockchip,pins = <0x03 0x04 0x00 &pcfg_pull_none>;
			};
		};

		leds {

			led_pins: led-pins {
				rockchip,pins = <0x00 0x00 0x00 &pcfg_pull_none>, //Blue/Green led GPIO0 RK_PA0
								<0x00 0x11 0x00 &pcfg_pull_none>,//Red led GPIO0 RK_PB3
								<0x00 0x01 0x00 &pcfg_pull_none>,//Charge led (with missing resistors)
								<0x00 0x0b 0x00 &pcfg_pull_none>,//work_blue_gpio
								<0x00 0x0c 0x00 &pcfg_pull_none>;//work_red_gpio
			};
		};

		haptic {
	
			motor_pin: motor-pin {
				rockchip,pins = <0x03 0x06 0x00 &pcfg_pull_none>;
				
			};
		};

		btns {

			btn_pins: btn-pins {
				rockchip,pins = <0x03 0x0b 0x00 &pcfg_pull_up>, 
								<0x03 0x0c 0x00 &pcfg_pull_up>, 
								<0x03 0x0d 0x00 &pcfg_pull_up>, 
								<0x03 0x0e 0x00 &pcfg_pull_up>, 
								<0x03 0x10 0x00 &pcfg_pull_up>, 
								<0x03 0x11 0x00 &pcfg_pull_up>, 
								<0x03 0x12 0x00 &pcfg_pull_up>, 
								<0x03 0x13 0x00 &pcfg_pull_up>, 
								<0x03 0x14 0x00 &pcfg_pull_up>, 
								<0x03 0x15 0x00 &pcfg_pull_up>, 
								<0x03 0x16 0x00 &pcfg_pull_up>, 
								<0x03 0x17 0x00 &pcfg_pull_up>, 
								<0x03 0x18 0x00 &pcfg_pull_up>, 
								<0x03 0x19 0x00 &pcfg_pull_up>, 
								<0x03 0x0a 0x00 &pcfg_pull_up>, 
								<0x03 0x0f 0x00 &pcfg_pull_up>, 
								<0x02 0x0d 0x00 &pcfg_pull_up>, 
								<0x02 0x0e 0x00 &pcfg_pull_up>;
				phandle = <0xc2>;
			};
			amux_pins: amux-pins {
				rockchip,pins = <0x02 12 0x00 &pcfg_pull_none>, 
								<0x02 15 0x00 &pcfg_pull_none>, 
								<0x02 16 0x00 &pcfg_pull_none>;
			};
			rumble_pin: rumble-pin {
				rockchip,pins = <0x03 0x06 0x00 &pcfg_pull_none>;
			};
		};

		headphone {

			hp_det: hp-det {
				rockchip,pins = <0x02 0x16 0x00 &pcfg_pull_up>;
				phandle = <0xc5>;
			};
			spk_ctl_pin: spk-ctl-pin {
				rockchip,pins = <0x03 7 0x00 &pcfg_pull_none>;
			};
		};
	};

	chosen {
		bootargs = [00];
	};

	fiq-debugger { //output at wrong baud rate? Wrong system clock speeds?
		compatible = "rockchip,fiq-debugger";
		rockchip,serial-id = <5>;
		rockchip,wake-irq = <0x00>;
		/* If enable uart uses irq instead of fiq */
		rockchip,irq-mode-enable = <1>;
		rockchip,baudrate = <1500000>;/* Only 115200 and 1500000 */
		interrupts = <0x00 127 0x08>;
		pinctrl-names = "default";
		pinctrl-0 = <&uart5_xfer>;
		status = "okay";
	};

	ramoops {
		compatible = "ramoops";
		record-size = <0x00 0x20000>;
		console-size = <0x00 0x80000>;
		ftrace-size = <0x00 0x00>;
		pmsg-size = <0x00 0x00>;
		memory-region = <&ramoops_mem>;
	};

	reserved-memory {
		#address-cells = <2>;
		#size-cells = <2>;
		ranges;

		drm_logo: drm-logo@00000000 {
			compatible = "rockchip,drm-logo";
			reg = <0x00 0x00 0x00 0x00>;
			phandle = <0x11>;
		};

		ramoops_mem: region@110000 {
			reg = <0x00 0x110000 0x00 0xf0000>;
			reg-names = "ramoops_mem";
			phandle = <0xbf>;
		};
	};

	vol_keys: rg351-keys {
		compatible = "rockchip,key";
		io-channels = <&saradc 2>;
		poll-interval = <50>;
		autorepeat;
		
		repeat-delay-ms = <300>;
		repeat-period-ms = <40>;
		vol-down-key {
			linux,code = <0x72>;
			label = "volume down";
			rockchip,adc_value = <166>;
		};
		
		vol-up-key {
			linux,code = <0x73>;
			label = "volume up";
			rockchip,adc_value = <9>;
		};
	};

	odroidgo3-joypad {
		compatible = "odroidgo3-joypad";
		pwms = <&pwm0 0 200000000 0>;
		pwm-names = "enable";
		rumble-gpio = <&gpio3 6 0x00>;
		rumble-boost-weak = <0x00>;
		rumble-boost-strong = <0x00>;
		joypad-name = "GO-Super Gamepad";
		joypad-product = <0x1100>;
		joypad-revision = <0x100>;
		status = "okay";
		
		pinctrl-names = "default";
		pinctrl-0 = <&btn_pins &amux_pins &rumble_pin>;
		pinctrl-1 = <&pwm0_pin>;
		io-channel-names = "amux_adc";
		io-channels = <&saradc 1>;
		
		amux-count = <0x04>;
		amux-channel-mapping = <2 3 1 0>;
		amux-a-gpios = <&gpio2 16 1>;
		amux-b-gpios = <&gpio2 15 1>;
		amux-en-gpios = <&gpio2 12 1>;
		button-adc-scale = <2>;
		button-adc-deadzone = <64>;
		button-adc-fuzz = <32>;
		button-adc-flat = <32>;
		abs_x-p-tuning = <200>;
		abs_x-n-tuning = <200>;
		abs_y-p-tuning = <200>;
		abs_y-n-tuning = <200>;
		abs_rx-p-tuning = <200>;
		abs_rx-n-tuning = <200>;
		abs_ry-p-tuning = <200>;
		abs_ry-n-tuning = <200>;
		poll-interval = <10>;
		invert-absx;
		invert-absy;

		sw1 {
			gpios = <&gpio3 0x16 0x01>;
			label = "GPIO DPAD-UP";
			linux,code = <0x220>;
		};

		sw2 {
			gpios = <&gpio3 0x17 0x01>;
			label = "GPIO DPAD-DOWN";
			linux,code = <0x221>;
		};

		sw3 {
			gpios = <&gpio3 0x14 0x01>;
			label = "GPIO DPAD-LEFT";
			linux,code = <0x222>;
		};

		sw4 {
			gpios = <&gpio3 0x15 0x01>;
			label = "GPIO DPAD-RIGHT";
			linux,code = <0x223>;
		};

		sw5 {
			gpios = <&gpio3 0x10 0x01>;
			label = "GPIO BTN-A";
			linux,code = <0x131>;
		};

		sw6 {
			gpios = <&gpio3 0x11 0x01>;
			label = "GPIO BTN-B";
			linux,code = <0x130>;
		};

		sw7 {
			gpios = <&gpio3 0x13 0x01>;
			label = "GPIO BTN-Y";
			linux,code = <0x134>;
		};

		sw8 {
			gpios = <&gpio3 0x12 0x01>;
			label = "GPIO BTN-X";
			linux,code = <0x133>;
		};

		sw11 {
			gpios = <&gpio2 0x0e 0x01>;
			label = "BTN_THUMBR";
			linux,code = <0x2c3>;
		};

		sw12 {
			gpios = <&gpio2 0x0d 0x01>;
			label = "BTN_THUMBL";
			linux,code = <0x2c2>;
		};

		sw13 {
			gpios = <&gpio3 0x0a 0x01>;
			label = "GPIO BTN_F";
			linux,code = <0x2c4>;
		};

		sw15 {
			gpios = <&gpio3 0x0d 0x01>;
			label = "GPIO BTN_TL";
			linux,code = <0x136>;
		};

		sw16 {
			gpios = <&gpio3 0x0b 0x01>;
			label = "GPIO BTN_TR";
			linux,code = <0x137>;
		};

		sw19 {
			gpios = <&gpio3 0x18 0x01>;
			label = "BTN_SELECT";
			linux,code = <0x2c0>;
		};

		sw20 {
			gpios = <&gpio3 0x0c 0x01>;
			label = "GPIO BTN_TR2";
			linux,code = <0x139>;
		};

		sw21 {
			gpios = <&gpio3 0x0e 0x01>;
			label = "GPIO BTN_TL2";
			linux,code = <0x138>;
		};

		sw22 {
			gpios = <&gpio3 0x19 0x01>;
			label = "BTN_START";
			linux,code = <0x2c1>;
		};
	};

	gpio_leds {
		compatible = "gpio-leds";
		pinctrl-names = "default";
		pinctrl-0 = <&led_pins>;

		disk-activity {
			label = "blue:disk";
			gpios = <&gpio0 0x00 0>;
			linux,default-trigger = "mmc0";
			/*
			battery-charging-or-full 
			battery-charging
			battery-full 
			battery-charging-blink-full-solid 
			usb-online ac-online 
			mmc0 
			mmc1 
			heartbeat 
			gpio 
			cpu0 
			cpu1 
			cpu2 
			cpu3
			*/
		};
		
		red-charge {
			label = "red:charge";
			gpios = <&gpio0 0x11 0>;
			//linux,default-state = off; 
		};
		
		charger {
			label = "orange:charger";
			gpios = <&gpio0 0x01 0>;
		};
	};

    //Motor gpio102 : GPIO3_A6
	/*vibrator {
		compatible = "gpio-vibrator";
		enable-gpios = <&gpio3 6 0x00>; 
		default-state = "disabled";
		status = "okay";
		vcc-supply = <&vcc_3v0>;
	};*/

	backlight: backlight {
		compatible = "pwm-backlight";
		power-supply = <&vcc_bl_boost>;
		pwms = <&pwm1 0 25000 0>;
		brightness-levels = <0x00 0x01 0x02 0x03 0x04 0x05 0x06 0x07 0x08 0x09 0x0a 0x0b 0x0c 0x0d 0x0e 0x0f 0x10 0x11 0x12 0x13 0x14 0x15 0x16 0x17 0x18 0x19 0x1a 0x1b 0x1c 0x1d 0x1e 0x1f 0x20 0x21 0x22 0x23 0x24 0x25 0x26 0x27 0x28 0x29 0x2a 0x2b 0x2c 0x2d 0x2e 0x2f 0x30 0x31 0x32 0x33 0x34 0x35 0x36 0x37 0x38 0x39 0x3a 0x3b 0x3c 0x3d 0x3e 0x3f 0x40 0x41 0x42 0x43 0x44 0x45 0x46 0x47 0x48 0x49 0x4a 0x4b 0x4c 0x4d 0x4e 0x4f 0x50 0x51 0x52 0x53 0x54 0x55 0x56 0x57 0x58 0x59 0x5a 0x5b 0x5c 0x5d 0x5e 0x5f 0x60 0x61 0x62 0x63 0x64 0x65 0x66 0x67 0x68 0x69 0x6a 0x6b 0x6c 0x6d 0x6e 0x6f 0x70 0x71 0x72 0x73 0x74 0x75 0x76 0x77 0x78 0x79 0x7a 0x7b 0x7c 0x7d 0x7e 0x7f 0x80 0x81 0x82 0x83 0x84 0x85 0x86 0x87 0x88 0x89 0x8a 0x8b 0x8c 0x8d 0x8e 0x8f 0x90 0x91 0x92 0x93 0x94 0x95 0x96 0x97 0x98 0x99 0x9a 0x9b 0x9c 0x9d 0x9e 0x9f 0xa0 0xa1 0xa2 0xa3 0xa4 0xa5 0xa6 0xa7 0xa8 0xa9 0xaa 0xab 0xac 0xad 0xae 0xaf 0xb0 0xb1 0xb2 0xb3 0xb4 0xb5 0xb6 0xb7 0xb8 0xb9 0xba 0xbb 0xbc 0xbd 0xbe 0xbf 0xc0 0xc1 0xc2 0xc3 0xc4 0xc5 0xc6 0xc7 0xc8 0xc9 0xca 0xcb 0xcc 0xcd 0xce 0xcf 0xd0 0xd1 0xd2 0xd3 0xd4 0xd5 0xd6 0xd7 0xd8 0xd9 0xda 0xdb 0xdc 0xdd 0xde 0xdf 0xe0 0xe1 0xe2 0xe3 0xe4 0xe5 0xe6 0xe7 0xe8 0xe9 0xea 0xeb 0xec 0xed 0xee 0xef 0xf0 0xf1 0xf2 0xf3 0xf4 0xf5 0xf6 0xf7 0xf8 0xf9 0xfa 0xfb 0xfc 0xfd 0xfe 0xff>;
		default-brightness-level = <200>;
		phandle = <0xa3>;
	};

	/*charge-animation {
		compatible = "rockchip,uboot-charge";
		rockchip,uboot-charge-on = <0x01>;
		rockchip,android-charge-on = <0x00>;
		rockchip,uboot-exit-charge-auto = <0x01>;
		rockchip,uboot-exit-charge-voltage = <0xd7a>;
		rockchip,uboot-low-power-voltage = <0x00>;
		rockchip,screen-on-voltage = <0xdac>;
		status = "okay";
	};*/

	rk817-sound {
		compatible = "simple-audio-card";
		simple-audio-card,format = "i2s";
		simple-audio-card,name = "rockchip,rk817-codec";
		simple-audio-card,mclk-fs = <256>;
		//simple-audio-card,widgets = "Microphone", "Mic Jack", "Headphone", "Headphone Jack";
		//simple-audio-card,routing = "MIC_IN", "Mic Jack", "Headphone Jack", "HPOL", "Headphone Jack", "HPOR";
		
		simple-audio-card,widgets =
			"Microphone", "Mic Jack",
			"Headphone", "Headphone Jack",
			"Speaker", "Speaker";

		/*simple-audio-card,routing =
			"MICL", "Mic Jack",
			"Headphone Jack", "HPOL",
			"Headphone Jack", "HPOR",
			"Int Speaker", "SPKO";
		*/

		simple-audio-card,hp-det-gpio = <&gpio2 22 0x01>;
		//simple-audio-card,spk-ctl-gpios = <&gpio3 7 0x00>;
		pinctrl-names = "default";
		pinctrl-0 = <&hp_det &spk_ctl_pin>;

		simple-audio-card,cpu {
			sound-dai = <&i2s1_2ch>; 
		};

		simple-audio-card,codec {
			sound-dai = <&rk817_codec>; 
		};
	};

	/* dummy usb for rk817 charger. OTG port u2phy is not actually a charging port */
	usb_extcon_charge: usb-extcon-charge {
		compatible = "linux,extcon-usb-gpio";

		/* External charger IC status */
		vbus-gpio = <&gpio3 5 0x00>; //Status from 4056 li-ion charger
		//vbus-gpio = <0>;
		/* No ID pin — this is NOT OTG */
		//id-gpio = <&gpio3 5 0x00>;

		//debounce = <20>;
	};

	/*System vcc bus, RK817 feeds this from battery&charger*/
	vccsys: vccsys {
		compatible = "regulator-fixed";
		regulator-name = "vcc3v8_sys";
		regulator-always-on;
		regulator-boot-on;
		regulator-min-microvolt = <3800000>;
		regulator-max-microvolt = <3800000>;
	};

	/*LCD io voltage, 1.8v LDO from vcc_3v0*/
	vcc18_lcd0: vcc18_lcd0 {
		compatible = "regulator-fixed";
		regulator-name = "vcc18_lcd0_n";
		regulator-min-microvolt = <1800000>;
		regulator-max-microvolt = <1800000>;
		//gpio = <&gpio0 13 0x00>;
		//pinctrl-0 = <&vcc18_lcd_n>; //LCD enable
		//pinctrl-names = "default";
		enable-active-high;
		regulator-boot-on;
		vin-supply = <&vcc_3v0>;

		regulator-state-mem {
			regulator-off-in-suspend;
		};
	};
	
	/*LCD vcc voltage, 2.8v LDO from vcc_3v0*/
	vcc28_lcd0: vcc28_lcd0 {
		compatible = "regulator-fixed";
		regulator-name = "vcc28_lcd0_n";
		regulator-min-microvolt = <2800000>;
		regulator-max-microvolt = <2800000>;
		gpio = <&gpio0 13 0x00>; //LCD enable
		pinctrl-0 = <&vcc18_lcd_n>;
		pinctrl-names = "default";
		enable-active-high;
		regulator-boot-on;
		vin-supply = <&vcc_3v0>;

		regulator-state-mem {
			regulator-off-in-suspend;
		};
	};
	
	/*Boost converter for backlight string, pwm controlled*/
	vcc_bl_boost: vcc_bl_boost {
		compatible = "regulator-fixed";
		regulator-name = "vcc_bl_boost";
		regulator-min-microvolt = <17000000>;
		regulator-max-microvolt = <17000000>;
		//gpio = <&gpio0 16 0x00>; //backlight pwm
		regulator-boot-on;
		vin-supply = <&vccsys>;
	};
	
	/* load switch or ldo that controls dcdc_boost -> usb-c otg port power path */
	vcc_host: vcc_host {
		compatible = "regulator-fixed";
		regulator-name = "vcc_host";
		regulator-min-microvolt = <5000000>;
		regulator-max-microvolt = <5000000>;
		gpio = <&gpio3 4 0x00>; //otg-gpio
		pinctrl-0 = <&vcc5_usb>;
		pinctrl-names = "default";
		enable-active-high;
		regulator-always-on; //if otg starts to work, disable this to save power
		regulator-boot-on;
		//vin-supply = <&dcdc_boost>; //Disable, rk817 initialized much later on boot
		
		regulator-state-mem {
			regulator-off-in-suspend;
		};
	};

	__symbols__ {
		ddr_timing = "/ddr_timing";
		ddr3_params = "/ddr3-params";
		ddr4_params = "/ddr4-params";
		lpddr2_params = "/lpddr2-params";
		lpddr3_params = "/lpddr3-params";
		lpddr4_params = "/lpddr4-params";
		cpu0 = "/cpus/cpu@0";
		cpu1 = "/cpus/cpu@1";
		cpu2 = "/cpus/cpu@2";
		cpu3 = "/cpus/cpu@3";
		CPU_SLEEP = "/cpus/idle-states/cpu-sleep";
		CLUSTER_SLEEP = "/cpus/idle-states/cluster-sleep";
		cpu0_opp_table = "/cpu0-opp-table";
		bus_soc = "/bus-soc";
		bus_apll = "/bus-apll";
		bus_apll_opp_table = "/bus-apll-opp-table";
		display_subsystem = "/display-subsystem";
		route_lvds = "/display-subsystem/route/route-lvds";
		route_dsi = "/display-subsystem/route/route-dsi";
		route_rgb = "/display-subsystem/route/route-rgb";
		gmac_clkin = "/external-gmac-clock";
		rockchip_suspend = "/rockchip-suspend";
		xin24m = "/xin24m";
		xin32k = "/xin32k";
		pmu = "/power-management@ff000000";
		power = "/power-management@ff000000/power-controller";
		pmugrf = "/syscon@ff010000";
		pmu_io_domains = "/syscon@ff010000/io-domains";
		pmu_pvtm = "/syscon@ff010000/pmu-pvtm";
		uart0 = "/serial@ff030000";
		i2s0_8ch = "/i2s@ff060000";
		i2s1_2ch = "/i2s@ff070000";
		i2s2_2ch = "/i2s@ff080000";
		pdm = "/pdm@ff0a0000";
		crypto = "/crypto@ff0b0000";
		rng = "/rng@ff0b0000";
		gic = "/interrupt-controller@ff131000";
		grf = "/syscon@ff140000";
		io_domains = "/syscon@ff140000/io-domains";
		lvds = "/syscon@ff140000/lvds";
		lvds_in_vopb = "/syscon@ff140000/lvds/ports/port@0/endpoint@0";
		rgb = "/syscon@ff140000/rgb";
		rgb_in_vopb = "/syscon@ff140000/rgb/ports/port@0/endpoint@0";
		core_grf = "/syscon@ff148000";
		pvtm = "/syscon@ff148000/pvtm";
		uart1 = "/serial@ff158000";
		uart2 = "/serial@ff160000";
		uart3 = "/serial@ff168000";
		uart4 = "/serial@ff170000";
		uart5 = "/serial@ff178000";
		i2c0 = "/i2c@ff180000";
		rk817 = "/i2c@ff180000/pmic@20";
		pinctrl_rk8xx = "/i2c@ff180000/pmic@20/pinctrl_rk8xx";
		rk817_ts_gpio1 = "/i2c@ff180000/pmic@20/pinctrl_rk8xx/rk817_ts_gpio1";
		rk817_gt_gpio2 = "/i2c@ff180000/pmic@20/pinctrl_rk8xx/rk817_gt_gpio2";
		rk817_pin_ts = "/i2c@ff180000/pmic@20/pinctrl_rk8xx/rk817_pin_ts";
		rk817_pin_gt = "/i2c@ff180000/pmic@20/pinctrl_rk8xx/rk817_pin_gt";
		rk817_slppin_null = "/i2c@ff180000/pmic@20/pinctrl_rk8xx/rk817_slppin_null";
		rk817_slppin_slp = "/i2c@ff180000/pmic@20/pinctrl_rk8xx/rk817_slppin_slp";
		rk817_slppin_pwrdn = "/i2c@ff180000/pmic@20/pinctrl_rk8xx/rk817_slppin_pwrdn";
		rk817_slppin_rst = "/i2c@ff180000/pmic@20/pinctrl_rk8xx/rk817_slppin_rst";
		vdd_logic = "/i2c@ff180000/pmic@20/regulators/DCDC_REG1";
		vdd_arm = "/i2c@ff180000/pmic@20/regulators/DCDC_REG2";
		vcc_ddr = "/i2c@ff180000/pmic@20/regulators/DCDC_REG3";
		vcc_3v0 = "/i2c@ff180000/pmic@20/regulators/DCDC_REG4";
		vcc_1v0 = "/i2c@ff180000/pmic@20/regulators/LDO_REG1";
		vcc1v8_soc = "/i2c@ff180000/pmic@20/regulators/LDO_REG2";
		vcc1v0_soc = "/i2c@ff180000/pmic@20/regulators/LDO_REG3";
		vcc3v0_pmu = "/i2c@ff180000/pmic@20/regulators/LDO_REG4";
		vccio_sd = "/i2c@ff180000/pmic@20/regulators/LDO_REG5";
		vcc_sd = "/i2c@ff180000/pmic@20/regulators/LDO_REG6";
		vccio_mmc = "/i2c@ff180000/pmic@20/regulators/LDO_REG7";
		vcc_mmc = "/i2c@ff180000/pmic@20/regulators/LDO_REG8";
		vdd1v5_dvp = "/i2c@ff180000/pmic@20/regulators/LDO_REG9";
		dcdc_boost = "/i2c@ff180000/pmic@20/regulators/BOOST";
		otg_switch = "/i2c@ff180000/pmic@20/regulators/OTG_SWITCH";
		rk817_codec = "/i2c@ff180000/pmic@20/codec";
		i2c1 = "/i2c@ff190000";
		i2c2 = "/i2c@ff1a0000";
		i2c3 = "/i2c@ff1b0000";
		spi0 = "/spi@ff1d0000";
		spi1 = "/spi@ff1d8000";
		wdt = "/watchdog@ff1e0000";
		pwm0 = "/pwm@ff200000";
		pwm1 = "/pwm@ff200010";
		pwm2 = "/pwm@ff200020";
		pwm3 = "/pwm@ff200030";
		pwm4 = "/pwm@ff208000";
		pwm5 = "/pwm@ff208010";
		pwm6 = "/pwm@ff208020";
		pwm7 = "/pwm@ff208030";
		rktimer = "/rktimer@ff210000";
		dmac = "/amba/dmac@ff240000";
		thermal_zones = "/thermal-zones";
		soc_thermal = "/thermal-zones/soc-thermal";
		threshold = "/thermal-zones/soc-thermal/trips/trip-point-0";
		target = "/thermal-zones/soc-thermal/trips/trip-point-1";
		soc_crit = "/thermal-zones/soc-thermal/trips/soc-crit";
		gpu_thermal = "/thermal-zones/gpu-thermal";
		gpu_target = "/thermal-zones/gpu-thermal/trips/gpu-target";
		tsadc = "/tsadc@ff280000";
		saradc = "/saradc@ff288000";
		otp = "/otp@ff290000";
		otp_id = "/otp@ff290000/id@7";
		cpu_leakage = "/otp@ff290000/cpu-leakage@17";
		performance = "/otp@ff290000/performance@1e";
		cru = "/clock-controller@ff2b0000";
		cpu_boost = "/cpu-boost@ff2b8000";
		pmucru = "/pmu-clock-controller@ff2bc000";
		usb2phy_grf = "/syscon@ff2c0000";
		u2phy = "/syscon@ff2c0000/usb2-phy@100";
		u2phy_host = "/syscon@ff2c0000/usb2-phy@100/host-port";
		u2phy_otg = "/syscon@ff2c0000/usb2-phy@100/otg-port";
		video_phy = "/video-phy@ff2e0000";
		mipi_dphy_rx0 = "/mipi-dphy-rx0@ff2f0000";
		usb20_otg = "/usb@ff300000";
		usb_host0_ehci = "/usb@ff340000";
		usb_host0_ohci = "/usb@ff350000";
		gmac = "/ethernet@ff360000";
		sdmmc = "/dwmmc@ff370000";
		sdio = "/dwmmc@ff380000";
		emmc = "/dwmmc@ff390000";
		nandc0 = "/nandc@ff3b0000";
		sfc = "/sfc@ff3a0000";
		gpu = "/gpu@ff400000";
		gpu_opp_table = "/gpu-opp-table";
		hevc = "/hevc_service@ff440000";
		vpu = "/vpu_service@ff442000";
		vpu_combo = "/vpu_combo";
		hevc_mmu = "/iommu@ff440440";
		vpu_mmu = "/iommu@ff442800";
		dsi = "/dsi@ff450000";
		dsi_in_vopb = "/dsi@ff450000/ports/port@0/endpoint@0";
		timing0 = "/dsi@ff450000/panel@0/display-timings/adjust";
		timing1 = "/dsi@ff450000/panel@0/display-timings/origin";
		vopb = "/vop@ff460000";
		vopb_out = "/vop@ff460000/port";
		vopb_out_lvds = "/vop@ff460000/port/endpoint@0";
		vopb_out_dsi = "/vop@ff460000/port/endpoint@1";
		vopb_out_rgb = "/vop@ff460000/port/endpoint@2";
		vopb_mmu = "/iommu@ff460f00";
		rk_rga = "/rk_rga@ff480000";
		cif = "/cif@ff490000";
		cif_new = "/cif-new@ff490000";
		vip_mmu = "/iommu@ff490800";
		rk_isp = "/rk_isp@ff4a0000";
		rkisp1 = "/rkisp1@ff4a0000";
		isp_mmu = "/iommu@ff4a8000";
		qos_gmac = "/qos@ff518000";
		qos_gpu = "/qos@ff520000";
		qos_sdmmc = "/qos@ff52c000";
		qos_emmc = "/qos@ff538000";
		qos_nand = "/qos@ff538080";
		qos_sdio = "/qos@ff538100";
		qos_sfc = "/qos@ff538180";
		qos_usb_host = "/qos@ff540000";
		qos_usb_otg = "/qos@ff540080";
		qos_isp_128 = "/qos@ff548000";
		qos_isp_rd = "/qos@ff548080";
		qos_isp_wr = "/qos@ff548100";
		qos_isp_m1 = "/qos@ff548180";
		qos_vip = "/qos@ff548200";
		qos_rga_rd = "/qos@ff550000";
		qos_rga_wr = "/qos@ff550080";
		qos_vop_m0 = "/qos@ff550100";
		qos_vop_m1 = "/qos@ff550180";
		qos_vpu = "/qos@ff558000";
		qos_vpu_r128 = "/qos@ff558080";
		dfi = "/dfi@ff610000";
		dmc = "/dmc";
		ddr_power_model = "/dmc/ddr_power_model";
		dmc_fsp = "/dmc-fsp";
		dmc_opp_table = "/dmc-opp-table";
		rockchip_system_monitor = "/rockchip-system-monitor";
		pinctrl = "/pinctrl";
		gpio0 = "/pinctrl/gpio0@ff040000";
		gpio1 = "/pinctrl/gpio1@ff250000";
		gpio2 = "/pinctrl/gpio2@ff260000";
		gpio3 = "/pinctrl/gpio3@ff270000";
		pcfg_pull_up = "/pinctrl/pcfg-pull-up";
		pcfg_pull_down = "/pinctrl/pcfg-pull-down";
		pcfg_pull_none = "/pinctrl/pcfg-pull-none";
		pcfg_pull_none_2ma = "/pinctrl/pcfg-pull-none-2ma";
		pcfg_pull_up_2ma = "/pinctrl/pcfg-pull-up-2ma";
		pcfg_pull_up_4ma = "/pinctrl/pcfg-pull-up-4ma";
		pcfg_pull_none_4ma = "/pinctrl/pcfg-pull-none-4ma";
		pcfg_pull_down_4ma = "/pinctrl/pcfg-pull-down-4ma";
		pcfg_pull_none_8ma = "/pinctrl/pcfg-pull-none-8ma";
		pcfg_pull_up_8ma = "/pinctrl/pcfg-pull-up-8ma";
		pcfg_pull_none_12ma = "/pinctrl/pcfg-pull-none-12ma";
		pcfg_pull_up_12ma = "/pinctrl/pcfg-pull-up-12ma";
		pcfg_pull_none_smt = "/pinctrl/pcfg-pull-none-smt";
		pcfg_output_high = "/pinctrl/pcfg-output-high";
		pcfg_output_low = "/pinctrl/pcfg-output-low";
		pcfg_input_high = "/pinctrl/pcfg-input-high";
		pcfg_input = "/pinctrl/pcfg-input";
		i2c0_xfer = "/pinctrl/i2c0/i2c0-xfer";
		i2c1_xfer = "/pinctrl/i2c1/i2c1-xfer";
		i2c2_xfer = "/pinctrl/i2c2/i2c2-xfer";
		i2c3_xfer = "/pinctrl/i2c3/i2c3-xfer";
		tsadc_otp_gpio = "/pinctrl/tsadc/tsadc-otp-gpio";
		tsadc_otp_out = "/pinctrl/tsadc/tsadc-otp-out";
		uart0_xfer = "/pinctrl/uart0/uart0-xfer";
		uart0_cts = "/pinctrl/uart0/uart0-cts";
		uart0_rts = "/pinctrl/uart0/uart0-rts";
		uart0_rts_gpio = "/pinctrl/uart0/uart0-rts-gpio";
		uart1_xfer = "/pinctrl/uart1/uart1-xfer";
		uart1_cts = "/pinctrl/uart1/uart1-cts";
		uart1_rts = "/pinctrl/uart1/uart1-rts";
		uart1_rts_gpio = "/pinctrl/uart1/uart1-rts-gpio";
		uart2m0_xfer = "/pinctrl/uart2-m0/uart2m0-xfer";
		uart2m1_xfer = "/pinctrl/uart2-m1/uart2m1-xfer";
		uart3m0_xfer = "/pinctrl/uart3-m0/uart3m0-xfer";
		uart3m0_cts = "/pinctrl/uart3-m0/uart3m0-cts";
		uart3m0_rts = "/pinctrl/uart3-m0/uart3m0-rts";
		uart3m0_rts_gpio = "/pinctrl/uart3-m0/uart3m0-rts-gpio";
		uart3m1_xfer = "/pinctrl/uart3-m1/uart3m1-xfer";
		uart3m1_cts = "/pinctrl/uart3-m1/uart3m1-cts";
		uart3m1_rts = "/pinctrl/uart3-m1/uart3m1-rts";
		uart3m1_rts_gpio = "/pinctrl/uart3-m1/uart3m1-rts-gpio";
		uart4_xfer = "/pinctrl/uart4/uart4-xfer";
		uart4_cts = "/pinctrl/uart4/uart4-cts";
		uart4_rts = "/pinctrl/uart4/uart4-rts";
		uart5_xfer = "/pinctrl/uart5/uart5-xfer";
		uart5_cts = "/pinctrl/uart5/uart5-cts";
		uart5_rts = "/pinctrl/uart5/uart5-rts";
		spi0_clk = "/pinctrl/spi0/spi0-clk";
		spi0_csn = "/pinctrl/spi0/spi0-csn";
		spi0_miso = "/pinctrl/spi0/spi0-miso";
		spi0_mosi = "/pinctrl/spi0/spi0-mosi";
		spi0_clk_hs = "/pinctrl/spi0/spi0-clk-hs";
		spi0_miso_hs = "/pinctrl/spi0/spi0-miso-hs";
		spi0_mosi_hs = "/pinctrl/spi0/spi0-mosi-hs";
		spi1_clk = "/pinctrl/spi1/spi1-clk";
		spi1_csn0 = "/pinctrl/spi1/spi1-csn0";
		spi1_csn1 = "/pinctrl/spi1/spi1-csn1";
		spi1_miso = "/pinctrl/spi1/spi1-miso";
		spi1_mosi = "/pinctrl/spi1/spi1-mosi";
		spi1_clk_hs = "/pinctrl/spi1/spi1-clk-hs";
		spi1_miso_hs = "/pinctrl/spi1/spi1-miso-hs";
		spi1_mosi_hs = "/pinctrl/spi1/spi1-mosi-hs";
		pdm_clk0m0 = "/pinctrl/pdm/pdm-clk0m0";
		pdm_clk0m1 = "/pinctrl/pdm/pdm-clk0m1";
		pdm_clk1 = "/pinctrl/pdm/pdm-clk1";
		pdm_sdi0m0 = "/pinctrl/pdm/pdm-sdi0m0";
		pdm_sdi0m1 = "/pinctrl/pdm/pdm-sdi0m1";
		pdm_sdi1 = "/pinctrl/pdm/pdm-sdi1";
		pdm_sdi2 = "/pinctrl/pdm/pdm-sdi2";
		pdm_sdi3 = "/pinctrl/pdm/pdm-sdi3";
		pdm_clk0m0_sleep = "/pinctrl/pdm/pdm-clk0m0-sleep";
		pdm_clk0m_sleep1 = "/pinctrl/pdm/pdm-clk0m1-sleep";
		pdm_clk1_sleep = "/pinctrl/pdm/pdm-clk1-sleep";
		pdm_sdi0m0_sleep = "/pinctrl/pdm/pdm-sdi0m0-sleep";
		pdm_sdi0m1_sleep = "/pinctrl/pdm/pdm-sdi0m1-sleep";
		pdm_sdi1_sleep = "/pinctrl/pdm/pdm-sdi1-sleep";
		pdm_sdi2_sleep = "/pinctrl/pdm/pdm-sdi2-sleep";
		pdm_sdi3_sleep = "/pinctrl/pdm/pdm-sdi3-sleep";
		i2s0_8ch_mclk = "/pinctrl/i2s0/i2s0-8ch-mclk";
		i2s0_8ch_sclktx = "/pinctrl/i2s0/i2s0-8ch-sclktx";
		i2s0_8ch_sclkrx = "/pinctrl/i2s0/i2s0-8ch-sclkrx";
		i2s0_8ch_lrcktx = "/pinctrl/i2s0/i2s0-8ch-lrcktx";
		i2s0_8ch_lrckrx = "/pinctrl/i2s0/i2s0-8ch-lrckrx";
		i2s0_8ch_sdo0 = "/pinctrl/i2s0/i2s0-8ch-sdo0";
		i2s0_8ch_sdo1 = "/pinctrl/i2s0/i2s0-8ch-sdo1";
		i2s0_8ch_sdo2 = "/pinctrl/i2s0/i2s0-8ch-sdo2";
		i2s0_8ch_sdo3 = "/pinctrl/i2s0/i2s0-8ch-sdo3";
		i2s0_8ch_sdi0 = "/pinctrl/i2s0/i2s0-8ch-sdi0";
		i2s0_8ch_sdi1 = "/pinctrl/i2s0/i2s0-8ch-sdi1";
		i2s0_8ch_sdi2 = "/pinctrl/i2s0/i2s0-8ch-sdi2";
		i2s0_8ch_sdi3 = "/pinctrl/i2s0/i2s0-8ch-sdi3";
		i2s1_2ch_mclk = "/pinctrl/i2s1/i2s1-2ch-mclk";
		i2s1_2ch_sclk = "/pinctrl/i2s1/i2s1-2ch-sclk";
		i2s1_2ch_lrck = "/pinctrl/i2s1/i2s1-2ch-lrck";
		i2s1_2ch_sdi = "/pinctrl/i2s1/i2s1-2ch-sdi";
		i2s1_2ch_sdo = "/pinctrl/i2s1/i2s1-2ch-sdo";
		i2s2_2ch_mclk = "/pinctrl/i2s2/i2s2-2ch-mclk";
		i2s2_2ch_sclk = "/pinctrl/i2s2/i2s2-2ch-sclk";
		i2s2_2ch_lrck = "/pinctrl/i2s2/i2s2-2ch-lrck";
		i2s2_2ch_sdi = "/pinctrl/i2s2/i2s2-2ch-sdi";
		i2s2_2ch_sdo = "/pinctrl/i2s2/i2s2-2ch-sdo";
		sdmmc_clk = "/pinctrl/sdmmc/sdmmc-clk";
		sdmmc_cmd = "/pinctrl/sdmmc/sdmmc-cmd";
		sdmmc_det = "/pinctrl/sdmmc/sdmmc-det";
		sdmmc_bus1 = "/pinctrl/sdmmc/sdmmc-bus1";
		sdmmc_bus4 = "/pinctrl/sdmmc/sdmmc-bus4";
		sdmmc_gpio = "/pinctrl/sdmmc/sdmmc-gpio";
		sdio_clk = "/pinctrl/sdio/sdio-clk";
		sdio_cmd = "/pinctrl/sdio/sdio-cmd";
		sdio_det = "/pinctrl/sdio/sdio-det";
		sdio_bus4 = "/pinctrl/sdio/sdio-bus4";
		sdio_gpio = "/pinctrl/sdio/sdio-gpio";
		emmc_clk = "/pinctrl/emmc/emmc-clk";
		emmc_cmd = "/pinctrl/emmc/emmc-cmd";
		emmc_pwren = "/pinctrl/emmc/emmc-pwren";
		emmc_rstnout = "/pinctrl/emmc/emmc-rstnout";
		emmc_bus1 = "/pinctrl/emmc/emmc-bus1";
		emmc_bus4 = "/pinctrl/emmc/emmc-bus4";
		emmc_bus8 = "/pinctrl/emmc/emmc-bus8";
		flash_cs0 = "/pinctrl/flash/flash-cs0";
		flash_rdy = "/pinctrl/flash/flash-rdy";
		flash_dqs = "/pinctrl/flash/flash-dqs";
		flash_ale = "/pinctrl/flash/flash-ale";
		flash_cle = "/pinctrl/flash/flash-cle";
		flash_wrn = "/pinctrl/flash/flash-wrn";
		flash_csl = "/pinctrl/flash/flash-csl";
		flash_rdn = "/pinctrl/flash/flash-rdn";
		flash_bus8 = "/pinctrl/flash/flash-bus8";
		lcdc_m0_rgb_pins = "/pinctrl/lcdc/lcdc-m0-rgb-pins";
		lcdc_m0_sleep_pins = "/pinctrl/lcdc/lcdc-m0-sleep-pins";
		lcdc_m1_rgb_pins = "/pinctrl/lcdc/lcdc-m1-rgb-pins";
		lcdc_m1_sleep_pins = "/pinctrl/lcdc/lcdc-m1-sleep-pins";
		pwm0_pin = "/pinctrl/pwm0/pwm0-pin";
		pwm1_pin = "/pinctrl/pwm1/pwm1-pin";
		pwm2_pin = "/pinctrl/pwm2/pwm2-pin";
		pwm3_pin = "/pinctrl/pwm3/pwm3-pin";
		pwm4_pin = "/pinctrl/pwm4/pwm4-pin";
		pwm5_pin = "/pinctrl/pwm5/pwm5-pin";
		pwm6_pin = "/pinctrl/pwm6/pwm6-pin";
		pwm7_pin = "/pinctrl/pwm7/pwm7-pin";
		rmii_pins = "/pinctrl/gmac/rmii-pins";
		mac_refclk_12ma = "/pinctrl/gmac/mac-refclk-12ma";
		mac_refclk = "/pinctrl/gmac/mac-refclk";
		cif_clkout_m0 = "/pinctrl/cif-m0/cif-clkout-m0";
		dvp_d2d9_m0 = "/pinctrl/cif-m0/dvp-d2d9-m0";
		dvp_d0d1_m0 = "/pinctrl/cif-m0/dvp-d0d1-m0";
		dvp_d10d11_m0 = "/pinctrl/cif-m0/d10-d11-m0";
		cif_clkout_m1 = "/pinctrl/cif-m1/cif-clkout-m1";
		dvp_d2d9_m1 = "/pinctrl/cif-m1/dvp-d2d9-m1";
		dvp_d0d1_m1 = "/pinctrl/cif-m1/dvp-d0d1-m1";
		dvp_d10d11_m1 = "/pinctrl/cif-m1/d10-d11-m1";
		isp_prelight = "/pinctrl/isp/isp-prelight";
		pmic_int = "/pinctrl/pmic/pmic_int";
		soc_slppin_gpio = "/pinctrl/pmic/soc_slppin_gpio";
		soc_slppin_slp = "/pinctrl/pmic/soc_slppin_slp";
		soc_slppin_rst = "/pinctrl/pmic/soc_slppin_rst";
		vcc18_lcd_n = "/pinctrl/vcc18-lcd/vcc18-lcd-n";
		vcc5_usb = "/pinctrl/vcc5-usb/vcc5-usb";
		u2phy_host_pin = "/pinctrl/u2phy/u2phy-host";
		u2phy_otg_pin = "/pinctrl/u2phy/u2phy-otg";
		motor_pin = "/pinctrl/haptic/motor-pin";
		led_pins = "/pinctrl/leds/led-pins";
		btn_pins = "/pinctrl/btns/btn-pins";
		amux_pins = "/pinctrl/btns/amux-pins";
		rumble_pin = "/pinctrl/btns/rumble-pin";
		hp_det = "/pinctrl/headphone/hp-det";
		spk_ctl_pin = "/pinctrl/headphone/spk-ctl-pin";
		drm_logo = "/reserved-memory/drm-logo@00000000";
		ramoops_mem = "/reserved-memory/region@110000";
		vol_keys = "/rg351-keys";
		joypad = "/odroidgo3-joypad";
		backlight = "/backlight";
		vibrator = "/gpio-vibrator";
		leds = "/gpio_leds";
		vccsys = "/vccsys";
		vcc18_lcd0 = "/vcc18_lcd0";
		vcc28_lcd0 = "/vcc28_lcd0";
		vcc_bl_boost = "/vcc_bl_boost";
		usb_extcon_charge = "/usb-extcon-charge";
		vcc_host = "/vcc_host";
	};
};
